VERSION "HNPBNNNYNNNNNNNNNNNNNNNNNNNNNNNNYNYYYYYYYY>4>%%%/4>'%**4YYY///"

NS_ :

BS_:

BU_: TPM TCM SCCM RF_HUB PTS ORC IC HaLF ETM ESM ESC EPS ECM Diagnost DTCM DASM CBC AFLS ADCM

BO_ 820 CBC_PT1: 8 CBC
 SG_ OR_SW_PSD : 0|2@1+ (1,0) [0|0] ""  ECM
 SG_ FT_FOG_RQ : 2|1@1+ (1,0) [0|0] ""  HaLF,AFLS,IC
 SG_ R_FOG_RQ : 3|1@1+ (1,0) [0|0] ""  IC
 SG_ REV_GEAR : 4|1@1+ (1,0) [0|0] ""  EPS,ORC,DTCM,ESC,TPM,PTS,IC,RF_HUB
 SG_ DR_LK_STAT : 5|2@1+ (1,0) [0|0] ""  RF_HUB
 SG_ IHC_ACT : 7|1@1+ (1,0) [0|0] ""  IC
 SG_ FOB_SrchRq : 8|2@1+ (1,0) [0|0] ""  RF_HUB
 SG_ HbrntnAct : 10|1@1+ (1,0) [0|0] ""  IC,RF_HUB
 SG_ ElecDrLkFT_LT : 11|1@1+ (1,0) [0|0] ""  ETM,RF_HUB
 SG_ ElecDrLkFT_RT : 12|1@1+ (1,0) [0|0] ""  ETM,RF_HUB
 SG_ AHB_SAE_Md : 13|1@1+ (1,0) [0|0] ""  IC
 SG_ AHB_ACT : 14|1@1+ (1,0) [0|0] ""  IC
 SG_ WSH_OUT_FLT : 15|1@1+ (1,0) [0|0] "" Vector__XXX
 SG_ PARK_LMP_ON : 16|1@1+ (1,0) [0|0] ""  IC
 SG_ DRV_AJAR : 17|1@1+ (1,0) [0|0] ""  TCM,ECM,DASM,ESC,IC,RF_HUB
 SG_ PSG_AJAR : 18|1@1+ (1,0) [0|0] ""  ORC,ECM,DASM,ESC,IC,RF_HUB
 SG_ L_R_AJAR : 19|1@1+ (1,0) [0|0] ""  ECM,ESC,IC,RF_HUB
 SG_ R_R_AJAR : 20|1@1+ (1,0) [0|0] ""  ECM,ESC,IC,RF_HUB
 SG_ FG_AJAR : 21|1@1+ (1,0) [0|0] ""  ECM,ESC,IC,RF_HUB
 SG_ TLG_AJAR : 22|1@1+ (1,0) [0|0] ""  ECM,ESC,IC,RF_HUB
 SG_ PARK_BRK_EGD : 23|1@1+ (1,0) [0|0] ""  ECM,DASM,ESC,PTS,IC
 SG_ IGN_OFF_TIME_LNG : 27|12@0+ (1,0) [0|4080] "min"  DTCM,TCM,ECM,DASM,ESC,IC,RF_HUB
 SG_ SHIP_STAT : 28|2@1+ (1,0) [0|0] ""  ORC,TPM,PTS,IC,RF_HUB
 SG_ TurnInd_LT_ON : 30|1@1+ (1,0) [0|0] ""  HaLF,DASM,PTS,IC
 SG_ TurnInd_RT_ON : 31|1@1+ (1,0) [0|0] ""  HaLF,DASM,PTS,IC
 SG_ DAY_LGT_MD : 40|1@1+ (1,0) [0|0] ""  ESM,SCCM,AFLS,PTS,IC,RF_HUB
 SG_ DISP_SYNC : 41|1@1+ (1,0) [0|0] ""  PTS
 SG_ PTC_REL1_STAT : 42|2@1+ (1,0) [0|0] ""  ECM
 SG_ PTC_REL2_STAT : 44|2@1+ (1,0) [0|0] ""  ECM
 SG_ PTC_REL3_STAT : 46|2@1+ (1,0) [0|0] ""  ECM
 SG_ PANEL_INTS : 48|8@1+ (0.5,0) [0|100] "%"  ESM,SCCM,PTS,IC,RF_HUB
 SG_ FT_WPR_NOT_PRK : 56|1@1+ (1,0) [0|0] ""  DTCM,ECM,AFLS
 SG_ LOBEAM_ON : 57|1@1+ (1,0) [0|0] ""  HaLF,ECM,AFLS,TPM,IC
 SG_ HIBEAM_ON : 58|1@1+ (1,0) [0|0] ""  HaLF,ECM,AFLS,IC
 SG_ PoliceStlthMdAct : 59|1@1+ (1,0) [0|0] ""  IC,RF_HUB
 SG_ TPM_SW_Psd : 60|1@1+ (1,0) [0|0] ""  TPM,RF_HUB
 SG_ ThatchamCBC : 61|1@1+ (1,0) [0|0] ""  RF_HUB
 SG_ BRK_FLUID_LO : 62|1@1+ (1,0) [0|0] ""  ETM,ESC,IC
 SG_ WASH_FLUID_LO : 63|1@1+ (1,0) [0|0] ""  ETM,IC

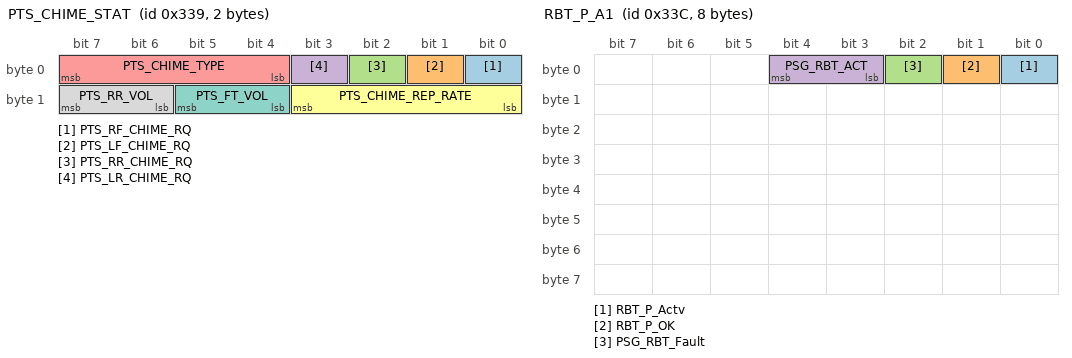
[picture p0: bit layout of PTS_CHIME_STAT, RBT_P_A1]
BO_ 825 PTS_CHIME_STAT: 2 PTS
 SG_ PTS_RF_CHIME_RQ : 0|1@1+ (1,0) [0|0] ""  CBC
 SG_ PTS_LF_CHIME_RQ : 1|1@1+ (1,0) [0|0] ""  CBC
 SG_ PTS_RR_CHIME_RQ : 2|1@1+ (1,0) [0|0] ""  CBC
 SG_ PTS_LR_CHIME_RQ : 3|1@1+ (1,0) [0|0] ""  CBC
 SG_ PTS_CHIME_TYPE : 4|4@1+ (1,0) [0|0] ""  CBC
 SG_ PTS_CHIME_REP_RATE : 8|4@1+ (1,0) [0|15] "Hz"  CBC
 SG_ PTS_FT_VOL : 12|2@1+ (1,0) [0|0] ""  CBC
 SG_ PTS_RR_VOL : 14|2@1+ (1,0) [0|0] ""  CBC

BO_ 826 PTS_1: 8 PTS
 SG_ PTS_DispRq : 0|1@1+ (1,0) [0|0] ""  IC
 SG_ PTS_CFG_STAT : 1|2@1+ (1,0) [0|0] ""  IC,CBC
 SG_ PTS_FT_NA : 3|1@1+ (1,0) [0|0] ""  IC
 SG_ PTS_RR_NA : 4|1@1+ (1,0) [0|0] ""  IC
 SG_ PTS_SRV_RQ : 5|1@1+ (1,0) [0|0] ""  IC
 SG_ PTS_MUTE_RQ : 6|1@1+ (1,0) [0|0] ""  CBC
 SG_ PTS_WARN : 7|1@1+ (1,0) [0|0] ""  IC,CBC
 SG_ PTS_AlrFL : 8|4@1+ (1,0) [0|0] ""  IC
 SG_ PTS_SoundFL : 12|2@1+ (1,0) [0|0] "" Vector__XXX
 SG_ PTS_GraphicFL : 14|2@1+ (1,0) [0|0] ""  IC
 SG_ PTS_AlrFR : 16|4@1+ (1,0) [0|0] ""  IC
 SG_ PTS_SoundFR : 20|2@1+ (1,0) [0|0] "" Vector__XXX
 SG_ PTS_GraphicFR : 22|2@1+ (1,0) [0|0] ""  IC
 SG_ PTS_AlrRL : 24|4@1+ (1,0) [0|0] ""  IC,CBC
 SG_ PTS_SoundRL : 28|2@1+ (1,0) [0|0] "" Vector__XXX
 SG_ PTS_GraphicRL : 30|2@1+ (1,0) [0|0] ""  IC
 SG_ PTS_AlrRR : 32|4@1+ (1,0) [0|0] ""  IC,CBC
 SG_ PTS_SoundRR : 36|2@1+ (1,0) [0|0] "" Vector__XXX
 SG_ PTS_GraphicRR : 38|2@1+ (1,0) [0|0] ""  IC
 SG_ PTS_AlrFC : 40|4@1+ (1,0) [0|0] ""  IC
 SG_ PTS_SoundFC : 44|2@1+ (1,0) [0|0] "" Vector__XXX
 SG_ PTS_GraphicFC : 46|2@1+ (1,0) [0|0] ""  IC
 SG_ PTS_AlrRC : 48|4@1+ (1,0) [0|0] ""  IC,CBC
 SG_ PTS_SoundRC : 52|2@1+ (1,0) [0|0] "" Vector__XXX
 SG_ PTS_GraphicRC : 54|2@1+ (1,0) [0|0] ""  IC
 SG_ PTS_FT_RDY : 56|1@1+ (1,0) [0|0] ""  IC
 SG_ PTS_RR_RDY : 57|1@1+ (1,0) [0|0] ""  IC
 SG_ PTS_FT_SRV : 58|1@1+ (1,0) [0|0] ""  IC
 SG_ PTS_RR_SRV : 59|1@1+ (1,0) [0|0] ""  IC
 SG_ PTS_STAT : 60|2@1+ (1,0) [0|0] ""  CBC
 SG_ PTS_FT_Enbl : 62|1@1+ (1,0) [0|0] ""  IC,CBC
 SG_ PTS_RR_Enbl : 63|1@1+ (1,0) [0|0] ""  IC,CBC

BO_ 828 RBT_P_A1: 8 Vector__XXX
 SG_ RBT_P_Actv : 0|1@1+ (1,0) [0|0] ""  ESC
 SG_ RBT_P_OK : 1|1@1+ (1,0) [0|0] ""  DASM,ESC
 SG_ PSG_RBT_Fault : 2|1@1+ (1,0) [0|0] ""  IC
 SG_ PSG_RBT_ACT : 3|2@1+ (1,0) [0|0] ""  DASM,ESC

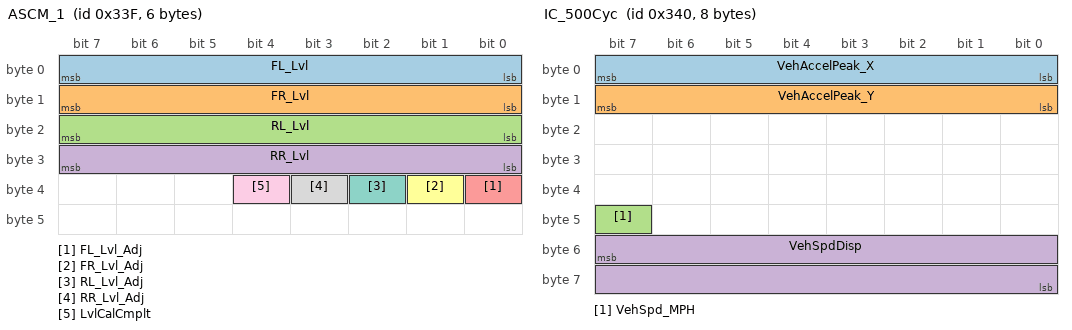
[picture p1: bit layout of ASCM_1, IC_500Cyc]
BO_ 831 ASCM_1: 6 Vector__XXX
 SG_ FL_Lvl : 0|8@1+ (1,-100) [-100|153] "mm"  ETM,HaLF,DASM,AFLS,IC,CBC
 SG_ FR_Lvl : 8|8@1+ (1,-100) [-100|153] "mm"  ETM,HaLF,DASM,AFLS,IC,CBC
 SG_ RL_Lvl : 16|8@1+ (1,-100) [-100|153] "mm"  ETM,HaLF,DASM,AFLS,IC,CBC
 SG_ RR_Lvl : 24|8@1+ (1,-100) [-100|153] "mm"  ETM,HaLF,DASM,AFLS,IC,CBC
 SG_ FL_Lvl_Adj : 32|1@1+ (1,0) [0|0] ""  HaLF,DASM,AFLS
 SG_ FR_Lvl_Adj : 33|1@1+ (1,0) [0|0] ""  HaLF,DASM,AFLS
 SG_ RL_Lvl_Adj : 34|1@1+ (1,0) [0|0] ""  HaLF,DASM,AFLS
 SG_ RR_Lvl_Adj : 35|1@1+ (1,0) [0|0] ""  HaLF,DASM,AFLS
 SG_ LvlCalCmplt : 36|1@1+ (1,0) [0|0] ""  HaLF,DASM,AFLS

BO_ 832 IC_500Cyc: 8 IC
 SG_ VehAccelPeak_X : 0|8@1+ (0.08,-10.24) [-10.24|10.08] "m/s²"  CBC
 SG_ VehAccelPeak_Y : 8|8@1+ (0.08,-10.24) [-10.24|10.08] "m/s²"  CBC
 SG_ VehSpd_MPH : 47|1@1+ (1,0) [0|0] ""  DASM,CBC
 SG_ VehSpdDisp : 55|16@0+ (1,0) [0|65534] ""  CBC

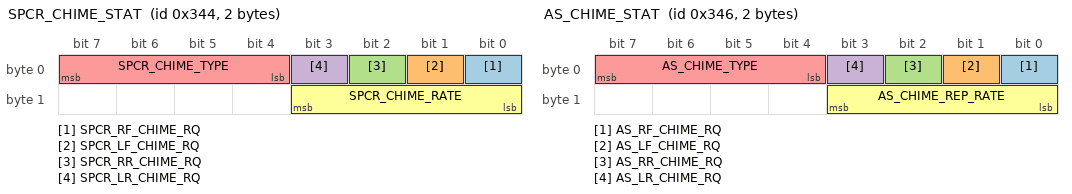
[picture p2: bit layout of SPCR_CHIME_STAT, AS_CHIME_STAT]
BO_ 836 SPCR_CHIME_STAT: 2 ESC
 SG_ SPCR_RF_CHIME_RQ : 0|1@1+ (1,0) [0|0] ""  CBC
 SG_ SPCR_LF_CHIME_RQ : 1|1@1+ (1,0) [0|0] ""  CBC
 SG_ SPCR_RR_CHIME_RQ : 2|1@1+ (1,0) [0|0] ""  CBC
 SG_ SPCR_LR_CHIME_RQ : 3|1@1+ (1,0) [0|0] ""  CBC
 SG_ SPCR_CHIME_TYPE : 4|4@1+ (1,0) [0|0] ""  CBC
 SG_ SPCR_CHIME_RATE : 8|4@1+ (1,0) [0|15] "Hz"  CBC

BO_ 838 AS_CHIME_STAT: 2 DASM
 SG_ AS_RF_CHIME_RQ : 0|1@1+ (1,0) [0|0] ""  CBC
 SG_ AS_LF_CHIME_RQ : 1|1@1+ (1,0) [0|0] ""  CBC
 SG_ AS_RR_CHIME_RQ : 2|1@1+ (1,0) [0|0] ""  CBC
 SG_ AS_LR_CHIME_RQ : 3|1@1+ (1,0) [0|0] ""  CBC
 SG_ AS_CHIME_TYPE : 4|4@1+ (1,0) [0|0] ""  ORC,IC,CBC
 SG_ AS_CHIME_REP_RATE : 8|4@1+ (1,0) [0|15] "Hz"  CBC

BO_ 840 ESP_C1: 8 ESC
 SG_ FailSafeError : 7|16@0+ (1,0) [0|65534] ""  DASM

BO_ 844 ASCM_2: 5 Vector__XXX
 SG_ ASCM_Stat : 0|4@1+ (1,0) [0|0] ""  ETM,HaLF,ESC,IC,CBC
 SG_ ASCM_StatDisp : 4|4@1+ (1,0) [0|0] ""  IC,CBC
 SG_ ASCM_HMI_Stat : 8|4@1+ (1,0) [0|0] ""  IC,CBC
 SG_ ASCM_Srv : 12|1@1+ (1,0) [0|0] ""  ESC,IC,CBC
 SG_ ASCM_SysFail : 13|1@1+ (1,0) [0|0] ""  IC,CBC
 SG_ ASCM_TJM : 14|1@1+ (1,0) [0|0] ""  IC,CBC
 SG_ ASCM_AeroDsbl : 15|1@1+ (1,0) [0|0] ""  IC,CBC
 SG_ Tgt_Level : 16|3@1+ (1,0) [0|0] ""  IC,CBC
 SG_ Loading_Lv : 19|3@1+ (1,0) [0|0] ""  ESC,IC,CBC
 SG_ ASCM_RemStat : 22|2@1+ (1,0) [0|0] ""  IC,CBC,RF_HUB
 SG_ ASCM_OR2_Rq : 24|2@1+ (1,0) [0|0] ""  IC,CBC
 SG_ ASCM_OR1_Rq : 26|2@1+ (1,0) [0|0] ""  IC,CBC
 SG_ ASCM_Norm_Rq : 28|2@1+ (1,0) [0|0] ""  IC,CBC
 SG_ ASCM_Exit_Rq : 30|2@1+ (1,0) [0|0] ""  IC,CBC
 SG_ ALM_Enbl : 32|1@1+ (1,0) [0|0] ""  IC,CBC
 SG_ WAL_Enbl : 33|1@1+ (1,0) [0|0] ""  IC,CBC
 SG_ ASCM_WarnOnly : 34|1@1+ (1,0) [0|0] ""  IC,CBC
 SG_ LvlAdjStat : 35|2@1+ (1,0) [0|0] ""  IC,CBC
 SG_ TM_Enbl : 37|1@1+ (1,0) [0|0] ""  IC,CBC
 SG_ LowShftToPark : 38|1@1+ (1,0) [0|0] ""  IC,CBC

BO_ 847 RFHUB_A4: 1 RF_HUB
 SG_ RFMemRq : 0|1@1+ (1,0) [0|0] ""  CBC
 SG_ RF_FobNum : 1|4@1+ (1,0) [0|0] ""  CBC

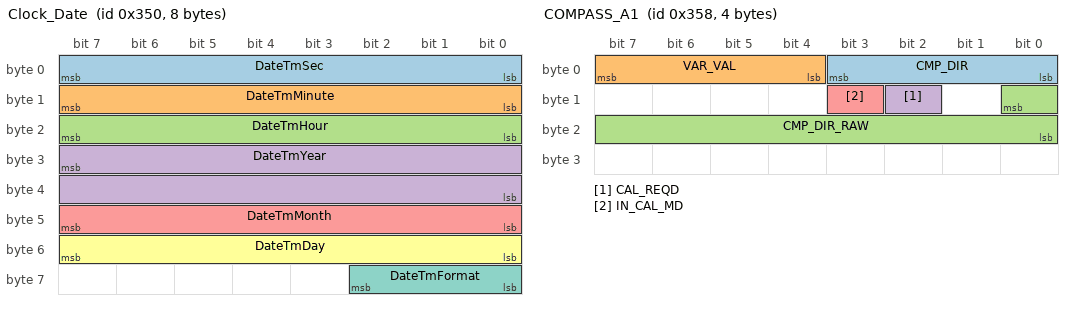
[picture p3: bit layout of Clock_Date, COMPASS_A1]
BO_ 848 Clock_Date: 8 CBC
 SG_ DateTmSec : 0|8@1+ (1,0) [0|59] "sec"  PTS,IC,RF_HUB
 SG_ DateTmMinute : 8|8@1+ (1,0) [0|59] "min"  PTS,IC,RF_HUB
 SG_ DateTmHour : 16|8@1+ (1,0) [0|23] "Hours"  PTS,IC,RF_HUB
 SG_ DateTmYear : 31|16@0+ (1,0) [0|65534] "Years"  TPM,PTS,IC,RF_HUB
 SG_ DateTmMonth : 40|8@1+ (1,0) [1|12] "Months"  TPM,PTS,IC,RF_HUB
 SG_ DateTmDay : 48|8@1+ (1,0) [1|31] "Days"  TPM,PTS,IC,RF_HUB
 SG_ DateTmFormat : 56|3@1+ (1,0) [0|0] ""  PTS,IC

BO_ 850 ECM_APPL2: 8 Diagnost
 SG_ ECM_APPL2 : 7|64@0+ (1,0) [0|0] ""  ECM

BO_ 853 GW_LIN_I_C1: 8 CBC
 SG_ TERRAIN_RQ : 0|2@1+ (1,0) [0|0] "" Vector__XXX
 SG_ TCASE_RQ : 2|2@1+ (1,0) [0|0] "" Vector__XXX
 SG_ TCASE_NEUT_RQ : 4|2@1+ (1,0) [0|0] ""  DTCM
 SG_ Tcase2WD_Rq : 6|2@1+ (1,0) [0|0] ""  DTCM
 SG_ TcaseAWD_Rq : 8|2@1+ (1,0) [0|0] ""  DTCM
 SG_ Tcase4Lock_Rq : 10|2@1+ (1,0) [0|0] ""  DTCM
 SG_ Tcase4Low_Rq : 12|2@1+ (1,0) [0|0] ""  DTCM
 SG_ TcaseSwTyp : 14|2@1+ (1,0) [0|0] ""  DTCM
 SG_ ASBM_AUX5_On : 18|1@1+ (1,0) [0|0] ""  ECM
 SG_ SuspSwPsd : 19|2@1+ (1,0) [0|0] "" Vector__XXX
 SG_ PARK_ASST_RQ : 21|2@1+ (1,0) [0|0] ""  PTS
 SG_ Ntrl_LED_Fail : 23|1@1+ (1,0) [0|0] ""  DTCM
 SG_ UGDO_CHNL : 24|3@1+ (1,0) [0|0] ""  IC
 SG_ UGDO_STAT : 27|4@1+ (1,0) [0|0] ""  IC
 SG_ Ch1_Stuck : 31|1@1+ (1,0) [0|0] ""  IC
 SG_ Ch2_Stuck : 32|1@1+ (1,0) [0|0] ""  IC
 SG_ Ch3_Stuck : 33|1@1+ (1,0) [0|0] ""  IC
 SG_ HL_Failure : 34|1@1+ (1,0) [0|0] ""  IC
 SG_ CLS_UnlkSw_Psd_D : 40|1@1+ (1,0) [0|0] "" Vector__XXX
 SG_ CLS_LkSw_Psd_D : 41|1@1+ (1,0) [0|0] "" Vector__XXX
 SG_ Converter_2_Mode : 42|2@1+ (1,0) [0|0] ""  ECM
 SG_ Converter_2_State : 44|2@1+ (1,0) [0|0] ""  ECM
 SG_ CLS_UnlkSw_Psd_P : 46|1@1+ (1,0) [0|0] "" Vector__XXX
 SG_ CLS_LkSw_Psd_P : 47|1@1+ (1,0) [0|0] "" Vector__XXX
 SG_ FT_PARK_ASST_RQ : 48|2@1+ (1,0) [0|0] ""  PTS
 SG_ SpSt_Pad1 : 50|3@1+ (1,0) [0|0] ""  ECM
 SG_ SpSt_Pad2 : 53|3@1+ (1,0) [0|0] ""  ECM
 SG_ IBS_IBATT_QUIESCENT : 56|8@1+ (0.00390625,0) [0|0.984375] "Amp" Vector__XXX

BO_ 856 COMPASS_A1: 4 CBC
 SG_ CMP_DIR : 0|4@1+ (1,0) [0|0] ""  IC
 SG_ VAR_VAL : 4|4@1+ (1,1) [1|15] ""  IC
 SG_ CMP_DIR_RAW : 8|9@0+ (1,0) [0|359] "Degrees"  IC
 SG_ CAL_REQD : 10|1@1+ (1,0) [0|0] ""  IC
 SG_ IN_CAL_MD : 11|1@1+ (1,0) [0|0] ""  IC

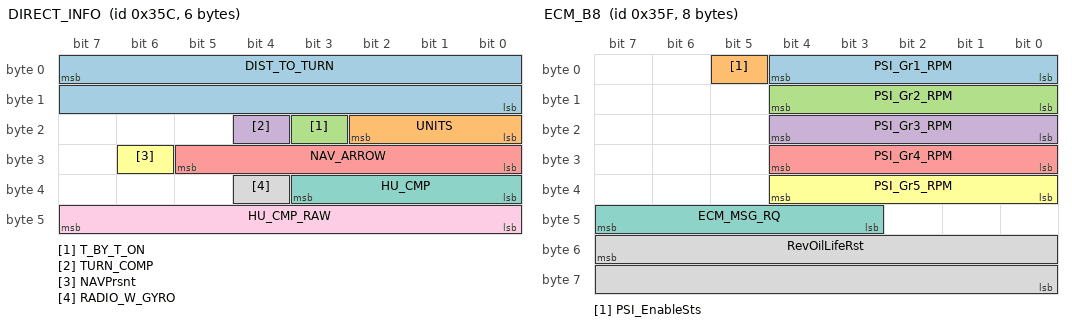
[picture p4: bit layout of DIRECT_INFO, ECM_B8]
BO_ 860 DIRECT_INFO: 6 CBC
 SG_ DIST_TO_TURN : 7|16@0+ (1,0) [0|65534] ""  IC
 SG_ UNITS : 16|3@1+ (1,0) [0|0] ""  IC
 SG_ T_BY_T_ON : 19|1@1+ (1,0) [0|0] ""  IC
 SG_ TURN_COMP : 20|1@1+ (1,0) [0|0] ""  IC
 SG_ NAV_ARROW : 24|6@1+ (1,0) [1|63] "Arrow"  IC
 SG_ NAVPrsnt : 30|1@1+ (1,0) [0|0] "" Vector__XXX
 SG_ HU_CMP : 32|4@1+ (1,0) [0|0] ""  IC
 SG_ RADIO_W_GYRO : 36|1@1+ (1,0) [0|0] ""  IC
 SG_ HU_CMP_RAW : 40|8@1+ (2,0) [0|360] "Degrees"  IC

BO_ 863 ECM_B8: 8 ECM
 SG_ PSI_Gr1_RPM : 0|5@1+ (250,500) [500|7500] "rpm"  ETM
 SG_ PSI_EnableSts : 5|1@1+ (1,0) [0|0] ""  CBC
 SG_ PSI_Gr2_RPM : 8|5@1+ (250,500) [500|7500] "rpm"  ETM
 SG_ PSI_Gr3_RPM : 16|5@1+ (250,500) [500|7500] "rpm"  ETM
 SG_ PSI_Gr4_RPM : 24|5@1+ (250,500) [500|7500] "rpm"  ETM
 SG_ PSI_Gr5_RPM : 32|5@1+ (250,500) [500|7500] "rpm"  ETM
 SG_ ECM_MSG_RQ : 43|5@1+ (1,0) [0|0] ""  CBC
 SG_ RevOilLifeRst : 55|16@0+ (1000,0) [0|65534000] "Rev's"  CBC

BO_ 864 ECM_APPL1: 8 ECM
 SG_ ECM_APPL1 : 7|64@0+ (1,0) [0|0] ""  Diagnost

BO_ 865 TCM_HS1: 8 Diagnost
 SG_ TCM_HS1 : 7|64@0+ (1,0) [0|0] ""  ECM

BO_ 866 TCM_HS2: 8 Diagnost
 SG_ TCM_HS2 : 7|64@0+ (1,0) [0|0] ""  ECM

BO_ 867 TCM_HS3: 8 Diagnost
 SG_ TCM_HS3 : 7|64@0+ (1,0) [0|0] ""  ECM

BO_ 868 MESS_TPM1: 8 TPM
 SG_ MESS_TPM1 : 7|64@0+ (1,0) [0|0] ""  Diagnost

BO_ 872 TCM_HSA: 8 ECM
 SG_ TCM_HSA : 7|64@0+ (1,0) [0|0] ""  Diagnost

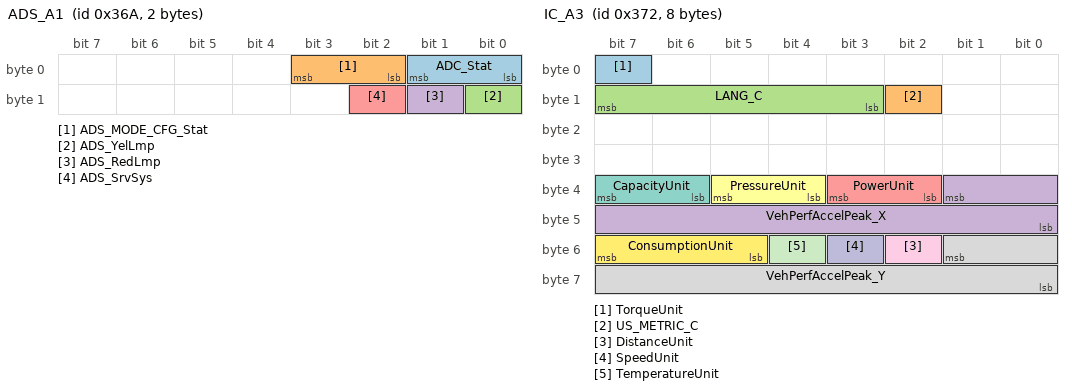
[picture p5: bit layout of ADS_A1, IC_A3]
BO_ 874 ADS_A1: 2 ADCM
 SG_ ADC_Stat : 0|2@1+ (1,0) [0|0] ""  DASM,ESC,IC,CBC
 SG_ ADS_MODE_CFG_Stat : 2|2@1+ (1,0) [0|0] ""  IC,CBC
 SG_ ADS_YelLmp : 8|1@1+ (1,0) [0|0] ""  IC,CBC
 SG_ ADS_RedLmp : 9|1@1+ (1,0) [0|0] ""  IC,CBC
 SG_ ADS_SrvSys : 10|1@1+ (1,0) [0|0] ""  IC,CBC

BO_ 880 ECM_APPL3: 8 ECM
 SG_ ECM_APPL3 : 7|64@0+ (1,0) [0|0] ""  Diagnost

BO_ 882 IC_A3: 8 IC
 SG_ TorqueUnit : 7|1@1+ (1,0) [0|0] ""  ECM,CBC
 SG_ US_METRIC_C : 10|1@1+ (1,0) [0|0] ""  ECM,DASM,CBC
 SG_ LANG_C : 11|5@1+ (1,0) [0|0] ""  CBC
 SG_ VehPerfAccelPeak_X : 33|10@0+ (0.08,-40.88) [-40.88|40.88] "m/s²"  ETM
 SG_ PowerUnit : 34|2@1+ (1,0) [0|0] ""  ECM,CBC
 SG_ PressureUnit : 36|2@1+ (1,0) [0|0] ""  ECM,CBC
 SG_ CapacityUnit : 38|2@1+ (1,0) [0|0] ""  ECM,CBC
 SG_ VehPerfAccelPeak_Y : 49|10@0+ (0.08,-40.88) [-40.88|40.88] "m/s²"  ETM
 SG_ DistanceUnit : 50|1@1+ (1,0) [0|0] ""  ECM,CBC
 SG_ SpeedUnit : 51|1@1+ (1,0) [0|0] ""  ECM,DASM,CBC
 SG_ TemperatureUnit : 52|1@1+ (1,0) [0|0] ""  ECM,CBC
 SG_ ConsumptionUnit : 53|3@1+ (1,0) [0|0] ""  ECM,CBC

BO_ 888 TCM_HSB: 8 ECM
 SG_ TCM_HSB : 7|64@0+ (1,0) [0|0] ""  Diagnost

BO_ 896 ECM_APPL4: 8 ECM
 SG_ ECM_APPL4 : 7|64@0+ (1,0) [0|0] ""  Diagnost

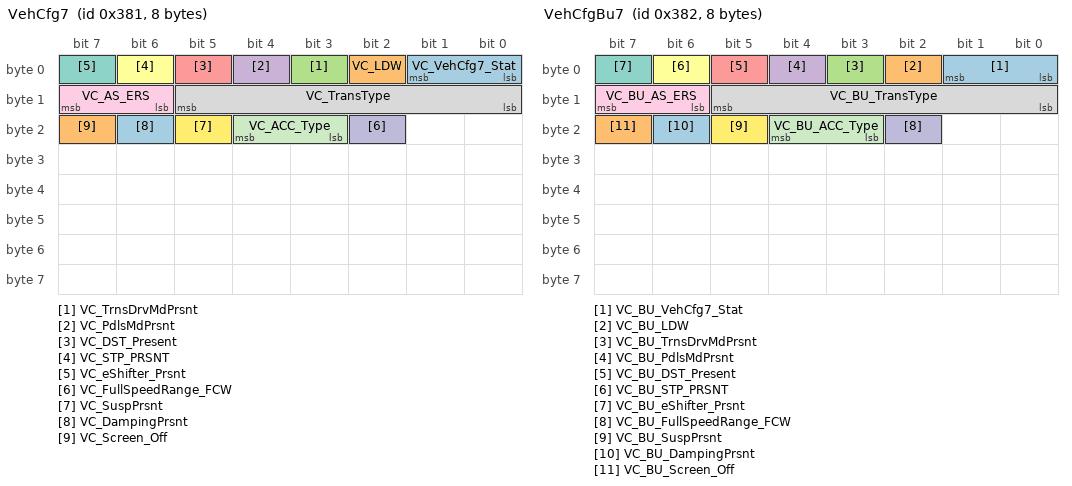
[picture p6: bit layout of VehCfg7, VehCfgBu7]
BO_ 897 VehCfg7: 8 CBC
 SG_ VC_VehCfg7_Stat : 0|2@1+ (1,0) [0|0] ""  HaLF,DTCM,TCM,ECM,DASM,ESC,IC,RF_HUB
 SG_ VC_LDW : 2|1@1+ (1,0) [0|0] ""  EPS,HaLF,RF_HUB
 SG_ VC_TrnsDrvMdPrsnt : 3|1@1+ (1,0) [0|0] ""  TCM,IC,RF_HUB
 SG_ VC_PdlsMdPrsnt : 4|1@1+ (1,0) [0|0] ""  TCM,IC,RF_HUB
 SG_ VC_DST_Present : 5|1@1+ (1,0) [0|0] ""  EPS,RF_HUB
 SG_ VC_STP_PRSNT : 6|1@1+ (1,0) [0|0] ""  IC,RF_HUB
 SG_ VC_eShifter_Prsnt : 7|1@1+ (1,0) [0|0] ""  RF_HUB
 SG_ VC_TransType : 8|6@1+ (1,0) [0|0] ""  DTCM,ESC,IC,RF_HUB
 SG_ VC_AS_ERS : 14|2@1+ (1,0) [0|0] ""  TCM,ECM,IC,RF_HUB
 SG_ VC_FullSpeedRange_FCW : 18|1@1+ (1,0) [0|0] ""  DASM,RF_HUB
 SG_ VC_ACC_Type : 19|2@1+ (1,0) [0|0] ""  DASM,RF_HUB
 SG_ VC_SuspPrsnt : 21|1@1+ (1,0) [0|0] ""  DASM,ESC,IC,RF_HUB
 SG_ VC_DampingPrsnt : 22|1@1+ (1,0) [0|0] ""  DASM,ESC,IC,RF_HUB
 SG_ VC_Screen_Off : 23|1@1+ (1,0) [0|0] ""  RF_HUB

BO_ 898 VehCfgBu7: 8 RF_HUB
 SG_ VC_BU_VehCfg7_Stat : 0|2@1+ (1,0) [0|0] ""  CBC
 SG_ VC_BU_LDW : 2|1@1+ (1,0) [0|0] ""  CBC
 SG_ VC_BU_TrnsDrvMdPrsnt : 3|1@1+ (1,0) [0|0] ""  CBC
 SG_ VC_BU_PdlsMdPrsnt : 4|1@1+ (1,0) [0|0] ""  CBC
 SG_ VC_BU_DST_Present : 5|1@1+ (1,0) [0|0] ""  CBC
 SG_ VC_BU_STP_PRSNT : 6|1@1+ (1,0) [0|0] ""  CBC
 SG_ VC_BU_eShifter_Prsnt : 7|1@1+ (1,0) [0|0] ""  CBC
 SG_ VC_BU_TransType : 8|6@1+ (1,0) [0|0] ""  CBC
 SG_ VC_BU_AS_ERS : 14|2@1+ (1,0) [0|0] ""  CBC
 SG_ VC_BU_FullSpeedRange_FCW : 18|1@1+ (1,0) [0|0] ""  CBC
 SG_ VC_BU_ACC_Type : 19|2@1+ (1,0) [0|0] ""  CBC
 SG_ VC_BU_SuspPrsnt : 21|1@1+ (1,0) [0|0] ""  CBC
 SG_ VC_BU_DampingPrsnt : 22|1@1+ (1,0) [0|0] ""  CBC
 SG_ VC_BU_Screen_Off : 23|1@1+ (1,0) [0|0] ""  CBC

CM_ SG_ 820 OR_SW_PSD "Off Road switch pressed";
CM_ SG_ 820 FT_FOG_RQ "Front fog request; off=[0], on=[1]";
CM_ SG_ 820 R_FOG_RQ "Rear fog request; [0] = off, [1] = on";
CM_ SG_ 820 REV_GEAR "Reverse Gear (manual trans)";
CM_ SG_ 820 DR_LK_STAT "Door lock status";
CM_ SG_ 820 IHC_ACT "Intelligent headlight control active";
CM_ SG_ 820 FOB_SrchRq "FOB search request";
CM_ SG_ 820 HbrntnAct "Hibernation active (1=hibernation)";
CM_ SG_ 820 ElecDrLkFT_LT "Door lock status, Front Left (1=locked)";
CM_ SG_ 820 ElecDrLkFT_RT "Door lock status, Front right (1=locked)";
CM_ SG_ 820 AHB_SAE_Md "Automatic high beam is in regulatory SAE mode";
CM_ SG_ 820 AHB_ACT "Automatic high beam active";
CM_ SG_ 820 WSH_OUT_FLT "Washer Output Fault (1=faulted)";
CM_ SG_ 820 PARK_LMP_ON "Parklamps are on; off=[0], on=[1]";
CM_ SG_ 820 DRV_AJAR "Driver door ajar";
CM_ SG_ 820 PSG_AJAR "Passenger door ajar";
CM_ SG_ 820 L_R_AJAR "Left rear door ajar";
CM_ SG_ 820 R_R_AJAR "Right rear door ajar";
CM_ SG_ 820 FG_AJAR "Flipper glass ajar";
CM_ SG_ 820 TLG_AJAR "Trunk/Liftgate ajar";
CM_ SG_ 820 PARK_BRK_EGD "Park brake switch engaged";
CM_ SG_ 820 IGN_OFF_TIME_LNG "Time since last ignition on (long)";
CM_ SG_ 820 SHIP_STAT "Shipping status";
CM_ SG_ 820 TurnInd_LT_ON "Turn indication left is on";
CM_ SG_ 820 TurnInd_RT_ON "Turn indication right is on";
CM_ SG_ 820 DAY_LGT_MD "Day light brightness mode; Night=[0], Day=[1]";
CM_ SG_ 820 DISP_SYNC "Turn on displays";
CM_ SG_ 820 PTC_REL1_STAT "PTC Relay # 1 Status (diesel only)";
CM_ SG_ 820 PTC_REL2_STAT "PTC Relay # 2 Status (diesel only)";
CM_ SG_ 820 PTC_REL3_STAT "PTC Relay # 3 Status (diesel only)";
CM_ SG_ 820 PANEL_INTS "Panel-/display intensity";
CM_ SG_ 820 FT_WPR_NOT_PRK "Front wiper outside park position";
CM_ SG_ 820 LOBEAM_ON "Low beam is on; off=[0], on=[1]";
CM_ SG_ 820 HIBEAM_ON "High beam is on; off=[0], on=[1]";
CM_ SG_ 820 PoliceStlthMdAct "Police stealth mode active; true = [1]";
CM_ SG_ 820 TPM_SW_Psd "Tire Pressure Monitor Switch Status, Pressed = [1]";
CM_ SG_ 820 ThatchamCBC "CBC has learned the presence of Thatcham; true = [1]";
CM_ SG_ 820 BRK_FLUID_LO "Low brake fluid warning; low = [1]";
CM_ SG_ 820 WASH_FLUID_LO "Low washer fluid warning (1=Fluid is low)";
CM_ SG_ 825 PTS_RF_CHIME_RQ "PTS right front chime on request; True = [1]";
CM_ SG_ 825 PTS_LF_CHIME_RQ "PTS left front chime on request; True = [1]";
CM_ SG_ 825 PTS_RR_CHIME_RQ "PTS right rear chime on request; True = [1]";
CM_ SG_ 825 PTS_LR_CHIME_RQ "PTS left rear chime on request; True = [1]";
CM_ SG_ 825 PTS_CHIME_TYPE "PTS chime type";
CM_ SG_ 825 PTS_CHIME_REP_RATE "PTS chime repetition rate";
CM_ SG_ 825 PTS_FT_VOL "PTS Front Volume Setting";
CM_ SG_ 825 PTS_RR_VOL "PTS Rear Volume Setting";
CM_ SG_ 826 PTS_DispRq "PTS display is on = [1], off = [0]";
CM_ SG_ 826 PTS_CFG_STAT "Park assist configuration status";
CM_ SG_ 826 PTS_FT_NA "Front park assist not available - blinded sensor; True = [1]";
CM_ SG_ 826 PTS_RR_NA "Rear park assist not available - blinded sensor; True = [1]";
CM_ SG_ 826 PTS_SRV_RQ "PTS service warning request; True = [1]";
CM_ SG_ 826 PTS_MUTE_RQ "Audio system mute request from PTS; True = [1]";
CM_ SG_ 826 PTS_WARN "PTS warning is on = [0], off = [1]";
CM_ SG_ 826 PTS_AlrFL "PTS alert front left";
CM_ SG_ 826 PTS_SoundFL "PTS sound alert front left";
CM_ SG_ 826 PTS_GraphicFL "PTS graphic flash rate front left";
CM_ SG_ 826 PTS_AlrFR "PTS alert front right";
CM_ SG_ 826 PTS_SoundFR "PTS sound alert front right";
CM_ SG_ 826 PTS_GraphicFR "PTS graphic flash rate front right";
CM_ SG_ 826 PTS_AlrRL "PTS alert rear left";
CM_ SG_ 826 PTS_SoundRL "PTS sound alert rear left";
CM_ SG_ 826 PTS_GraphicRL "PTS graphic flash rate rear left";
CM_ SG_ 826 PTS_AlrRR "PTS alert rear right";
CM_ SG_ 826 PTS_SoundRR "PTS sound alert rear right";
CM_ SG_ 826 PTS_GraphicRR "PTS graphic flash rate rear right";
CM_ SG_ 826 PTS_AlrFC "PTS alert front center";
CM_ SG_ 826 PTS_SoundFC "PTS sound alert front center";
CM_ SG_ 826 PTS_GraphicFC "PTS graphic flash rate front center";
CM_ SG_ 826 PTS_AlrRC "PTS alert rear center";
CM_ SG_ 826 PTS_SoundRC "PTS sound alert rear center";
CM_ SG_ 826 PTS_GraphicRC "PTS graphic flash rate rear center";
CM_ SG_ 826 PTS_FT_RDY "Front PTS sensor ready request; True = [1]";
CM_ SG_ 826 PTS_RR_RDY "Rear PTS sensor ready request; True = [1]";
CM_ SG_ 826 PTS_FT_SRV "Front PTS sensor service request; True = [1]";
CM_ SG_ 826 PTS_RR_SRV "Rear PTS sensor service request; True = [1]";
CM_ SG_ 826 PTS_STAT "Park Assist System - LED control status";
CM_ SG_ 826 PTS_FT_Enbl "Front PTS system enabled/disabled status; enable = [1]";
CM_ SG_ 826 PTS_RR_Enbl "Rear PTS system enabled/disabled status; enable = [1]";
CM_ SG_ 828 RBT_P_Actv "Reversible belt tensioner passenger active; True = [1]";
CM_ SG_ 828 RBT_P_OK "Reversible belt tensioner passenger is OK; True = [1]";
CM_ SG_ 828 PSG_RBT_Fault "Passenger's RBT has a fault or failure; True = [1]";
CM_ SG_ 828 PSG_RBT_ACT "Indicates the pre-pretensioner is activated either by the DASM or ESC";
CM_ SG_ 831 FL_Lvl "Front left level";
CM_ SG_ 831 FR_Lvl "Front right level";
CM_ SG_ 831 RL_Lvl "Rear left level";
CM_ SG_ 831 RR_Lvl "Rear right level";
CM_ SG_ 831 FL_Lvl_Adj "Front left level adjust (1=adjusting)";
CM_ SG_ 831 FR_Lvl_Adj "Front right level adjust (1=adjusting)";
CM_ SG_ 831 RL_Lvl_Adj "Rear left level adjust (1=adjusting)";
CM_ SG_ 831 RR_Lvl_Adj "Rear right level adjust (1=adjusting)";
CM_ SG_ 831 LvlCalCmplt "Level calibration complete";
CM_ SG_ 832 VehAccelPeak_X "Vehicle longitudinal acceleration peak (+ means forward)";
CM_ SG_ 832 VehAccelPeak_Y "Vehicle lateral acceleration peak (+ means left)";
CM_ SG_ 832 VehSpd_MPH "Vehicle speed signal is in miles per hour format";
CM_ SG_ 832 VehSpdDisp "Vehicle speed - displayed";
CM_ SG_ 836 SPCR_RF_CHIME_RQ "SPCR right front chime on request";
CM_ SG_ 836 SPCR_LF_CHIME_RQ "SPCR left front chime on request";
CM_ SG_ 836 SPCR_RR_CHIME_RQ "SPCR right rear chime on request";
CM_ SG_ 836 SPCR_LR_CHIME_RQ "SPCR left rear chime on request";
CM_ SG_ 836 SPCR_CHIME_TYPE "SPCR chime type";
CM_ SG_ 836 SPCR_CHIME_RATE "SPCR chime repetition rate";
CM_ SG_ 838 AS_RF_CHIME_RQ "AS right front chime on request; True = [1]";
CM_ SG_ 838 AS_LF_CHIME_RQ "AS left front chime on request; True = [1]";
CM_ SG_ 838 AS_RR_CHIME_RQ "AS right rear chime on request; True = [1]";
CM_ SG_ 838 AS_LR_CHIME_RQ "AS left rear chime on request; True = [1]";
CM_ SG_ 838 AS_CHIME_TYPE "AS chime type";
CM_ SG_ 838 AS_CHIME_REP_RATE "AS chime repetition rate";
CM_ SG_ 840 FailSafeError "Fail safe error";
CM_ SG_ 844 ASCM_Stat "Air suspension status";
CM_ SG_ 844 ASCM_StatDisp "Air suspension status for display";
CM_ SG_ 844 ASCM_HMI_Stat "ASCM HMI status";
CM_ SG_ 844 ASCM_Srv "Service air suspension; 1 = True";
CM_ SG_ 844 ASCM_SysFail "Loss of function - system fault; 1 = True";
CM_ SG_ 844 ASCM_TJM "Tire jack mode; 1 = True";
CM_ SG_ 844 ASCM_AeroDsbl "Aero mode disabled; Enable aero mode = [1]";
CM_ SG_ 844 Tgt_Level "Target Level";
CM_ SG_ 844 Loading_Lv "Loading level";
CM_ SG_ 844 ASCM_RemStat "ASCM remote lowering status";
CM_ SG_ 844 ASCM_OR2_Rq "Request for off road 2 indicator  (M161 use this for Aero LED)";
CM_ SG_ 844 ASCM_OR1_Rq "Request for off road 1 indicator";
CM_ SG_ 844 ASCM_Norm_Rq "Request for normal indicator";
CM_ SG_ 844 ASCM_Exit_Rq "Request for exit (Trailer_ HD) indicator";
CM_ SG_ 844 ALM_Enbl "Auto load measurement enabled; 1 = True";
CM_ SG_ 844 WAL_Enbl "Wheel alignment level enabled; 1 = True";
CM_ SG_ 844 ASCM_WarnOnly "ASCM warning messages only; 1 = True";
CM_ SG_ 844 LvlAdjStat "Level adjustment status";
CM_ SG_ 844 TM_Enbl "Transport mode enabled; 1 = True";
CM_ SG_ 844 LowShftToPark "Entry/exit auto lower by shift to park; true = [1]";
CM_ SG_ 847 RFMemRq "RF memory request; [1] = True";
CM_ SG_ 847 RF_FobNum "FOB number making the request";
CM_ SG_ 848 DateTmSec "Time of day: SECONDS";
CM_ SG_ 848 DateTmMinute "Time of day: MINUTES";
CM_ SG_ 848 DateTmHour "Time of day: HOURS";
CM_ SG_ 848 DateTmYear "Date year";
CM_ SG_ 848 DateTmMonth "Month";
CM_ SG_ 848 DateTmDay "Day";
CM_ SG_ 848 DateTmFormat "Date and Time Format";
CM_ SG_ 850 ECM_APPL2 "Application";
CM_ SG_ 853 TERRAIN_RQ "Terrain setting request";
CM_ SG_ 853 TCASE_RQ "Transfer case request";
CM_ SG_ 853 TCASE_NEUT_RQ "Transfer case neutral request";
CM_ SG_ 853 Tcase2WD_Rq "Transfer case 2 wheel drive request";
CM_ SG_ 853 TcaseAWD_Rq "Transfer case all wheel drive request";
CM_ SG_ 853 Tcase4Lock_Rq "Transfer case 4 wheel lock request";
CM_ SG_ 853 Tcase4Low_Rq "Transfer case 4 wheel low request";
CM_ SG_ 853 TcaseSwTyp "Transfer case LIN switch type";
CM_ SG_ 853 ASBM_AUX5_On "Aux Switch 5 Status ON";
CM_ SG_ 853 SuspSwPsd "Suspension switch pressed";
CM_ SG_ 853 PARK_ASST_RQ "Park Assist Request";
CM_ SG_ 853 Ntrl_LED_Fail "Neutral LED failure";
CM_ SG_ 853 UGDO_CHNL "UGDO channel";
CM_ SG_ 853 UGDO_STAT "UGDO status";
CM_ SG_ 853 Ch1_Stuck "Channel 1 is stuck";
CM_ SG_ 853 Ch2_Stuck "Channel 2 is stuck";
CM_ SG_ 853 Ch3_Stuck "Channel 3 is stuck";
CM_ SG_ 853 HL_Failure "HomeLink Failure";
CM_ SG_ 853 CLS_UnlkSw_Psd_D "Central locking system unlock switch pressed - driver side";
CM_ SG_ 853 CLS_LkSw_Psd_D "Central locking system lock switch pressed - driver side";
CM_ SG_ 853 Converter_2_Mode "DC-DC converter_2 mode";
CM_ SG_ 853 Converter_2_State "DC-DC converter_2  state";
CM_ SG_ 853 CLS_UnlkSw_Psd_P "Central locking system unlock switch pressed - passenger side";
CM_ SG_ 853 CLS_LkSw_Psd_P "Central locking system lock switch pressed - passenger side";
CM_ SG_ 853 FT_PARK_ASST_RQ "Front park assist request";
CM_ SG_ 853 SpSt_Pad1 "Stop / start switch - pad 1";
CM_ SG_ 853 SpSt_Pad2 "Stop / start switch - pad 2";
CM_ SG_ 853 IBS_IBATT_QUIESCENT "Battery quiescent current";
CM_ SG_ 856 CMP_DIR "Compass direction (WK/LX)";
CM_ SG_ 856 VAR_VAL "RCM Variance Value";
CM_ SG_ 856 CMP_DIR_RAW "Compass direction raw";
CM_ SG_ 856 CAL_REQD "Calibration needed";
CM_ SG_ 856 IN_CAL_MD "In Calibration Mode";
CM_ SG_ 860 DIST_TO_TURN "Numeric distance to next turn";
CM_ SG_ 860 UNITS "Unit of measure";
CM_ SG_ 860 T_BY_T_ON "Turn by turn on";
CM_ SG_ 860 TURN_COMP "Turn complete";
CM_ SG_ 860 NAV_ARROW "Navigation arrow type";
CM_ SG_ 860 NAVPrsnt "A navigation system module is present";
CM_ SG_ 860 HU_CMP "Radio compass direction";
CM_ SG_ 860 RADIO_W_GYRO "Radio with gyro (1=present)";
CM_ SG_ 860 HU_CMP_RAW "Compass direction raw";
CM_ SG_ 863 PSI_Gr1_RPM "Actual rpm set point for performance shift indication; 500 indicates not set";
CM_ SG_ 863 PSI_EnableSts "Performance shift indication enabled status; enabled = [1]";
CM_ SG_ 863 PSI_Gr2_RPM "Actual rpm set point for performance shift indication; 500 indicates not set";
CM_ SG_ 863 PSI_Gr3_RPM "Actual rpm set point for performance shift indication; 500 indicates not set";
CM_ SG_ 863 PSI_Gr4_RPM "Actual rpm set point for performance shift indication; 500 indicates not set";
CM_ SG_ 863 PSI_Gr5_RPM "Actual rpm set point for performance shift indication; 500 indicates not set";
CM_ SG_ 863 ECM_MSG_RQ "ECM Driver Instruction Messages";
CM_ SG_ 863 RevOilLifeRst "Engine revolutions since last oil life reset";
CM_ SG_ 864 ECM_APPL1 "Application";
CM_ SG_ 865 TCM_HS1 "Manual control at test bench";
CM_ SG_ 866 TCM_HS2 "Manual control at test bench";
CM_ SG_ 867 TCM_HS3 "Manual control at test bench";
CM_ SG_ 868 MESS_TPM1 "Measurement data";
CM_ SG_ 872 TCM_HSA "Manual control at test bench";
CM_ SG_ 874 ADC_Stat "Active damping control status";
CM_ SG_ 874 ADS_MODE_CFG_Stat "Default setting - ADS Mode";
CM_ SG_ 874 ADS_YelLmp "ADS yellow lamp on request; on=[1]";
CM_ SG_ 874 ADS_RedLmp "ADS red lamp on request; on=[1]";
CM_ SG_ 874 ADS_SrvSys "ADS service system; True = [1]";
CM_ SG_ 880 ECM_APPL3 "CCP synchronous - TDC event DAQ";
CM_ SG_ 882 TorqueUnit "Torque units; Foot Pounds (ft-lb) = [1]";
CM_ SG_ 882 US_METRIC_C "US = [0], metric = [1]";
CM_ SG_ 882 LANG_C "Language preference (5 bit)";
CM_ SG_ 882 VehPerfAccelPeak_X "Vehicle longitudinal acceleration peak (+ means forward)";
CM_ SG_ 882 PowerUnit "Power units";
CM_ SG_ 882 PressureUnit "Pressure units";
CM_ SG_ 882 CapacityUnit "Fuel capacity units";
CM_ SG_ 882 VehPerfAccelPeak_Y "Vehicle lateral acceleration peak (+ means left)";
CM_ SG_ 882 DistanceUnit "Distance (odometer) units; Miles = [1]";
CM_ SG_ 882 SpeedUnit "Speed (speedometer) units; Miles = [1]";
CM_ SG_ 882 TemperatureUnit "Temperature units; Farenheit = [1]";
CM_ SG_ 882 ConsumptionUnit "Fuel consumption units";
CM_ SG_ 888 TCM_HSB "Manual control at test bench";
CM_ SG_ 896 ECM_APPL4 "CCP 5ms DAQ  (from ENGINE to external tool)";
CM_ SG_ 897 VC_VehCfg7_Stat "Configuration messages status 7";
CM_ SG_ 897 VC_LDW "Lane Departure Warning present; present = [1]";
CM_ SG_ 897 VC_TrnsDrvMdPrsnt "Transmission drive mode feature; present = [1]";
CM_ SG_ 897 VC_PdlsMdPrsnt "Paddles lock-out feature; present = [1]";
CM_ SG_ 897 VC_DST_Present "Dynamic steering torque present; True = [1]";
CM_ SG_ 897 VC_STP_PRSNT "Super trac pack present; True = [1]";
CM_ SG_ 897 VC_eShifter_Prsnt "e-shifter present; present = [1]";
CM_ SG_ 897 VC_TransType "Automatic transmission type";
CM_ SG_ 897 VC_AS_ERS "Shift feature autostick / electronic range select status";
CM_ SG_ 897 VC_FullSpeedRange_FCW "Full speed range forward collision warning plus system present; Present = 1";
CM_ SG_ 897 VC_ACC_Type "Type of adaptive cruise control (ACC) system present";
CM_ SG_ 897 VC_SuspPrsnt "NetCfg_ASCM contains suspension; present = [1]";
CM_ SG_ 897 VC_DampingPrsnt "NetCfg_ASCM contains active damping; present = [1]";
CM_ SG_ 897 VC_Screen_Off "Vehicle is equipped with a screen off soft button; present = [1]";
CM_ SG_ 898 VC_BU_VehCfg7_Stat "Backup for Configuration messages status 7";
CM_ SG_ 898 VC_BU_LDW "Lane departure warning present; present = [1]";
CM_ SG_ 898 VC_BU_TrnsDrvMdPrsnt "Backup for transmission drive mode feature; present = [1]";
CM_ SG_ 898 VC_BU_PdlsMdPrsnt "Backup for paddles lock-out feature; present = [1]";
CM_ SG_ 898 VC_BU_DST_Present "Backup for dynamic steering torque present; True = [1]";
CM_ SG_ 898 VC_BU_STP_PRSNT "Backup for super trac pack present; True = [1]";
CM_ SG_ 898 VC_BU_eShifter_Prsnt "Backup for e-shifter present; present = [1]";
CM_ SG_ 898 VC_BU_TransType "Backup for automatic transmission type";
CM_ SG_ 898 VC_BU_AS_ERS "Backup for shift feature autostick / electronic range select status";
CM_ SG_ 898 VC_BU_FullSpeedRange_FCW "Backup for full speed range forward collision warning plus system present; Present = 1";
CM_ SG_ 898 VC_BU_ACC_Type "Backup for type of adaptive cruise control (ACC) system present";
CM_ SG_ 898 VC_BU_SuspPrsnt "backup for ASCM contains suspension; present = [1]";
CM_ SG_ 898 VC_BU_DampingPrsnt "Backup for ASCM contains active damping; present = [1]";
CM_ SG_ 898 VC_BU_Screen_Off "Backup for equipped with a screen off soft button; present = [1]";
BA_DEF_ SG_  "GenSigTimeout_ADCM" INT 0 65535;
BA_DEF_ SG_  "GenSigTimeout_AFLS" INT 0 65535;
BA_DEF_ SG_  "GenSigTimeout_CBC" INT 0 65535;
BA_DEF_ SG_  "GenSigTimeout_DTCM" INT 0 65535;
BA_DEF_ SG_  "GenSigTimeout_ECM" INT 0 65535;
BA_DEF_ SG_  "GenSigTimeout_EPS" INT 0 65535;
BA_DEF_ SG_  "GenSigTimeout_ESC" INT 0 65535;
BA_DEF_ SG_  "GenSigTimeout_ESM" INT 0 65535;
BA_DEF_ SG_  "GenSigTimeout_ETM" INT 0 65535;
BA_DEF_ SG_  "GenSigTimeout_HaLF" INT 0 65535;
BA_DEF_ SG_  "GenSigTimeout_IC" INT 0 65535;
BA_DEF_ SG_  "GenSigTimeout_ORC" INT 0 65535;
BA_DEF_ SG_  "GenSigTimeout_PTS" INT 0 65535;
BA_DEF_ SG_  "GenSigTimeout_RF_HUB" INT 0 65535;
BA_DEF_ SG_  "GenSigTimeout_SCCM" INT 0 65535;
BA_DEF_ SG_  "GenSigTimeout_TPM" INT 0 65535;
BA_DEF_ BO_  "GenMsgStartValue" STRING ;
BA_DEF_ SG_  "GenSigSNA" STRING ;
BA_DEF_ SG_  "FlexKomIsMotorola" ENUM  "nein","ja";
BA_DEF_ SG_  "FlexKomSigLaenge" INT 0 64;
BA_DEF_ SG_  "FlexKomSigStartPos" INT 0 63;
BA_DEF_ SG_  "FlexKomComment" STRING ;
BA_DEF_ SG_  "FlexKomSigName" STRING ;
BA_DEF_ SG_  "FlexKomSID" INT 0 2147483647;
BA_DEF_ SG_  "GenSigStartValue" HEX 0 4294967295;
BA_DEF_ SG_  "FlexKomSigStartValue" STRING ;
BA_DEF_ SG_  "GenSigCycleTimeActive" INT 0 65535;
BA_DEF_ SG_  "GenSigCycleTime" INT 0 65535;
BA_DEF_ SG_  "GenSigSendType" ENUM  "cyclicX","spontanX","cyclicIfActiveX","spontanWithDelay","cyclicAndSpontanX","cyclicAndSpontanWithDelay","spontanWithRepitition","cyclicIfActiveAndSpontanWD","cyclicIfActiveFast","cyclicWithRepeatOnDemand","none";
BA_DEF_ BO_  "GenMsgNrOfRepetitions" INT 0 65535;
BA_DEF_ BO_  "GenMsgDelayTime" INT 0 65535;
BA_DEF_ BO_  "GenMsgStartDelayTime" INT 0 65535;
BA_DEF_ BO_  "GenMsgCycleTimeActive" INT 0 65535;
BA_DEF_ BO_  "GenMsgCycleTime" INT 0 65535;
BA_DEF_ BO_  "GenMsgSendType" ENUM  "cyclicX","spontanX","cyclicIfActiveX","spontanWithDelay","cyclicAndSpontanX","cyclicAndSpontanWithDelay","spontanWithRepitition","cyclicIfActiveAndSpontanWD","cyclicIfActiveFast","cyclicWithRepeatOnDemand","none";
BA_DEF_ BO_  "DiagResponse" ENUM  "nein","ja";
BA_DEF_ BO_  "DiagRequest" ENUM  "nein","ja";
BA_DEF_ BO_  "DiagState" ENUM  "nein","ja";
BA_DEF_ BO_  "App-Botschaft" ENUM  "nein","ja";
BA_DEF_ BO_  "NWM-Botschaft" ENUM  "nein","ja";
BA_DEF_DEF_  "GenSigTimeout_ADCM" 0;
BA_DEF_DEF_  "GenSigTimeout_AFLS" 0;
BA_DEF_DEF_  "GenSigTimeout_CBC" 0;
BA_DEF_DEF_  "GenSigTimeout_DTCM" 0;
BA_DEF_DEF_  "GenSigTimeout_ECM" 0;
BA_DEF_DEF_  "GenSigTimeout_EPS" 0;
BA_DEF_DEF_  "GenSigTimeout_ESC" 0;
BA_DEF_DEF_  "GenSigTimeout_ESM" 0;
BA_DEF_DEF_  "GenSigTimeout_ETM" 0;
BA_DEF_DEF_  "GenSigTimeout_HaLF" 0;
BA_DEF_DEF_  "GenSigTimeout_IC" 0;
BA_DEF_DEF_  "GenSigTimeout_ORC" 0;
BA_DEF_DEF_  "GenSigTimeout_PTS" 0;
BA_DEF_DEF_  "GenSigTimeout_RF_HUB" 0;
BA_DEF_DEF_  "GenSigTimeout_SCCM" 0;
BA_DEF_DEF_  "GenSigTimeout_TPM" 0;
BA_DEF_DEF_  "GenMsgStartValue" "";
BA_DEF_DEF_  "GenSigSNA" "";
BA_DEF_DEF_  "FlexKomIsMotorola" "nein";
BA_DEF_DEF_  "FlexKomSigLaenge" 0;
BA_DEF_DEF_  "FlexKomSigStartPos" 0;
BA_DEF_DEF_  "FlexKomComment" "";
BA_DEF_DEF_  "FlexKomSigName" "";
BA_DEF_DEF_  "FlexKomSID" 0;
BA_DEF_DEF_  "GenSigStartValue" 0;
BA_DEF_DEF_  "FlexKomSigStartValue" "";
BA_DEF_DEF_  "GenSigCycleTimeActive" 0;
BA_DEF_DEF_  "GenSigCycleTime" 0;
BA_DEF_DEF_  "GenSigSendType" "cyclicX";
BA_DEF_DEF_  "GenMsgNrOfRepetitions" 0;
BA_DEF_DEF_  "GenMsgDelayTime" 0;
BA_DEF_DEF_  "GenMsgStartDelayTime" 0;
BA_DEF_DEF_  "GenMsgCycleTimeActive" 0;
BA_DEF_DEF_  "GenMsgCycleTime" 0;
BA_DEF_DEF_  "GenMsgSendType" "cyclicX";
BA_DEF_DEF_  "DiagResponse" "nein";
BA_DEF_DEF_  "DiagRequest" "nein";
BA_DEF_DEF_  "DiagState" "nein";
BA_DEF_DEF_  "App-Botschaft" "nein";
BA_DEF_DEF_  "NWM-Botschaft" "nein";
BA_ "GenMsgSendType" BO_ 820 5;
BA_ "GenMsgCycleTime" BO_ 820 1000;
BA_ "GenMsgDelayTime" BO_ 820 20;
BA_ "GenMsgNrOfRepetitions" BO_ 820 2;
BA_ "GenMsgStartValue" BO_ 820 "6000003FFFFC0000h";
BA_ "GenMsgStartDelayTime" BO_ 820 20;
BA_ "GenMsgSendType" BO_ 825 5;
BA_ "GenMsgCycleTime" BO_ 825 500;
BA_ "GenMsgDelayTime" BO_ 825 20;
BA_ "GenMsgNrOfRepetitions" BO_ 825 2;
BA_ "GenMsgStartValue" BO_ 825 "0050h";
BA_ "GenMsgSendType" BO_ 826 5;
BA_ "GenMsgCycleTime" BO_ 826 500;
BA_ "GenMsgDelayTime" BO_ 826 20;
BA_ "GenMsgNrOfRepetitions" BO_ 826 2;
BA_ "GenMsgStartValue" BO_ 826 "00F0F0F0F0F0F000h";
BA_ "GenMsgSendType" BO_ 828 5;
BA_ "GenMsgCycleTime" BO_ 828 1000;
BA_ "GenMsgDelayTime" BO_ 828 20;
BA_ "GenMsgNrOfRepetitions" BO_ 828 2;
BA_ "GenMsgStartValue" BO_ 828 "0000000000000000h";
BA_ "GenMsgCycleTime" BO_ 831 200;
BA_ "GenMsgDelayTime" BO_ 831 20;
BA_ "GenMsgNrOfRepetitions" BO_ 831 2;
BA_ "GenMsgStartValue" BO_ 831 "FEFEFEFE0000h";
BA_ "GenMsgCycleTime" BO_ 832 500;
BA_ "GenMsgDelayTime" BO_ 832 20;
BA_ "GenMsgNrOfRepetitions" BO_ 832 2;
BA_ "GenMsgStartValue" BO_ 832 "FFFF00000000FFFFh";
BA_ "GenMsgSendType" BO_ 836 5;
BA_ "GenMsgCycleTime" BO_ 836 1000;
BA_ "GenMsgDelayTime" BO_ 836 20;
BA_ "GenMsgNrOfRepetitions" BO_ 836 2;
BA_ "GenMsgStartValue" BO_ 836 "0000h";
BA_ "GenMsgSendType" BO_ 838 5;
BA_ "GenMsgCycleTime" BO_ 838 1000;
BA_ "GenMsgDelayTime" BO_ 838 20;
BA_ "GenMsgNrOfRepetitions" BO_ 838 2;
BA_ "GenMsgStartValue" BO_ 838 "0000h";
BA_ "GenMsgSendType" BO_ 840 1;
BA_ "GenMsgDelayTime" BO_ 840 20;
BA_ "GenMsgNrOfRepetitions" BO_ 840 2;
BA_ "GenMsgStartValue" BO_ 840 "0000000000000000h";
BA_ "GenMsgSendType" BO_ 844 5;
BA_ "GenMsgCycleTime" BO_ 844 1000;
BA_ "GenMsgDelayTime" BO_ 844 20;
BA_ "GenMsgNrOfRepetitions" BO_ 844 2;
BA_ "GenMsgStartValue" BO_ 844 "008F3F0000h";
BA_ "GenMsgSendType" BO_ 847 1;
BA_ "GenMsgDelayTime" BO_ 847 20;
BA_ "GenMsgNrOfRepetitions" BO_ 847 2;
BA_ "GenMsgStartValue" BO_ 847 "00h";
BA_ "GenMsgCycleTime" BO_ 848 1000;
BA_ "GenMsgDelayTime" BO_ 848 20;
BA_ "GenMsgNrOfRepetitions" BO_ 848 2;
BA_ "GenMsgStartValue" BO_ 848 "FFFFFFFFFFFFFF07h";
BA_ "GenMsgSendType" BO_ 850 1;
BA_ "GenMsgDelayTime" BO_ 850 20;
BA_ "GenMsgNrOfRepetitions" BO_ 850 2;
BA_ "GenMsgStartValue" BO_ 850 "0000000000000000h";
BA_ "GenMsgSendType" BO_ 853 5;
BA_ "GenMsgCycleTime" BO_ 853 1000;
BA_ "GenMsgDelayTime" BO_ 853 20;
BA_ "GenMsgNrOfRepetitions" BO_ 853 2;
BA_ "GenMsgStartValue" BO_ 853 "F0FF0000000000FFh";
BA_ "GenMsgStartDelayTime" BO_ 853 100;
BA_ "GenMsgCycleTime" BO_ 856 1000;
BA_ "GenMsgDelayTime" BO_ 856 20;
BA_ "GenMsgNrOfRepetitions" BO_ 856 2;
BA_ "GenMsgStartValue" BO_ 856 "FF000000h";
BA_ "GenMsgStartDelayTime" BO_ 856 50;
BA_ "GenMsgSendType" BO_ 860 5;
BA_ "GenMsgCycleTime" BO_ 860 1000;
BA_ "GenMsgDelayTime" BO_ 860 20;
BA_ "GenMsgNrOfRepetitions" BO_ 860 2;
BA_ "GenMsgStartValue" BO_ 860 "000000000FFFh";
BA_ "GenMsgCycleTime" BO_ 863 100;
BA_ "GenMsgDelayTime" BO_ 863 20;
BA_ "GenMsgNrOfRepetitions" BO_ 863 2;
BA_ "GenMsgStartValue" BO_ 863 "000000000000FFFFh";
BA_ "GenMsgSendType" BO_ 864 1;
BA_ "GenMsgDelayTime" BO_ 864 20;
BA_ "GenMsgNrOfRepetitions" BO_ 864 2;
BA_ "GenMsgStartValue" BO_ 864 "0000000000000000h";
BA_ "GenMsgSendType" BO_ 865 1;
BA_ "GenMsgDelayTime" BO_ 865 20;
BA_ "GenMsgNrOfRepetitions" BO_ 865 2;
BA_ "GenMsgStartValue" BO_ 865 "0000000000000000h";
BA_ "GenMsgSendType" BO_ 866 1;
BA_ "GenMsgDelayTime" BO_ 866 20;
BA_ "GenMsgNrOfRepetitions" BO_ 866 2;
BA_ "GenMsgStartValue" BO_ 866 "0000000000000000h";
BA_ "GenMsgSendType" BO_ 867 1;
BA_ "GenMsgDelayTime" BO_ 867 20;
BA_ "GenMsgNrOfRepetitions" BO_ 867 2;
BA_ "GenMsgStartValue" BO_ 867 "0000000000000000h";
BA_ "GenMsgSendType" BO_ 868 1;
BA_ "GenMsgDelayTime" BO_ 868 20;
BA_ "GenMsgNrOfRepetitions" BO_ 868 2;
BA_ "GenMsgStartValue" BO_ 868 "0000000000000000h";
BA_ "GenMsgSendType" BO_ 872 1;
BA_ "GenMsgDelayTime" BO_ 872 20;
BA_ "GenMsgNrOfRepetitions" BO_ 872 2;
BA_ "GenMsgStartValue" BO_ 872 "0000000000000000h";
BA_ "GenMsgSendType" BO_ 874 5;
BA_ "GenMsgCycleTime" BO_ 874 1000;
BA_ "GenMsgDelayTime" BO_ 874 20;
BA_ "GenMsgNrOfRepetitions" BO_ 874 2;
BA_ "GenMsgStartValue" BO_ 874 "0000h";
BA_ "GenMsgSendType" BO_ 880 1;
BA_ "GenMsgDelayTime" BO_ 880 20;
BA_ "GenMsgNrOfRepetitions" BO_ 880 2;
BA_ "GenMsgStartValue" BO_ 880 "0000000000000000h";
BA_ "GenMsgSendType" BO_ 882 5;
BA_ "GenMsgCycleTime" BO_ 882 1000;
BA_ "GenMsgDelayTime" BO_ 882 20;
BA_ "GenMsgNrOfRepetitions" BO_ 882 2;
BA_ "GenMsgStartValue" BO_ 882 "00F8000001FE01FEh";
BA_ "GenMsgSendType" BO_ 888 1;
BA_ "GenMsgDelayTime" BO_ 888 20;
BA_ "GenMsgNrOfRepetitions" BO_ 888 2;
BA_ "GenMsgStartValue" BO_ 888 "0000000000000000h";
BA_ "GenMsgSendType" BO_ 896 1;
BA_ "GenMsgDelayTime" BO_ 896 20;
BA_ "GenMsgNrOfRepetitions" BO_ 896 2;
BA_ "GenMsgStartValue" BO_ 896 "0000000000000000h";
BA_ "GenMsgSendType" BO_ 897 5;
BA_ "GenMsgCycleTime" BO_ 897 2000;
BA_ "GenMsgDelayTime" BO_ 897 20;
BA_ "GenMsgNrOfRepetitions" BO_ 897 2;
BA_ "GenMsgStartValue" BO_ 897 "033F000000000000h";
BA_ "GenMsgSendType" BO_ 898 1;
BA_ "GenMsgDelayTime" BO_ 898 20;
BA_ "GenMsgNrOfRepetitions" BO_ 898 2;
BA_ "GenMsgStartValue" BO_ 898 "033F000000000000h";
BA_ "GenSigSendType" SG_ 820 OR_SW_PSD 5;
BA_ "GenSigCycleTime" SG_ 820 OR_SW_PSD 1000;
BA_ "FlexKomSigStartValue" SG_ 820 OR_SW_PSD "00h";
BA_ "FlexKomSID" SG_ 820 OR_SW_PSD 757;
BA_ "FlexKomSigStartPos" SG_ 820 OR_SW_PSD 1;
BA_ "FlexKomSigLaenge" SG_ 820 OR_SW_PSD 2;
BA_ "FlexKomSigName" SG_ 820 OR_SW_PSD "OR_SW_PSD";
BA_ "FlexKomComment" SG_ 820 OR_SW_PSD "Off Road switch pressed";
BA_ "FlexKomIsMotorola" SG_ 820 OR_SW_PSD 1;
BA_ "GenSigSNA" SG_ 820 OR_SW_PSD "3h";
BA_ "GenSigSendType" SG_ 820 FT_FOG_RQ 5;
BA_ "GenSigCycleTime" SG_ 820 FT_FOG_RQ 1000;
BA_ "FlexKomSigStartValue" SG_ 820 FT_FOG_RQ "00h";
BA_ "GenSigTimeout_IC" SG_ 820 FT_FOG_RQ 10500;
BA_ "FlexKomSID" SG_ 820 FT_FOG_RQ 758;
BA_ "FlexKomSigStartPos" SG_ 820 FT_FOG_RQ 2;
BA_ "FlexKomSigLaenge" SG_ 820 FT_FOG_RQ 1;
BA_ "FlexKomSigName" SG_ 820 FT_FOG_RQ "FT_FOG_RQ";
BA_ "FlexKomComment" SG_ 820 FT_FOG_RQ "Front fog request; off=[0], on=[1]";
BA_ "FlexKomIsMotorola" SG_ 820 FT_FOG_RQ 1;
BA_ "GenSigSNA" SG_ 820 FT_FOG_RQ "0h";
BA_ "GenSigSendType" SG_ 820 R_FOG_RQ 5;
BA_ "GenSigCycleTime" SG_ 820 R_FOG_RQ 1000;
BA_ "FlexKomSigStartValue" SG_ 820 R_FOG_RQ "00h";
BA_ "GenSigTimeout_IC" SG_ 820 R_FOG_RQ 10500;
BA_ "FlexKomSID" SG_ 820 R_FOG_RQ 427;
BA_ "FlexKomSigStartPos" SG_ 820 R_FOG_RQ 3;
BA_ "FlexKomSigLaenge" SG_ 820 R_FOG_RQ 1;
BA_ "FlexKomSigName" SG_ 820 R_FOG_RQ "R_FOG_RQ";
BA_ "FlexKomComment" SG_ 820 R_FOG_RQ "Rear fog request; [0] = off, [1] = on";
BA_ "FlexKomIsMotorola" SG_ 820 R_FOG_RQ 1;
BA_ "GenSigSNA" SG_ 820 R_FOG_RQ "0h";
BA_ "GenSigSendType" SG_ 820 REV_GEAR 5;
BA_ "GenSigCycleTime" SG_ 820 REV_GEAR 1000;
BA_ "FlexKomSigStartValue" SG_ 820 REV_GEAR "00h";
BA_ "GenSigTimeout_RF_HUB" SG_ 820 REV_GEAR 10500;
BA_ "GenSigTimeout_IC" SG_ 820 REV_GEAR 10500;
BA_ "GenSigTimeout_PTS" SG_ 820 REV_GEAR 3500;
BA_ "GenSigTimeout_TPM" SG_ 820 REV_GEAR 10500;
BA_ "GenSigTimeout_ORC" SG_ 820 REV_GEAR 3500;
BA_ "FlexKomSID" SG_ 820 REV_GEAR 685;
BA_ "FlexKomSigStartPos" SG_ 820 REV_GEAR 4;
BA_ "FlexKomSigLaenge" SG_ 820 REV_GEAR 1;
BA_ "FlexKomSigName" SG_ 820 REV_GEAR "REV_GEAR";
BA_ "FlexKomComment" SG_ 820 REV_GEAR "Reverse Gear (manual trans)";
BA_ "FlexKomIsMotorola" SG_ 820 REV_GEAR 1;
BA_ "GenSigSNA" SG_ 820 REV_GEAR "0h";
BA_ "GenSigSendType" SG_ 820 DR_LK_STAT 5;
BA_ "GenSigCycleTime" SG_ 820 DR_LK_STAT 1000;
BA_ "FlexKomSigStartValue" SG_ 820 DR_LK_STAT "03h";
BA_ "GenSigStartValue" SG_ 820 DR_LK_STAT 3;
BA_ "GenSigTimeout_RF_HUB" SG_ 820 DR_LK_STAT 10500;
BA_ "FlexKomSID" SG_ 820 DR_LK_STAT 861;
BA_ "FlexKomSigStartPos" SG_ 820 DR_LK_STAT 6;
BA_ "FlexKomSigLaenge" SG_ 820 DR_LK_STAT 2;
BA_ "FlexKomSigName" SG_ 820 DR_LK_STAT "DR_LK_STAT";
BA_ "FlexKomComment" SG_ 820 DR_LK_STAT "Door lock status";
BA_ "FlexKomIsMotorola" SG_ 820 DR_LK_STAT 1;
BA_ "GenSigSNA" SG_ 820 DR_LK_STAT "3h";
BA_ "GenSigSendType" SG_ 820 IHC_ACT 5;
BA_ "GenSigCycleTime" SG_ 820 IHC_ACT 1000;
BA_ "FlexKomSigStartValue" SG_ 820 IHC_ACT "00h";
BA_ "GenSigTimeout_IC" SG_ 820 IHC_ACT 10500;
BA_ "FlexKomSID" SG_ 820 IHC_ACT 760;
BA_ "FlexKomSigStartPos" SG_ 820 IHC_ACT 7;
BA_ "FlexKomSigLaenge" SG_ 820 IHC_ACT 1;
BA_ "FlexKomSigName" SG_ 820 IHC_ACT "IHC_ACT";
BA_ "FlexKomComment" SG_ 820 IHC_ACT "Intelligent headlight control active";
BA_ "FlexKomIsMotorola" SG_ 820 IHC_ACT 1;
BA_ "GenSigSNA" SG_ 820 IHC_ACT "0h";
BA_ "GenSigSendType" SG_ 820 FOB_SrchRq 5;
BA_ "GenSigCycleTime" SG_ 820 FOB_SrchRq 1000;
BA_ "FlexKomSigStartValue" SG_ 820 FOB_SrchRq "00h";
BA_ "GenSigTimeout_RF_HUB" SG_ 820 FOB_SrchRq 5500;
BA_ "FlexKomSID" SG_ 820 FOB_SrchRq 1392;
BA_ "FlexKomSigStartPos" SG_ 820 FOB_SrchRq 9;
BA_ "FlexKomSigLaenge" SG_ 820 FOB_SrchRq 2;
BA_ "FlexKomSigName" SG_ 820 FOB_SrchRq "FOB_SrchRq";
BA_ "FlexKomComment" SG_ 820 FOB_SrchRq "FOB search request";
BA_ "FlexKomIsMotorola" SG_ 820 FOB_SrchRq 1;
BA_ "GenSigSNA" SG_ 820 FOB_SrchRq "0h";
BA_ "GenSigSendType" SG_ 820 HbrntnAct 5;
BA_ "GenSigCycleTime" SG_ 820 HbrntnAct 1000;
BA_ "FlexKomSigStartValue" SG_ 820 HbrntnAct "00h";
BA_ "GenSigTimeout_IC" SG_ 820 HbrntnAct 10500;
BA_ "FlexKomSID" SG_ 820 HbrntnAct 1805;
BA_ "FlexKomSigStartPos" SG_ 820 HbrntnAct 10;
BA_ "FlexKomSigLaenge" SG_ 820 HbrntnAct 1;
BA_ "FlexKomSigName" SG_ 820 HbrntnAct "HbrntnAct";
BA_ "FlexKomComment" SG_ 820 HbrntnAct "Hibernation active (1=hibernation)";
BA_ "FlexKomIsMotorola" SG_ 820 HbrntnAct 1;
BA_ "GenSigSNA" SG_ 820 HbrntnAct "0h";
BA_ "GenSigSendType" SG_ 820 ElecDrLkFT_LT 5;
BA_ "GenSigCycleTime" SG_ 820 ElecDrLkFT_LT 1000;
BA_ "FlexKomSigStartValue" SG_ 820 ElecDrLkFT_LT "00h";
BA_ "GenSigTimeout_RF_HUB" SG_ 820 ElecDrLkFT_LT 10500;
BA_ "GenSigTimeout_ETM" SG_ 820 ElecDrLkFT_LT 10500;
BA_ "FlexKomSID" SG_ 820 ElecDrLkFT_LT 1808;
BA_ "FlexKomSigStartPos" SG_ 820 ElecDrLkFT_LT 12;
BA_ "FlexKomSigLaenge" SG_ 820 ElecDrLkFT_LT 2;
BA_ "FlexKomSigName" SG_ 820 ElecDrLkFT_LT "ElecDrLkPkt";
BA_ "FlexKomComment" SG_ 820 ElecDrLkFT_LT "Electronically controlled door lock packet";
BA_ "FlexKomIsMotorola" SG_ 820 ElecDrLkFT_LT 1;
BA_ "GenSigSNA" SG_ 820 ElecDrLkFT_LT "0h";
BA_ "GenSigSendType" SG_ 820 ElecDrLkFT_RT 5;
BA_ "GenSigCycleTime" SG_ 820 ElecDrLkFT_RT 1000;
BA_ "FlexKomSigStartValue" SG_ 820 ElecDrLkFT_RT "00h";
BA_ "GenSigTimeout_RF_HUB" SG_ 820 ElecDrLkFT_RT 10500;
BA_ "GenSigTimeout_ETM" SG_ 820 ElecDrLkFT_RT 10500;
BA_ "FlexKomSID" SG_ 820 ElecDrLkFT_RT 1808;
BA_ "FlexKomSigStartPos" SG_ 820 ElecDrLkFT_RT 12;
BA_ "FlexKomSigLaenge" SG_ 820 ElecDrLkFT_RT 2;
BA_ "FlexKomSigName" SG_ 820 ElecDrLkFT_RT "ElecDrLkPkt";
BA_ "FlexKomComment" SG_ 820 ElecDrLkFT_RT "Electronically controlled door lock packet";
BA_ "FlexKomIsMotorola" SG_ 820 ElecDrLkFT_RT 1;
BA_ "GenSigSNA" SG_ 820 ElecDrLkFT_RT "0h";
BA_ "GenSigSendType" SG_ 820 AHB_SAE_Md 5;
BA_ "GenSigCycleTime" SG_ 820 AHB_SAE_Md 1000;
BA_ "FlexKomSigStartValue" SG_ 820 AHB_SAE_Md "00h";
BA_ "GenSigTimeout_IC" SG_ 820 AHB_SAE_Md 10500;
BA_ "FlexKomSID" SG_ 820 AHB_SAE_Md 1423;
BA_ "FlexKomSigStartPos" SG_ 820 AHB_SAE_Md 13;
BA_ "FlexKomSigLaenge" SG_ 820 AHB_SAE_Md 1;
BA_ "FlexKomSigName" SG_ 820 AHB_SAE_Md "AHB_SAE_Md";
BA_ "FlexKomComment" SG_ 820 AHB_SAE_Md "Automatic high beam is in regulatory SAE mode";
BA_ "FlexKomIsMotorola" SG_ 820 AHB_SAE_Md 1;
BA_ "GenSigSNA" SG_ 820 AHB_SAE_Md "0h";
BA_ "GenSigSendType" SG_ 820 AHB_ACT 5;
BA_ "GenSigCycleTime" SG_ 820 AHB_ACT 1000;
BA_ "FlexKomSigStartValue" SG_ 820 AHB_ACT "00h";
BA_ "GenSigTimeout_IC" SG_ 820 AHB_ACT 10500;
BA_ "FlexKomSID" SG_ 820 AHB_ACT 732;
BA_ "FlexKomSigStartPos" SG_ 820 AHB_ACT 14;
BA_ "FlexKomSigLaenge" SG_ 820 AHB_ACT 1;
BA_ "FlexKomSigName" SG_ 820 AHB_ACT "AHB_ACT";
BA_ "FlexKomComment" SG_ 820 AHB_ACT "Automatic high beam active";
BA_ "FlexKomIsMotorola" SG_ 820 AHB_ACT 1;
BA_ "GenSigSNA" SG_ 820 AHB_ACT "0h";
BA_ "GenSigSendType" SG_ 820 WSH_OUT_FLT 5;
BA_ "GenSigCycleTime" SG_ 820 WSH_OUT_FLT 1000;
BA_ "FlexKomSigStartValue" SG_ 820 WSH_OUT_FLT "00h";
BA_ "FlexKomSID" SG_ 820 WSH_OUT_FLT 1295;
BA_ "FlexKomSigStartPos" SG_ 820 WSH_OUT_FLT 15;
BA_ "FlexKomSigLaenge" SG_ 820 WSH_OUT_FLT 1;
BA_ "FlexKomSigName" SG_ 820 WSH_OUT_FLT "WSH_OUT_FLT";
BA_ "FlexKomComment" SG_ 820 WSH_OUT_FLT "Washer Output Fault (1=faulted)";
BA_ "FlexKomIsMotorola" SG_ 820 WSH_OUT_FLT 1;
BA_ "GenSigSNA" SG_ 820 WSH_OUT_FLT "1h";
BA_ "GenSigSendType" SG_ 820 PARK_LMP_ON 5;
BA_ "GenSigCycleTime" SG_ 820 PARK_LMP_ON 1000;
BA_ "FlexKomSigStartValue" SG_ 820 PARK_LMP_ON "00h";
BA_ "GenSigTimeout_IC" SG_ 820 PARK_LMP_ON 10500;
BA_ "FlexKomSID" SG_ 820 PARK_LMP_ON 767;
BA_ "FlexKomSigStartPos" SG_ 820 PARK_LMP_ON 16;
BA_ "FlexKomSigLaenge" SG_ 820 PARK_LMP_ON 1;
BA_ "FlexKomSigName" SG_ 820 PARK_LMP_ON "PARK_LMP_ON";
BA_ "FlexKomComment" SG_ 820 PARK_LMP_ON "Parklamps are on; off=[0], on=[1]";
BA_ "FlexKomIsMotorola" SG_ 820 PARK_LMP_ON 1;
BA_ "GenSigSNA" SG_ 820 PARK_LMP_ON "0h";
BA_ "GenSigSendType" SG_ 820 DRV_AJAR 5;
BA_ "GenSigCycleTime" SG_ 820 DRV_AJAR 1000;
BA_ "FlexKomSigStartValue" SG_ 820 DRV_AJAR "00h";
BA_ "GenSigTimeout_RF_HUB" SG_ 820 DRV_AJAR 10500;
BA_ "GenSigTimeout_IC" SG_ 820 DRV_AJAR 10500;
BA_ "FlexKomSID" SG_ 820 DRV_AJAR 797;
BA_ "FlexKomSigStartPos" SG_ 820 DRV_AJAR 22;
BA_ "FlexKomSigLaenge" SG_ 820 DRV_AJAR 6;
BA_ "FlexKomSigName" SG_ 820 DRV_AJAR "DR_AJAR";
BA_ "FlexKomComment" SG_ 820 DRV_AJAR "Door ajar";
BA_ "FlexKomIsMotorola" SG_ 820 DRV_AJAR 1;
BA_ "GenSigSNA" SG_ 820 DRV_AJAR "0h";
BA_ "GenSigSendType" SG_ 820 PSG_AJAR 5;
BA_ "GenSigCycleTime" SG_ 820 PSG_AJAR 1000;
BA_ "FlexKomSigStartValue" SG_ 820 PSG_AJAR "00h";
BA_ "GenSigTimeout_RF_HUB" SG_ 820 PSG_AJAR 10500;
BA_ "GenSigTimeout_IC" SG_ 820 PSG_AJAR 10500;
BA_ "GenSigTimeout_ORC" SG_ 820 PSG_AJAR 3500;
BA_ "FlexKomSID" SG_ 820 PSG_AJAR 797;
BA_ "FlexKomSigStartPos" SG_ 820 PSG_AJAR 22;
BA_ "FlexKomSigLaenge" SG_ 820 PSG_AJAR 6;
BA_ "FlexKomSigName" SG_ 820 PSG_AJAR "DR_AJAR";
BA_ "FlexKomComment" SG_ 820 PSG_AJAR "Door ajar";
BA_ "FlexKomIsMotorola" SG_ 820 PSG_AJAR 1;
BA_ "GenSigSNA" SG_ 820 PSG_AJAR "0h";
BA_ "GenSigSendType" SG_ 820 L_R_AJAR 5;
BA_ "GenSigCycleTime" SG_ 820 L_R_AJAR 1000;
BA_ "FlexKomSigStartValue" SG_ 820 L_R_AJAR "00h";
BA_ "GenSigTimeout_RF_HUB" SG_ 820 L_R_AJAR 10500;
BA_ "GenSigTimeout_IC" SG_ 820 L_R_AJAR 10500;
BA_ "FlexKomSID" SG_ 820 L_R_AJAR 797;
BA_ "FlexKomSigStartPos" SG_ 820 L_R_AJAR 22;
BA_ "FlexKomSigLaenge" SG_ 820 L_R_AJAR 6;
BA_ "FlexKomSigName" SG_ 820 L_R_AJAR "DR_AJAR";
BA_ "FlexKomComment" SG_ 820 L_R_AJAR "Door ajar";
BA_ "FlexKomIsMotorola" SG_ 820 L_R_AJAR 1;
BA_ "GenSigSNA" SG_ 820 L_R_AJAR "0h";
BA_ "GenSigSendType" SG_ 820 R_R_AJAR 5;
BA_ "GenSigCycleTime" SG_ 820 R_R_AJAR 1000;
BA_ "FlexKomSigStartValue" SG_ 820 R_R_AJAR "00h";
BA_ "GenSigTimeout_RF_HUB" SG_ 820 R_R_AJAR 10500;
BA_ "GenSigTimeout_IC" SG_ 820 R_R_AJAR 10500;
BA_ "FlexKomSID" SG_ 820 R_R_AJAR 797;
BA_ "FlexKomSigStartPos" SG_ 820 R_R_AJAR 22;
BA_ "FlexKomSigLaenge" SG_ 820 R_R_AJAR 6;
BA_ "FlexKomSigName" SG_ 820 R_R_AJAR "DR_AJAR";
BA_ "FlexKomComment" SG_ 820 R_R_AJAR "Door ajar";
BA_ "FlexKomIsMotorola" SG_ 820 R_R_AJAR 1;
BA_ "GenSigSNA" SG_ 820 R_R_AJAR "0h";
BA_ "GenSigSendType" SG_ 820 FG_AJAR 5;
BA_ "GenSigCycleTime" SG_ 820 FG_AJAR 1000;
BA_ "FlexKomSigStartValue" SG_ 820 FG_AJAR "00h";
BA_ "GenSigTimeout_RF_HUB" SG_ 820 FG_AJAR 10500;
BA_ "GenSigTimeout_IC" SG_ 820 FG_AJAR 10500;
BA_ "FlexKomSID" SG_ 820 FG_AJAR 797;
BA_ "FlexKomSigStartPos" SG_ 820 FG_AJAR 22;
BA_ "FlexKomSigLaenge" SG_ 820 FG_AJAR 6;
BA_ "FlexKomSigName" SG_ 820 FG_AJAR "DR_AJAR";
BA_ "FlexKomComment" SG_ 820 FG_AJAR "Door ajar";
BA_ "FlexKomIsMotorola" SG_ 820 FG_AJAR 1;
BA_ "GenSigSNA" SG_ 820 FG_AJAR "0h";
BA_ "GenSigSendType" SG_ 820 TLG_AJAR 5;
BA_ "GenSigCycleTime" SG_ 820 TLG_AJAR 1000;
BA_ "FlexKomSigStartValue" SG_ 820 TLG_AJAR "00h";
BA_ "GenSigTimeout_RF_HUB" SG_ 820 TLG_AJAR 10500;
BA_ "GenSigTimeout_IC" SG_ 820 TLG_AJAR 10500;
BA_ "FlexKomSID" SG_ 820 TLG_AJAR 797;
BA_ "FlexKomSigStartPos" SG_ 820 TLG_AJAR 22;
BA_ "FlexKomSigLaenge" SG_ 820 TLG_AJAR 6;
BA_ "FlexKomSigName" SG_ 820 TLG_AJAR "DR_AJAR";
BA_ "FlexKomComment" SG_ 820 TLG_AJAR "Door ajar";
BA_ "FlexKomIsMotorola" SG_ 820 TLG_AJAR 1;
BA_ "GenSigSNA" SG_ 820 TLG_AJAR "0h";
BA_ "GenSigSendType" SG_ 820 PARK_BRK_EGD 5;
BA_ "GenSigCycleTime" SG_ 820 PARK_BRK_EGD 1000;
BA_ "FlexKomSigStartValue" SG_ 820 PARK_BRK_EGD "00h";
BA_ "GenSigTimeout_IC" SG_ 820 PARK_BRK_EGD 10500;
BA_ "FlexKomSID" SG_ 820 PARK_BRK_EGD 805;
BA_ "FlexKomSigStartPos" SG_ 820 PARK_BRK_EGD 23;
BA_ "FlexKomSigLaenge" SG_ 820 PARK_BRK_EGD 1;
BA_ "FlexKomSigName" SG_ 820 PARK_BRK_EGD "PARK_BRK_EGD";
BA_ "FlexKomComment" SG_ 820 PARK_BRK_EGD "Park brake switch engaged";
BA_ "FlexKomIsMotorola" SG_ 820 PARK_BRK_EGD 1;
BA_ "GenSigSNA" SG_ 820 PARK_BRK_EGD "0h";
BA_ "GenSigSendType" SG_ 820 IGN_OFF_TIME_LNG 5;
BA_ "GenSigCycleTime" SG_ 820 IGN_OFF_TIME_LNG 1000;
BA_ "FlexKomSigStartValue" SG_ 820 IGN_OFF_TIME_LNG "0FFFh";
BA_ "GenSigStartValue" SG_ 820 IGN_OFF_TIME_LNG 4095;
BA_ "GenSigTimeout_RF_HUB" SG_ 820 IGN_OFF_TIME_LNG 10500;
BA_ "GenSigTimeout_IC" SG_ 820 IGN_OFF_TIME_LNG 10500;
BA_ "FlexKomSID" SG_ 820 IGN_OFF_TIME_LNG 998;
BA_ "FlexKomSigStartPos" SG_ 820 IGN_OFF_TIME_LNG 31;
BA_ "FlexKomSigLaenge" SG_ 820 IGN_OFF_TIME_LNG 16;
BA_ "FlexKomSigName" SG_ 820 IGN_OFF_TIME_LNG "IGN_OFF_TIME_LNG";
BA_ "FlexKomComment" SG_ 820 IGN_OFF_TIME_LNG "Time since last ignition on (long)";
BA_ "FlexKomIsMotorola" SG_ 820 IGN_OFF_TIME_LNG 1;
BA_ "GenSigSNA" SG_ 820 IGN_OFF_TIME_LNG "FFFh";
BA_ "GenSigSendType" SG_ 820 SHIP_STAT 5;
BA_ "GenSigCycleTime" SG_ 820 SHIP_STAT 1000;
BA_ "FlexKomSigStartValue" SG_ 820 SHIP_STAT "03h";
BA_ "GenSigStartValue" SG_ 820 SHIP_STAT 3;
BA_ "GenSigTimeout_RF_HUB" SG_ 820 SHIP_STAT 10500;
BA_ "GenSigTimeout_IC" SG_ 820 SHIP_STAT 10500;
BA_ "GenSigTimeout_TPM" SG_ 820 SHIP_STAT 10500;
BA_ "GenSigTimeout_ORC" SG_ 820 SHIP_STAT 3500;
BA_ "FlexKomSID" SG_ 820 SHIP_STAT 869;
BA_ "FlexKomSigStartPos" SG_ 820 SHIP_STAT 29;
BA_ "FlexKomSigLaenge" SG_ 820 SHIP_STAT 2;
BA_ "FlexKomSigName" SG_ 820 SHIP_STAT "SHIP_STAT";
BA_ "FlexKomComment" SG_ 820 SHIP_STAT "Shipping status";
BA_ "FlexKomIsMotorola" SG_ 820 SHIP_STAT 1;
BA_ "GenSigSNA" SG_ 820 SHIP_STAT "3h";
BA_ "GenSigSendType" SG_ 820 TurnInd_LT_ON 5;
BA_ "GenSigCycleTime" SG_ 820 TurnInd_LT_ON 1000;
BA_ "FlexKomSigStartValue" SG_ 820 TurnInd_LT_ON "00h";
BA_ "GenSigTimeout_IC" SG_ 820 TurnInd_LT_ON 10500;
BA_ "GenSigTimeout_PTS" SG_ 820 TurnInd_LT_ON 10500;
BA_ "FlexKomSID" SG_ 820 TurnInd_LT_ON 759;
BA_ "FlexKomSigStartPos" SG_ 820 TurnInd_LT_ON 31;
BA_ "FlexKomSigLaenge" SG_ 820 TurnInd_LT_ON 2;
BA_ "FlexKomSigName" SG_ 820 TurnInd_LT_ON "TurnInd_STAT";
BA_ "FlexKomComment" SG_ 820 TurnInd_LT_ON "Turn indication status";
BA_ "FlexKomIsMotorola" SG_ 820 TurnInd_LT_ON 1;
BA_ "GenSigSNA" SG_ 820 TurnInd_LT_ON "0h";
BA_ "GenSigSendType" SG_ 820 TurnInd_RT_ON 5;
BA_ "GenSigCycleTime" SG_ 820 TurnInd_RT_ON 1000;
BA_ "FlexKomSigStartValue" SG_ 820 TurnInd_RT_ON "00h";
BA_ "GenSigTimeout_IC" SG_ 820 TurnInd_RT_ON 10500;
BA_ "GenSigTimeout_PTS" SG_ 820 TurnInd_RT_ON 10500;
BA_ "FlexKomSID" SG_ 820 TurnInd_RT_ON 759;
BA_ "FlexKomSigStartPos" SG_ 820 TurnInd_RT_ON 31;
BA_ "FlexKomSigLaenge" SG_ 820 TurnInd_RT_ON 2;
BA_ "FlexKomSigName" SG_ 820 TurnInd_RT_ON "TurnInd_STAT";
BA_ "FlexKomComment" SG_ 820 TurnInd_RT_ON "Turn indication status";
BA_ "FlexKomIsMotorola" SG_ 820 TurnInd_RT_ON 1;
BA_ "GenSigSNA" SG_ 820 TurnInd_RT_ON "0h";
BA_ "GenSigSendType" SG_ 820 DAY_LGT_MD 5;
BA_ "GenSigCycleTime" SG_ 820 DAY_LGT_MD 1000;
BA_ "FlexKomSigStartValue" SG_ 820 DAY_LGT_MD "000000h";
BA_ "GenSigTimeout_RF_HUB" SG_ 820 DAY_LGT_MD 10500;
BA_ "GenSigTimeout_IC" SG_ 820 DAY_LGT_MD 10500;
BA_ "GenSigTimeout_SCCM" SG_ 820 DAY_LGT_MD 10500;
BA_ "GenSigTimeout_ESM" SG_ 820 DAY_LGT_MD 10500;
BA_ "FlexKomSID" SG_ 820 DAY_LGT_MD 1417;
BA_ "FlexKomSigStartPos" SG_ 820 DAY_LGT_MD 47;
BA_ "FlexKomSigLaenge" SG_ 820 DAY_LGT_MD 24;
BA_ "FlexKomSigName" SG_ 820 DAY_LGT_MD "IntLtSt_PT";
BA_ "FlexKomComment" SG_ 820 DAY_LGT_MD "Interior lighting status powertrain";
BA_ "FlexKomIsMotorola" SG_ 820 DAY_LGT_MD 1;
BA_ "GenSigSNA" SG_ 820 DAY_LGT_MD "0h";
BA_ "GenSigSendType" SG_ 820 DISP_SYNC 5;
BA_ "GenSigCycleTime" SG_ 820 DISP_SYNC 1000;
BA_ "FlexKomSigStartValue" SG_ 820 DISP_SYNC "000000h";
BA_ "FlexKomSID" SG_ 820 DISP_SYNC 1417;
BA_ "FlexKomSigStartPos" SG_ 820 DISP_SYNC 47;
BA_ "FlexKomSigLaenge" SG_ 820 DISP_SYNC 24;
BA_ "FlexKomSigName" SG_ 820 DISP_SYNC "IntLtSt_PT";
BA_ "FlexKomComment" SG_ 820 DISP_SYNC "Interior lighting status powertrain";
BA_ "FlexKomIsMotorola" SG_ 820 DISP_SYNC 1;
BA_ "GenSigSNA" SG_ 820 DISP_SYNC "0h";
BA_ "GenSigSendType" SG_ 820 PTC_REL1_STAT 5;
BA_ "GenSigCycleTime" SG_ 820 PTC_REL1_STAT 1000;
BA_ "FlexKomSigStartValue" SG_ 820 PTC_REL1_STAT "3Fh";
BA_ "GenSigStartValue" SG_ 820 PTC_REL1_STAT 3;
BA_ "FlexKomSID" SG_ 820 PTC_REL1_STAT 859;
BA_ "FlexKomSigStartPos" SG_ 820 PTC_REL1_STAT 47;
BA_ "FlexKomSigLaenge" SG_ 820 PTC_REL1_STAT 6;
BA_ "FlexKomSigName" SG_ 820 PTC_REL1_STAT "PTC_REL_STAT";
BA_ "FlexKomComment" SG_ 820 PTC_REL1_STAT "PTC relays status";
BA_ "FlexKomIsMotorola" SG_ 820 PTC_REL1_STAT 1;
BA_ "GenSigSNA" SG_ 820 PTC_REL1_STAT "3h";
BA_ "GenSigSendType" SG_ 820 PTC_REL2_STAT 5;
BA_ "GenSigCycleTime" SG_ 820 PTC_REL2_STAT 1000;
BA_ "FlexKomSigStartValue" SG_ 820 PTC_REL2_STAT "3Fh";
BA_ "GenSigStartValue" SG_ 820 PTC_REL2_STAT 3;
BA_ "FlexKomSID" SG_ 820 PTC_REL2_STAT 859;
BA_ "FlexKomSigStartPos" SG_ 820 PTC_REL2_STAT 47;
BA_ "FlexKomSigLaenge" SG_ 820 PTC_REL2_STAT 6;
BA_ "FlexKomSigName" SG_ 820 PTC_REL2_STAT "PTC_REL_STAT";
BA_ "FlexKomComment" SG_ 820 PTC_REL2_STAT "PTC relays status";
BA_ "FlexKomIsMotorola" SG_ 820 PTC_REL2_STAT 1;
BA_ "GenSigSNA" SG_ 820 PTC_REL2_STAT "3h";
BA_ "GenSigSendType" SG_ 820 PTC_REL3_STAT 5;
BA_ "GenSigCycleTime" SG_ 820 PTC_REL3_STAT 1000;
BA_ "FlexKomSigStartValue" SG_ 820 PTC_REL3_STAT "3Fh";
BA_ "GenSigStartValue" SG_ 820 PTC_REL3_STAT 3;
BA_ "FlexKomSID" SG_ 820 PTC_REL3_STAT 859;
BA_ "FlexKomSigStartPos" SG_ 820 PTC_REL3_STAT 47;
BA_ "FlexKomSigLaenge" SG_ 820 PTC_REL3_STAT 6;
BA_ "FlexKomSigName" SG_ 820 PTC_REL3_STAT "PTC_REL_STAT";
BA_ "FlexKomComment" SG_ 820 PTC_REL3_STAT "PTC relays status";
BA_ "FlexKomIsMotorola" SG_ 820 PTC_REL3_STAT 1;
BA_ "GenSigSNA" SG_ 820 PTC_REL3_STAT "3h";
BA_ "GenSigSendType" SG_ 820 PANEL_INTS 5;
BA_ "GenSigCycleTime" SG_ 820 PANEL_INTS 1000;
BA_ "FlexKomSigStartValue" SG_ 820 PANEL_INTS "000000h";
BA_ "GenSigTimeout_RF_HUB" SG_ 820 PANEL_INTS 10500;
BA_ "GenSigTimeout_IC" SG_ 820 PANEL_INTS 10500;
BA_ "GenSigTimeout_SCCM" SG_ 820 PANEL_INTS 10500;
BA_ "GenSigTimeout_ESM" SG_ 820 PANEL_INTS 10500;
BA_ "FlexKomSID" SG_ 820 PANEL_INTS 1417;
BA_ "FlexKomSigStartPos" SG_ 820 PANEL_INTS 47;
BA_ "FlexKomSigLaenge" SG_ 820 PANEL_INTS 24;
BA_ "FlexKomSigName" SG_ 820 PANEL_INTS "IntLtSt_PT";
BA_ "FlexKomComment" SG_ 820 PANEL_INTS "Interior lighting status powertrain";
BA_ "FlexKomIsMotorola" SG_ 820 PANEL_INTS 1;
BA_ "GenSigSNA" SG_ 820 PANEL_INTS "FFh";
BA_ "GenSigSendType" SG_ 820 FT_WPR_NOT_PRK 5;
BA_ "GenSigCycleTime" SG_ 820 FT_WPR_NOT_PRK 1000;
BA_ "FlexKomSigStartValue" SG_ 820 FT_WPR_NOT_PRK "00h";
BA_ "FlexKomSID" SG_ 820 FT_WPR_NOT_PRK 1046;
BA_ "FlexKomSigStartPos" SG_ 820 FT_WPR_NOT_PRK 56;
BA_ "FlexKomSigLaenge" SG_ 820 FT_WPR_NOT_PRK 1;
BA_ "FlexKomSigName" SG_ 820 FT_WPR_NOT_PRK "FT_WPR_NOT_PRK";
BA_ "FlexKomComment" SG_ 820 FT_WPR_NOT_PRK "Front wiper outside park position";
BA_ "FlexKomIsMotorola" SG_ 820 FT_WPR_NOT_PRK 1;
BA_ "GenSigSNA" SG_ 820 FT_WPR_NOT_PRK "0h";
BA_ "GenSigSendType" SG_ 820 LOBEAM_ON 5;
BA_ "GenSigCycleTime" SG_ 820 LOBEAM_ON 1000;
BA_ "FlexKomSigStartValue" SG_ 820 LOBEAM_ON "00h";
BA_ "GenSigTimeout_IC" SG_ 820 LOBEAM_ON 10500;
BA_ "GenSigTimeout_TPM" SG_ 820 LOBEAM_ON 10500;
BA_ "FlexKomSID" SG_ 820 LOBEAM_ON 883;
BA_ "FlexKomSigStartPos" SG_ 820 LOBEAM_ON 57;
BA_ "FlexKomSigLaenge" SG_ 820 LOBEAM_ON 1;
BA_ "FlexKomSigName" SG_ 820 LOBEAM_ON "LOBEAM_ON";
BA_ "FlexKomComment" SG_ 820 LOBEAM_ON "Low beam is on; off=[0], on=[1]";
BA_ "FlexKomIsMotorola" SG_ 820 LOBEAM_ON 1;
BA_ "GenSigSNA" SG_ 820 LOBEAM_ON "0h";
BA_ "GenSigSendType" SG_ 820 HIBEAM_ON 5;
BA_ "GenSigCycleTime" SG_ 820 HIBEAM_ON 1000;
BA_ "FlexKomSigStartValue" SG_ 820 HIBEAM_ON "00h";
BA_ "GenSigTimeout_IC" SG_ 820 HIBEAM_ON 10500;
BA_ "FlexKomSID" SG_ 820 HIBEAM_ON 884;
BA_ "FlexKomSigStartPos" SG_ 820 HIBEAM_ON 58;
BA_ "FlexKomSigLaenge" SG_ 820 HIBEAM_ON 1;
BA_ "FlexKomSigName" SG_ 820 HIBEAM_ON "HIBEAM_ON";
BA_ "FlexKomComment" SG_ 820 HIBEAM_ON "High beam is on; off=[0], on=[1]";
BA_ "FlexKomIsMotorola" SG_ 820 HIBEAM_ON 1;
BA_ "GenSigSNA" SG_ 820 HIBEAM_ON "0h";
BA_ "GenSigSendType" SG_ 820 PoliceStlthMdAct 5;
BA_ "GenSigCycleTime" SG_ 820 PoliceStlthMdAct 1000;
BA_ "FlexKomSigStartValue" SG_ 820 PoliceStlthMdAct "000000h";
BA_ "GenSigTimeout_RF_HUB" SG_ 820 PoliceStlthMdAct 10500;
BA_ "GenSigTimeout_IC" SG_ 820 PoliceStlthMdAct 10500;
BA_ "FlexKomSID" SG_ 820 PoliceStlthMdAct 1417;
BA_ "FlexKomSigStartPos" SG_ 820 PoliceStlthMdAct 47;
BA_ "FlexKomSigLaenge" SG_ 820 PoliceStlthMdAct 24;
BA_ "FlexKomSigName" SG_ 820 PoliceStlthMdAct "IntLtSt_PT";
BA_ "FlexKomComment" SG_ 820 PoliceStlthMdAct "Interior lighting status powertrain";
BA_ "FlexKomIsMotorola" SG_ 820 PoliceStlthMdAct 1;
BA_ "GenSigSNA" SG_ 820 PoliceStlthMdAct "0h";
BA_ "GenSigSendType" SG_ 820 TPM_SW_Psd 5;
BA_ "GenSigCycleTime" SG_ 820 TPM_SW_Psd 1000;
BA_ "FlexKomSigStartValue" SG_ 820 TPM_SW_Psd "00h";
BA_ "GenSigTimeout_RF_HUB" SG_ 820 TPM_SW_Psd 10500;
BA_ "GenSigTimeout_TPM" SG_ 820 TPM_SW_Psd 10500;
BA_ "FlexKomSID" SG_ 820 TPM_SW_Psd 1073;
BA_ "FlexKomSigStartPos" SG_ 820 TPM_SW_Psd 60;
BA_ "FlexKomSigLaenge" SG_ 820 TPM_SW_Psd 1;
BA_ "FlexKomSigName" SG_ 820 TPM_SW_Psd "TPM_SW_Psd";
BA_ "FlexKomComment" SG_ 820 TPM_SW_Psd "Tire Pressure Monitor Switch Status, Pressed = [1]";
BA_ "FlexKomIsMotorola" SG_ 820 TPM_SW_Psd 1;
BA_ "GenSigSNA" SG_ 820 TPM_SW_Psd "0h";
BA_ "GenSigSendType" SG_ 820 ThatchamCBC 5;
BA_ "GenSigCycleTime" SG_ 820 ThatchamCBC 1000;
BA_ "FlexKomSigStartValue" SG_ 820 ThatchamCBC "00h";
BA_ "FlexKomSID" SG_ 820 ThatchamCBC 1571;
BA_ "FlexKomSigStartPos" SG_ 820 ThatchamCBC 61;
BA_ "FlexKomSigLaenge" SG_ 820 ThatchamCBC 1;
BA_ "FlexKomSigName" SG_ 820 ThatchamCBC "ThatchamCBC";
BA_ "FlexKomComment" SG_ 820 ThatchamCBC "CBC has learned the presence of Thatcham; true = [";
BA_ "FlexKomIsMotorola" SG_ 820 ThatchamCBC 1;
BA_ "GenSigSNA" SG_ 820 ThatchamCBC "0h";
BA_ "GenSigSendType" SG_ 820 BRK_FLUID_LO 5;
BA_ "GenSigCycleTime" SG_ 820 BRK_FLUID_LO 1000;
BA_ "FlexKomSigStartValue" SG_ 820 BRK_FLUID_LO "00h";
BA_ "GenSigTimeout_IC" SG_ 820 BRK_FLUID_LO 10500;
BA_ "GenSigTimeout_ETM" SG_ 820 BRK_FLUID_LO 10500;
BA_ "FlexKomSID" SG_ 820 BRK_FLUID_LO 885;
BA_ "FlexKomSigStartPos" SG_ 820 BRK_FLUID_LO 62;
BA_ "FlexKomSigLaenge" SG_ 820 BRK_FLUID_LO 1;
BA_ "FlexKomSigName" SG_ 820 BRK_FLUID_LO "BRK_FLUID_LO";
BA_ "FlexKomComment" SG_ 820 BRK_FLUID_LO "Low brake fluid warning; low = [1]";
BA_ "FlexKomIsMotorola" SG_ 820 BRK_FLUID_LO 1;
BA_ "GenSigSNA" SG_ 820 BRK_FLUID_LO "0h";
BA_ "GenSigSendType" SG_ 820 WASH_FLUID_LO 5;
BA_ "GenSigCycleTime" SG_ 820 WASH_FLUID_LO 1000;
BA_ "FlexKomSigStartValue" SG_ 820 WASH_FLUID_LO "00h";
BA_ "GenSigTimeout_IC" SG_ 820 WASH_FLUID_LO 10500;
BA_ "GenSigTimeout_ETM" SG_ 820 WASH_FLUID_LO 10500;
BA_ "FlexKomSID" SG_ 820 WASH_FLUID_LO 965;
BA_ "FlexKomSigStartPos" SG_ 820 WASH_FLUID_LO 63;
BA_ "FlexKomSigLaenge" SG_ 820 WASH_FLUID_LO 1;
BA_ "FlexKomSigName" SG_ 820 WASH_FLUID_LO "WASH_FLUID_LO";
BA_ "FlexKomComment" SG_ 820 WASH_FLUID_LO "Low washer fluid warning (1=Fluid is low)";
BA_ "FlexKomIsMotorola" SG_ 820 WASH_FLUID_LO 1;
BA_ "GenSigSNA" SG_ 820 WASH_FLUID_LO "0h";
BA_ "GenSigSendType" SG_ 825 PTS_RF_CHIME_RQ 5;
BA_ "GenSigCycleTime" SG_ 825 PTS_RF_CHIME_RQ 500;
BA_ "FlexKomSigStartValue" SG_ 825 PTS_RF_CHIME_RQ "0050h";
BA_ "FlexKomSID" SG_ 825 PTS_RF_CHIME_RQ 1350;
BA_ "FlexKomSigStartPos" SG_ 825 PTS_RF_CHIME_RQ 7;
BA_ "FlexKomSigLaenge" SG_ 825 PTS_RF_CHIME_RQ 16;
BA_ "FlexKomSigName" SG_ 825 PTS_RF_CHIME_RQ "PTS_CHIME_STAT";
BA_ "FlexKomComment" SG_ 825 PTS_RF_CHIME_RQ "PTS chime status";
BA_ "FlexKomIsMotorola" SG_ 825 PTS_RF_CHIME_RQ 1;
BA_ "GenSigSNA" SG_ 825 PTS_RF_CHIME_RQ "0h";
BA_ "GenSigSendType" SG_ 825 PTS_LF_CHIME_RQ 5;
BA_ "GenSigCycleTime" SG_ 825 PTS_LF_CHIME_RQ 500;
BA_ "FlexKomSigStartValue" SG_ 825 PTS_LF_CHIME_RQ "0050h";
BA_ "FlexKomSID" SG_ 825 PTS_LF_CHIME_RQ 1350;
BA_ "FlexKomSigStartPos" SG_ 825 PTS_LF_CHIME_RQ 7;
BA_ "FlexKomSigLaenge" SG_ 825 PTS_LF_CHIME_RQ 16;
BA_ "FlexKomSigName" SG_ 825 PTS_LF_CHIME_RQ "PTS_CHIME_STAT";
BA_ "FlexKomComment" SG_ 825 PTS_LF_CHIME_RQ "PTS chime status";
BA_ "FlexKomIsMotorola" SG_ 825 PTS_LF_CHIME_RQ 1;
BA_ "GenSigSNA" SG_ 825 PTS_LF_CHIME_RQ "0h";
BA_ "GenSigSendType" SG_ 825 PTS_RR_CHIME_RQ 5;
BA_ "GenSigCycleTime" SG_ 825 PTS_RR_CHIME_RQ 500;
BA_ "FlexKomSigStartValue" SG_ 825 PTS_RR_CHIME_RQ "0050h";
BA_ "FlexKomSID" SG_ 825 PTS_RR_CHIME_RQ 1350;
BA_ "FlexKomSigStartPos" SG_ 825 PTS_RR_CHIME_RQ 7;
BA_ "FlexKomSigLaenge" SG_ 825 PTS_RR_CHIME_RQ 16;
BA_ "FlexKomSigName" SG_ 825 PTS_RR_CHIME_RQ "PTS_CHIME_STAT";
BA_ "FlexKomComment" SG_ 825 PTS_RR_CHIME_RQ "PTS chime status";
BA_ "FlexKomIsMotorola" SG_ 825 PTS_RR_CHIME_RQ 1;
BA_ "GenSigSNA" SG_ 825 PTS_RR_CHIME_RQ "0h";
BA_ "GenSigSendType" SG_ 825 PTS_LR_CHIME_RQ 5;
BA_ "GenSigCycleTime" SG_ 825 PTS_LR_CHIME_RQ 500;
BA_ "FlexKomSigStartValue" SG_ 825 PTS_LR_CHIME_RQ "0050h";
BA_ "FlexKomSID" SG_ 825 PTS_LR_CHIME_RQ 1350;
BA_ "FlexKomSigStartPos" SG_ 825 PTS_LR_CHIME_RQ 7;
BA_ "FlexKomSigLaenge" SG_ 825 PTS_LR_CHIME_RQ 16;
BA_ "FlexKomSigName" SG_ 825 PTS_LR_CHIME_RQ "PTS_CHIME_STAT";
BA_ "FlexKomComment" SG_ 825 PTS_LR_CHIME_RQ "PTS chime status";
BA_ "FlexKomIsMotorola" SG_ 825 PTS_LR_CHIME_RQ 1;
BA_ "GenSigSNA" SG_ 825 PTS_LR_CHIME_RQ "0h";
BA_ "GenSigSendType" SG_ 825 PTS_CHIME_TYPE 5;
BA_ "GenSigCycleTime" SG_ 825 PTS_CHIME_TYPE 500;
BA_ "FlexKomSigStartValue" SG_ 825 PTS_CHIME_TYPE "0050h";
BA_ "GenSigTimeout_CBC" SG_ 825 PTS_CHIME_TYPE 5250;
BA_ "FlexKomSID" SG_ 825 PTS_CHIME_TYPE 1350;
BA_ "FlexKomSigStartPos" SG_ 825 PTS_CHIME_TYPE 7;
BA_ "FlexKomSigLaenge" SG_ 825 PTS_CHIME_TYPE 16;
BA_ "FlexKomSigName" SG_ 825 PTS_CHIME_TYPE "PTS_CHIME_STAT";
BA_ "FlexKomComment" SG_ 825 PTS_CHIME_TYPE "PTS chime status";
BA_ "FlexKomIsMotorola" SG_ 825 PTS_CHIME_TYPE 1;
BA_ "GenSigSNA" SG_ 825 PTS_CHIME_TYPE "Fh";
BA_ "GenSigSendType" SG_ 825 PTS_CHIME_REP_RATE 5;
BA_ "GenSigCycleTime" SG_ 825 PTS_CHIME_REP_RATE 500;
BA_ "FlexKomSigStartValue" SG_ 825 PTS_CHIME_REP_RATE "0050h";
BA_ "FlexKomSID" SG_ 825 PTS_CHIME_REP_RATE 1350;
BA_ "FlexKomSigStartPos" SG_ 825 PTS_CHIME_REP_RATE 7;
BA_ "FlexKomSigLaenge" SG_ 825 PTS_CHIME_REP_RATE 16;
BA_ "FlexKomSigName" SG_ 825 PTS_CHIME_REP_RATE "PTS_CHIME_STAT";
BA_ "FlexKomComment" SG_ 825 PTS_CHIME_REP_RATE "PTS chime status";
BA_ "FlexKomIsMotorola" SG_ 825 PTS_CHIME_REP_RATE 1;
BA_ "GenSigSNA" SG_ 825 PTS_CHIME_REP_RATE "0h";
BA_ "GenSigSendType" SG_ 825 PTS_FT_VOL 5;
BA_ "GenSigCycleTime" SG_ 825 PTS_FT_VOL 500;
BA_ "FlexKomSigStartValue" SG_ 825 PTS_FT_VOL "0050h";
BA_ "GenSigStartValue" SG_ 825 PTS_FT_VOL 1;
BA_ "GenSigTimeout_CBC" SG_ 825 PTS_FT_VOL 5250;
BA_ "FlexKomSID" SG_ 825 PTS_FT_VOL 1350;
BA_ "FlexKomSigStartPos" SG_ 825 PTS_FT_VOL 7;
BA_ "FlexKomSigLaenge" SG_ 825 PTS_FT_VOL 16;
BA_ "FlexKomSigName" SG_ 825 PTS_FT_VOL "PTS_CHIME_STAT";
BA_ "FlexKomComment" SG_ 825 PTS_FT_VOL "PTS chime status";
BA_ "FlexKomIsMotorola" SG_ 825 PTS_FT_VOL 1;
BA_ "GenSigSNA" SG_ 825 PTS_FT_VOL "3h";
BA_ "GenSigSendType" SG_ 825 PTS_RR_VOL 5;
BA_ "GenSigCycleTime" SG_ 825 PTS_RR_VOL 500;
BA_ "FlexKomSigStartValue" SG_ 825 PTS_RR_VOL "0050h";
BA_ "GenSigStartValue" SG_ 825 PTS_RR_VOL 1;
BA_ "GenSigTimeout_CBC" SG_ 825 PTS_RR_VOL 5250;
BA_ "FlexKomSID" SG_ 825 PTS_RR_VOL 1350;
BA_ "FlexKomSigStartPos" SG_ 825 PTS_RR_VOL 7;
BA_ "FlexKomSigLaenge" SG_ 825 PTS_RR_VOL 16;
BA_ "FlexKomSigName" SG_ 825 PTS_RR_VOL "PTS_CHIME_STAT";
BA_ "FlexKomComment" SG_ 825 PTS_RR_VOL "PTS chime status";
BA_ "FlexKomIsMotorola" SG_ 825 PTS_RR_VOL 1;
BA_ "GenSigSNA" SG_ 825 PTS_RR_VOL "3h";
BA_ "GenSigSendType" SG_ 826 PTS_DispRq 5;
BA_ "GenSigCycleTime" SG_ 826 PTS_DispRq 500;
BA_ "FlexKomSigStartValue" SG_ 826 PTS_DispRq "00h";
BA_ "GenSigTimeout_IC" SG_ 826 PTS_DispRq 5250;
BA_ "FlexKomSID" SG_ 826 PTS_DispRq 1113;
BA_ "FlexKomSigLaenge" SG_ 826 PTS_DispRq 1;
BA_ "FlexKomSigName" SG_ 826 PTS_DispRq "PTS_DispRq";
BA_ "FlexKomComment" SG_ 826 PTS_DispRq "PTS display is on = [1], off = [0]";
BA_ "FlexKomIsMotorola" SG_ 826 PTS_DispRq 1;
BA_ "GenSigSNA" SG_ 826 PTS_DispRq "0h";
BA_ "GenSigSendType" SG_ 826 PTS_CFG_STAT 5;
BA_ "GenSigCycleTime" SG_ 826 PTS_CFG_STAT 500;
BA_ "FlexKomSigStartValue" SG_ 826 PTS_CFG_STAT "00h";
BA_ "GenSigTimeout_CBC" SG_ 826 PTS_CFG_STAT 5250;
BA_ "GenSigTimeout_IC" SG_ 826 PTS_CFG_STAT 5250;
BA_ "FlexKomSID" SG_ 826 PTS_CFG_STAT 1114;
BA_ "FlexKomSigStartPos" SG_ 826 PTS_CFG_STAT 2;
BA_ "FlexKomSigLaenge" SG_ 826 PTS_CFG_STAT 2;
BA_ "FlexKomSigName" SG_ 826 PTS_CFG_STAT "PTS_CFG_STAT";
BA_ "FlexKomComment" SG_ 826 PTS_CFG_STAT "Park assist configuration status";
BA_ "FlexKomIsMotorola" SG_ 826 PTS_CFG_STAT 1;
BA_ "GenSigSNA" SG_ 826 PTS_CFG_STAT "3h";
BA_ "GenSigSendType" SG_ 826 PTS_FT_NA 5;
BA_ "GenSigCycleTime" SG_ 826 PTS_FT_NA 500;
BA_ "FlexKomSigStartValue" SG_ 826 PTS_FT_NA "00h";
BA_ "GenSigTimeout_IC" SG_ 826 PTS_FT_NA 5250;
BA_ "FlexKomSID" SG_ 826 PTS_FT_NA 1314;
BA_ "FlexKomSigStartPos" SG_ 826 PTS_FT_NA 3;
BA_ "FlexKomSigLaenge" SG_ 826 PTS_FT_NA 1;
BA_ "FlexKomSigName" SG_ 826 PTS_FT_NA "PTS_FT_NA";
BA_ "FlexKomComment" SG_ 826 PTS_FT_NA "Front park assist not available - blinded sensor; ";
BA_ "FlexKomIsMotorola" SG_ 826 PTS_FT_NA 1;
BA_ "GenSigSNA" SG_ 826 PTS_FT_NA "0h";
BA_ "GenSigSendType" SG_ 826 PTS_RR_NA 5;
BA_ "GenSigCycleTime" SG_ 826 PTS_RR_NA 500;
BA_ "FlexKomSigStartValue" SG_ 826 PTS_RR_NA "00h";
BA_ "GenSigTimeout_IC" SG_ 826 PTS_RR_NA 5250;
BA_ "FlexKomSID" SG_ 826 PTS_RR_NA 1315;
BA_ "FlexKomSigStartPos" SG_ 826 PTS_RR_NA 4;
BA_ "FlexKomSigLaenge" SG_ 826 PTS_RR_NA 1;
BA_ "FlexKomSigName" SG_ 826 PTS_RR_NA "PTS_RR_NA";
BA_ "FlexKomComment" SG_ 826 PTS_RR_NA "Rear park assist not available - blinded sensor; T";
BA_ "FlexKomIsMotorola" SG_ 826 PTS_RR_NA 1;
BA_ "GenSigSNA" SG_ 826 PTS_RR_NA "0h";
BA_ "GenSigSendType" SG_ 826 PTS_SRV_RQ 5;
BA_ "GenSigCycleTime" SG_ 826 PTS_SRV_RQ 500;
BA_ "FlexKomSigStartValue" SG_ 826 PTS_SRV_RQ "00h";
BA_ "GenSigTimeout_IC" SG_ 826 PTS_SRV_RQ 5250;
BA_ "FlexKomSID" SG_ 826 PTS_SRV_RQ 54;
BA_ "FlexKomSigStartPos" SG_ 826 PTS_SRV_RQ 5;
BA_ "FlexKomSigLaenge" SG_ 826 PTS_SRV_RQ 1;
BA_ "FlexKomSigName" SG_ 826 PTS_SRV_RQ "PTS_SRV_RQ";
BA_ "FlexKomComment" SG_ 826 PTS_SRV_RQ "PTS service warning request; True = [1]";
BA_ "FlexKomIsMotorola" SG_ 826 PTS_SRV_RQ 1;
BA_ "GenSigSNA" SG_ 826 PTS_SRV_RQ "0h";
BA_ "GenSigSendType" SG_ 826 PTS_MUTE_RQ 5;
BA_ "GenSigCycleTime" SG_ 826 PTS_MUTE_RQ 500;
BA_ "FlexKomSigStartValue" SG_ 826 PTS_MUTE_RQ "00h";
BA_ "FlexKomSID" SG_ 826 PTS_MUTE_RQ 53;
BA_ "FlexKomSigStartPos" SG_ 826 PTS_MUTE_RQ 6;
BA_ "FlexKomSigLaenge" SG_ 826 PTS_MUTE_RQ 1;
BA_ "FlexKomSigName" SG_ 826 PTS_MUTE_RQ "PTS_MUTE_RQ";
BA_ "FlexKomComment" SG_ 826 PTS_MUTE_RQ "Audio system mute request from PTS; True = [1]";
BA_ "FlexKomIsMotorola" SG_ 826 PTS_MUTE_RQ 1;
BA_ "GenSigSNA" SG_ 826 PTS_MUTE_RQ "0h";
BA_ "GenSigSendType" SG_ 826 PTS_WARN 5;
BA_ "GenSigCycleTime" SG_ 826 PTS_WARN 500;
BA_ "FlexKomSigStartValue" SG_ 826 PTS_WARN "00h";
BA_ "GenSigTimeout_IC" SG_ 826 PTS_WARN 5250;
BA_ "FlexKomSID" SG_ 826 PTS_WARN 55;
BA_ "FlexKomSigStartPos" SG_ 826 PTS_WARN 7;
BA_ "FlexKomSigLaenge" SG_ 826 PTS_WARN 1;
BA_ "FlexKomSigName" SG_ 826 PTS_WARN "PTS_WARN";
BA_ "FlexKomComment" SG_ 826 PTS_WARN "PTS warning is on = [0], off = [1]";
BA_ "FlexKomIsMotorola" SG_ 826 PTS_WARN 1;
BA_ "GenSigSNA" SG_ 826 PTS_WARN "0h";
BA_ "GenSigSendType" SG_ 826 PTS_AlrFL 5;
BA_ "GenSigCycleTime" SG_ 826 PTS_AlrFL 500;
BA_ "FlexKomSigStartValue" SG_ 826 PTS_AlrFL "F0h";
BA_ "GenSigTimeout_IC" SG_ 826 PTS_AlrFL 5250;
BA_ "FlexKomSID" SG_ 826 PTS_AlrFL 1117;
BA_ "FlexKomSigStartPos" SG_ 826 PTS_AlrFL 15;
BA_ "FlexKomSigLaenge" SG_ 826 PTS_AlrFL 8;
BA_ "FlexKomSigName" SG_ 826 PTS_AlrFL "PTS_FL";
BA_ "FlexKomComment" SG_ 826 PTS_AlrFL "Park assist front left warnings";
BA_ "FlexKomIsMotorola" SG_ 826 PTS_AlrFL 1;
BA_ "GenSigSNA" SG_ 826 PTS_AlrFL "Fh";
BA_ "GenSigSendType" SG_ 826 PTS_SoundFL 5;
BA_ "GenSigCycleTime" SG_ 826 PTS_SoundFL 500;
BA_ "FlexKomSigStartValue" SG_ 826 PTS_SoundFL "F0h";
BA_ "GenSigStartValue" SG_ 826 PTS_SoundFL 3;
BA_ "FlexKomSID" SG_ 826 PTS_SoundFL 1117;
BA_ "FlexKomSigStartPos" SG_ 826 PTS_SoundFL 15;
BA_ "FlexKomSigLaenge" SG_ 826 PTS_SoundFL 8;
BA_ "FlexKomSigName" SG_ 826 PTS_SoundFL "PTS_FL";
BA_ "FlexKomComment" SG_ 826 PTS_SoundFL "Park assist front left warnings";
BA_ "FlexKomIsMotorola" SG_ 826 PTS_SoundFL 1;
BA_ "GenSigSNA" SG_ 826 PTS_SoundFL "3h";
BA_ "GenSigSendType" SG_ 826 PTS_GraphicFL 5;
BA_ "GenSigCycleTime" SG_ 826 PTS_GraphicFL 500;
BA_ "FlexKomSigStartValue" SG_ 826 PTS_GraphicFL "F0h";
BA_ "GenSigStartValue" SG_ 826 PTS_GraphicFL 3;
BA_ "GenSigTimeout_IC" SG_ 826 PTS_GraphicFL 5250;
BA_ "FlexKomSID" SG_ 826 PTS_GraphicFL 1117;
BA_ "FlexKomSigStartPos" SG_ 826 PTS_GraphicFL 15;
BA_ "FlexKomSigLaenge" SG_ 826 PTS_GraphicFL 8;
BA_ "FlexKomSigName" SG_ 826 PTS_GraphicFL "PTS_FL";
BA_ "FlexKomComment" SG_ 826 PTS_GraphicFL "Park assist front left warnings";
BA_ "FlexKomIsMotorola" SG_ 826 PTS_GraphicFL 1;
BA_ "GenSigSNA" SG_ 826 PTS_GraphicFL "3h";
BA_ "GenSigSendType" SG_ 826 PTS_AlrFR 5;
BA_ "GenSigCycleTime" SG_ 826 PTS_AlrFR 500;
BA_ "FlexKomSigStartValue" SG_ 826 PTS_AlrFR "F0h";
BA_ "GenSigTimeout_IC" SG_ 826 PTS_AlrFR 5250;
BA_ "FlexKomSID" SG_ 826 PTS_AlrFR 1118;
BA_ "FlexKomSigStartPos" SG_ 826 PTS_AlrFR 23;
BA_ "FlexKomSigLaenge" SG_ 826 PTS_AlrFR 8;
BA_ "FlexKomSigName" SG_ 826 PTS_AlrFR "PTS_FR";
BA_ "FlexKomComment" SG_ 826 PTS_AlrFR "Park assist front right warnings";
BA_ "FlexKomIsMotorola" SG_ 826 PTS_AlrFR 1;
BA_ "GenSigSNA" SG_ 826 PTS_AlrFR "Fh";
BA_ "GenSigSendType" SG_ 826 PTS_SoundFR 5;
BA_ "GenSigCycleTime" SG_ 826 PTS_SoundFR 500;
BA_ "FlexKomSigStartValue" SG_ 826 PTS_SoundFR "F0h";
BA_ "GenSigStartValue" SG_ 826 PTS_SoundFR 3;
BA_ "FlexKomSID" SG_ 826 PTS_SoundFR 1118;
BA_ "FlexKomSigStartPos" SG_ 826 PTS_SoundFR 23;
BA_ "FlexKomSigLaenge" SG_ 826 PTS_SoundFR 8;
BA_ "FlexKomSigName" SG_ 826 PTS_SoundFR "PTS_FR";
BA_ "FlexKomComment" SG_ 826 PTS_SoundFR "Park assist front right warnings";
BA_ "FlexKomIsMotorola" SG_ 826 PTS_SoundFR 1;
BA_ "GenSigSNA" SG_ 826 PTS_SoundFR "3h";
BA_ "GenSigSendType" SG_ 826 PTS_GraphicFR 5;
BA_ "GenSigCycleTime" SG_ 826 PTS_GraphicFR 500;
BA_ "FlexKomSigStartValue" SG_ 826 PTS_GraphicFR "F0h";
BA_ "GenSigStartValue" SG_ 826 PTS_GraphicFR 3;
BA_ "GenSigTimeout_IC" SG_ 826 PTS_GraphicFR 5250;
BA_ "FlexKomSID" SG_ 826 PTS_GraphicFR 1118;
BA_ "FlexKomSigStartPos" SG_ 826 PTS_GraphicFR 23;
BA_ "FlexKomSigLaenge" SG_ 826 PTS_GraphicFR 8;
BA_ "FlexKomSigName" SG_ 826 PTS_GraphicFR "PTS_FR";
BA_ "FlexKomComment" SG_ 826 PTS_GraphicFR "Park assist front right warnings";
BA_ "FlexKomIsMotorola" SG_ 826 PTS_GraphicFR 1;
BA_ "GenSigSNA" SG_ 826 PTS_GraphicFR "3h";
BA_ "GenSigSendType" SG_ 826 PTS_AlrRL 5;
BA_ "GenSigCycleTime" SG_ 826 PTS_AlrRL 500;
BA_ "FlexKomSigStartValue" SG_ 826 PTS_AlrRL "F0h";
BA_ "GenSigTimeout_CBC" SG_ 826 PTS_AlrRL 5250;
BA_ "GenSigTimeout_IC" SG_ 826 PTS_AlrRL 5250;
BA_ "FlexKomSID" SG_ 826 PTS_AlrRL 1119;
BA_ "FlexKomSigStartPos" SG_ 826 PTS_AlrRL 31;
BA_ "FlexKomSigLaenge" SG_ 826 PTS_AlrRL 8;
BA_ "FlexKomSigName" SG_ 826 PTS_AlrRL "PTS_RL";
BA_ "FlexKomComment" SG_ 826 PTS_AlrRL "Park assist rear left warnings";
BA_ "FlexKomIsMotorola" SG_ 826 PTS_AlrRL 1;
BA_ "GenSigSNA" SG_ 826 PTS_AlrRL "Fh";
BA_ "GenSigSendType" SG_ 826 PTS_SoundRL 5;
BA_ "GenSigCycleTime" SG_ 826 PTS_SoundRL 500;
BA_ "FlexKomSigStartValue" SG_ 826 PTS_SoundRL "F0h";
BA_ "GenSigStartValue" SG_ 826 PTS_SoundRL 3;
BA_ "FlexKomSID" SG_ 826 PTS_SoundRL 1119;
BA_ "FlexKomSigStartPos" SG_ 826 PTS_SoundRL 31;
BA_ "FlexKomSigLaenge" SG_ 826 PTS_SoundRL 8;
BA_ "FlexKomSigName" SG_ 826 PTS_SoundRL "PTS_RL";
BA_ "FlexKomComment" SG_ 826 PTS_SoundRL "Park assist rear left warnings";
BA_ "FlexKomIsMotorola" SG_ 826 PTS_SoundRL 1;
BA_ "GenSigSNA" SG_ 826 PTS_SoundRL "3h";
BA_ "GenSigSendType" SG_ 826 PTS_GraphicRL 5;
BA_ "GenSigCycleTime" SG_ 826 PTS_GraphicRL 500;
BA_ "FlexKomSigStartValue" SG_ 826 PTS_GraphicRL "F0h";
BA_ "GenSigStartValue" SG_ 826 PTS_GraphicRL 3;
BA_ "GenSigTimeout_IC" SG_ 826 PTS_GraphicRL 5250;
BA_ "FlexKomSID" SG_ 826 PTS_GraphicRL 1119;
BA_ "FlexKomSigStartPos" SG_ 826 PTS_GraphicRL 31;
BA_ "FlexKomSigLaenge" SG_ 826 PTS_GraphicRL 8;
BA_ "FlexKomSigName" SG_ 826 PTS_GraphicRL "PTS_RL";
BA_ "FlexKomComment" SG_ 826 PTS_GraphicRL "Park assist rear left warnings";
BA_ "FlexKomIsMotorola" SG_ 826 PTS_GraphicRL 1;
BA_ "GenSigSNA" SG_ 826 PTS_GraphicRL "3h";
BA_ "GenSigSendType" SG_ 826 PTS_AlrRR 5;
BA_ "GenSigCycleTime" SG_ 826 PTS_AlrRR 500;
BA_ "FlexKomSigStartValue" SG_ 826 PTS_AlrRR "F0h";
BA_ "GenSigTimeout_CBC" SG_ 826 PTS_AlrRR 5250;
BA_ "GenSigTimeout_IC" SG_ 826 PTS_AlrRR 5250;
BA_ "FlexKomSID" SG_ 826 PTS_AlrRR 1120;
BA_ "FlexKomSigStartPos" SG_ 826 PTS_AlrRR 39;
BA_ "FlexKomSigLaenge" SG_ 826 PTS_AlrRR 8;
BA_ "FlexKomSigName" SG_ 826 PTS_AlrRR "PTS_RR";
BA_ "FlexKomComment" SG_ 826 PTS_AlrRR "Park assist rear right warnings";
BA_ "FlexKomIsMotorola" SG_ 826 PTS_AlrRR 1;
BA_ "GenSigSNA" SG_ 826 PTS_AlrRR "Fh";
BA_ "GenSigSendType" SG_ 826 PTS_SoundRR 5;
BA_ "GenSigCycleTime" SG_ 826 PTS_SoundRR 500;
BA_ "FlexKomSigStartValue" SG_ 826 PTS_SoundRR "F0h";
BA_ "GenSigStartValue" SG_ 826 PTS_SoundRR 3;
BA_ "FlexKomSID" SG_ 826 PTS_SoundRR 1120;
BA_ "FlexKomSigStartPos" SG_ 826 PTS_SoundRR 39;
BA_ "FlexKomSigLaenge" SG_ 826 PTS_SoundRR 8;
BA_ "FlexKomSigName" SG_ 826 PTS_SoundRR "PTS_RR";
BA_ "FlexKomComment" SG_ 826 PTS_SoundRR "Park assist rear right warnings";
BA_ "FlexKomIsMotorola" SG_ 826 PTS_SoundRR 1;
BA_ "GenSigSNA" SG_ 826 PTS_SoundRR "3h";
BA_ "GenSigSendType" SG_ 826 PTS_GraphicRR 5;
BA_ "GenSigCycleTime" SG_ 826 PTS_GraphicRR 500;
BA_ "FlexKomSigStartValue" SG_ 826 PTS_GraphicRR "F0h";
BA_ "GenSigStartValue" SG_ 826 PTS_GraphicRR 3;
BA_ "GenSigTimeout_IC" SG_ 826 PTS_GraphicRR 5250;
BA_ "FlexKomSID" SG_ 826 PTS_GraphicRR 1120;
BA_ "FlexKomSigStartPos" SG_ 826 PTS_GraphicRR 39;
BA_ "FlexKomSigLaenge" SG_ 826 PTS_GraphicRR 8;
BA_ "FlexKomSigName" SG_ 826 PTS_GraphicRR "PTS_RR";
BA_ "FlexKomComment" SG_ 826 PTS_GraphicRR "Park assist rear right warnings";
BA_ "FlexKomIsMotorola" SG_ 826 PTS_GraphicRR 1;
BA_ "GenSigSNA" SG_ 826 PTS_GraphicRR "3h";
BA_ "GenSigSendType" SG_ 826 PTS_AlrFC 5;
BA_ "GenSigCycleTime" SG_ 826 PTS_AlrFC 500;
BA_ "FlexKomSigStartValue" SG_ 826 PTS_AlrFC "F0h";
BA_ "GenSigTimeout_IC" SG_ 826 PTS_AlrFC 5250;
BA_ "FlexKomSID" SG_ 826 PTS_AlrFC 1121;
BA_ "FlexKomSigStartPos" SG_ 826 PTS_AlrFC 47;
BA_ "FlexKomSigLaenge" SG_ 826 PTS_AlrFC 8;
BA_ "FlexKomSigName" SG_ 826 PTS_AlrFC "PTS_FC";
BA_ "FlexKomComment" SG_ 826 PTS_AlrFC "Park assist front center warnings";
BA_ "FlexKomIsMotorola" SG_ 826 PTS_AlrFC 1;
BA_ "GenSigSNA" SG_ 826 PTS_AlrFC "Fh";
BA_ "GenSigSendType" SG_ 826 PTS_SoundFC 5;
BA_ "GenSigCycleTime" SG_ 826 PTS_SoundFC 500;
BA_ "FlexKomSigStartValue" SG_ 826 PTS_SoundFC "F0h";
BA_ "GenSigStartValue" SG_ 826 PTS_SoundFC 3;
BA_ "FlexKomSID" SG_ 826 PTS_SoundFC 1121;
BA_ "FlexKomSigStartPos" SG_ 826 PTS_SoundFC 47;
BA_ "FlexKomSigLaenge" SG_ 826 PTS_SoundFC 8;
BA_ "FlexKomSigName" SG_ 826 PTS_SoundFC "PTS_FC";
BA_ "FlexKomComment" SG_ 826 PTS_SoundFC "Park assist front center warnings";
BA_ "FlexKomIsMotorola" SG_ 826 PTS_SoundFC 1;
BA_ "GenSigSNA" SG_ 826 PTS_SoundFC "3h";
BA_ "GenSigSendType" SG_ 826 PTS_GraphicFC 5;
BA_ "GenSigCycleTime" SG_ 826 PTS_GraphicFC 500;
BA_ "FlexKomSigStartValue" SG_ 826 PTS_GraphicFC "F0h";
BA_ "GenSigStartValue" SG_ 826 PTS_GraphicFC 3;
BA_ "GenSigTimeout_IC" SG_ 826 PTS_GraphicFC 5250;
BA_ "FlexKomSID" SG_ 826 PTS_GraphicFC 1121;
BA_ "FlexKomSigStartPos" SG_ 826 PTS_GraphicFC 47;
BA_ "FlexKomSigLaenge" SG_ 826 PTS_GraphicFC 8;
BA_ "FlexKomSigName" SG_ 826 PTS_GraphicFC "PTS_FC";
BA_ "FlexKomComment" SG_ 826 PTS_GraphicFC "Park assist front center warnings";
BA_ "FlexKomIsMotorola" SG_ 826 PTS_GraphicFC 1;
BA_ "GenSigSNA" SG_ 826 PTS_GraphicFC "3h";
BA_ "GenSigSendType" SG_ 826 PTS_AlrRC 5;
BA_ "GenSigCycleTime" SG_ 826 PTS_AlrRC 500;
BA_ "FlexKomSigStartValue" SG_ 826 PTS_AlrRC "F0h";
BA_ "GenSigTimeout_CBC" SG_ 826 PTS_AlrRC 5250;
BA_ "GenSigTimeout_IC" SG_ 826 PTS_AlrRC 5250;
BA_ "FlexKomSID" SG_ 826 PTS_AlrRC 1123;
BA_ "FlexKomSigStartPos" SG_ 826 PTS_AlrRC 55;
BA_ "FlexKomSigLaenge" SG_ 826 PTS_AlrRC 8;
BA_ "FlexKomSigName" SG_ 826 PTS_AlrRC "PTS_RC";
BA_ "FlexKomComment" SG_ 826 PTS_AlrRC "Park assist rear center warnings";
BA_ "FlexKomIsMotorola" SG_ 826 PTS_AlrRC 1;
BA_ "GenSigSNA" SG_ 826 PTS_AlrRC "Fh";
BA_ "GenSigSendType" SG_ 826 PTS_SoundRC 5;
BA_ "GenSigCycleTime" SG_ 826 PTS_SoundRC 500;
BA_ "FlexKomSigStartValue" SG_ 826 PTS_SoundRC "F0h";
BA_ "GenSigStartValue" SG_ 826 PTS_SoundRC 3;
BA_ "FlexKomSID" SG_ 826 PTS_SoundRC 1123;
BA_ "FlexKomSigStartPos" SG_ 826 PTS_SoundRC 55;
BA_ "FlexKomSigLaenge" SG_ 826 PTS_SoundRC 8;
BA_ "FlexKomSigName" SG_ 826 PTS_SoundRC "PTS_RC";
BA_ "FlexKomComment" SG_ 826 PTS_SoundRC "Park assist rear center warnings";
BA_ "FlexKomIsMotorola" SG_ 826 PTS_SoundRC 1;
BA_ "GenSigSNA" SG_ 826 PTS_SoundRC "3h";
BA_ "GenSigSendType" SG_ 826 PTS_GraphicRC 5;
BA_ "GenSigCycleTime" SG_ 826 PTS_GraphicRC 500;
BA_ "FlexKomSigStartValue" SG_ 826 PTS_GraphicRC "F0h";
BA_ "GenSigStartValue" SG_ 826 PTS_GraphicRC 3;
BA_ "GenSigTimeout_IC" SG_ 826 PTS_GraphicRC 5250;
BA_ "FlexKomSID" SG_ 826 PTS_GraphicRC 1123;
BA_ "FlexKomSigStartPos" SG_ 826 PTS_GraphicRC 55;
BA_ "FlexKomSigLaenge" SG_ 826 PTS_GraphicRC 8;
BA_ "FlexKomSigName" SG_ 826 PTS_GraphicRC "PTS_RC";
BA_ "FlexKomComment" SG_ 826 PTS_GraphicRC "Park assist rear center warnings";
BA_ "FlexKomIsMotorola" SG_ 826 PTS_GraphicRC 1;
BA_ "GenSigSNA" SG_ 826 PTS_GraphicRC "3h";
BA_ "GenSigSendType" SG_ 826 PTS_FT_RDY 5;
BA_ "GenSigCycleTime" SG_ 826 PTS_FT_RDY 500;
BA_ "FlexKomSigStartValue" SG_ 826 PTS_FT_RDY "00h";
BA_ "GenSigTimeout_IC" SG_ 826 PTS_FT_RDY 5250;
BA_ "FlexKomSID" SG_ 826 PTS_FT_RDY 1356;
BA_ "FlexKomSigStartPos" SG_ 826 PTS_FT_RDY 56;
BA_ "FlexKomSigLaenge" SG_ 826 PTS_FT_RDY 1;
BA_ "FlexKomSigName" SG_ 826 PTS_FT_RDY "PTS_FT_RDY";
BA_ "FlexKomComment" SG_ 826 PTS_FT_RDY "Front PTS sensor ready request; True = [1]";
BA_ "FlexKomIsMotorola" SG_ 826 PTS_FT_RDY 1;
BA_ "GenSigSNA" SG_ 826 PTS_FT_RDY "0h";
BA_ "GenSigSendType" SG_ 826 PTS_RR_RDY 5;
BA_ "GenSigCycleTime" SG_ 826 PTS_RR_RDY 500;
BA_ "FlexKomSigStartValue" SG_ 826 PTS_RR_RDY "00h";
BA_ "GenSigTimeout_IC" SG_ 826 PTS_RR_RDY 5250;
BA_ "FlexKomSID" SG_ 826 PTS_RR_RDY 1355;
BA_ "FlexKomSigStartPos" SG_ 826 PTS_RR_RDY 57;
BA_ "FlexKomSigLaenge" SG_ 826 PTS_RR_RDY 1;
BA_ "FlexKomSigName" SG_ 826 PTS_RR_RDY "PTS_RR_RDY";
BA_ "FlexKomComment" SG_ 826 PTS_RR_RDY "Rear PTS sensor ready request; True = [1]";
BA_ "FlexKomIsMotorola" SG_ 826 PTS_RR_RDY 1;
BA_ "GenSigSNA" SG_ 826 PTS_RR_RDY "0h";
BA_ "GenSigSendType" SG_ 826 PTS_FT_SRV 5;
BA_ "GenSigCycleTime" SG_ 826 PTS_FT_SRV 500;
BA_ "FlexKomSigStartValue" SG_ 826 PTS_FT_SRV "00h";
BA_ "GenSigTimeout_IC" SG_ 826 PTS_FT_SRV 5250;
BA_ "FlexKomSID" SG_ 826 PTS_FT_SRV 1354;
BA_ "FlexKomSigStartPos" SG_ 826 PTS_FT_SRV 58;
BA_ "FlexKomSigLaenge" SG_ 826 PTS_FT_SRV 1;
BA_ "FlexKomSigName" SG_ 826 PTS_FT_SRV "PTS_FT_SRV";
BA_ "FlexKomComment" SG_ 826 PTS_FT_SRV "Front PTS sensor service request; True = [1]";
BA_ "FlexKomIsMotorola" SG_ 826 PTS_FT_SRV 1;
BA_ "GenSigSNA" SG_ 826 PTS_FT_SRV "0h";
BA_ "GenSigSendType" SG_ 826 PTS_RR_SRV 5;
BA_ "GenSigCycleTime" SG_ 826 PTS_RR_SRV 500;
BA_ "FlexKomSigStartValue" SG_ 826 PTS_RR_SRV "00h";
BA_ "GenSigTimeout_IC" SG_ 826 PTS_RR_SRV 5250;
BA_ "FlexKomSID" SG_ 826 PTS_RR_SRV 1353;
BA_ "FlexKomSigStartPos" SG_ 826 PTS_RR_SRV 59;
BA_ "FlexKomSigLaenge" SG_ 826 PTS_RR_SRV 1;
BA_ "FlexKomSigName" SG_ 826 PTS_RR_SRV "PTS_RR_SRV";
BA_ "FlexKomComment" SG_ 826 PTS_RR_SRV "Rear PTS sensor service request; True = [1]";
BA_ "FlexKomIsMotorola" SG_ 826 PTS_RR_SRV 1;
BA_ "GenSigSNA" SG_ 826 PTS_RR_SRV "0h";
BA_ "GenSigSendType" SG_ 826 PTS_STAT 5;
BA_ "GenSigCycleTime" SG_ 826 PTS_STAT 500;
BA_ "FlexKomSigStartValue" SG_ 826 PTS_STAT "00h";
BA_ "GenSigTimeout_CBC" SG_ 826 PTS_STAT 5250;
BA_ "FlexKomSID" SG_ 826 PTS_STAT 1862;
BA_ "FlexKomSigStartPos" SG_ 826 PTS_STAT 61;
BA_ "FlexKomSigLaenge" SG_ 826 PTS_STAT 2;
BA_ "FlexKomSigName" SG_ 826 PTS_STAT "PTS_STAT";
BA_ "FlexKomComment" SG_ 826 PTS_STAT "Park Assist System - LED control status";
BA_ "FlexKomIsMotorola" SG_ 826 PTS_STAT 1;
BA_ "GenSigSNA" SG_ 826 PTS_STAT "3h";
BA_ "GenSigSendType" SG_ 826 PTS_FT_Enbl 5;
BA_ "GenSigCycleTime" SG_ 826 PTS_FT_Enbl 500;
BA_ "FlexKomSigStartValue" SG_ 826 PTS_FT_Enbl "00h";
BA_ "GenSigTimeout_IC" SG_ 826 PTS_FT_Enbl 5250;
BA_ "FlexKomSID" SG_ 826 PTS_FT_Enbl 1880;
BA_ "FlexKomSigStartPos" SG_ 826 PTS_FT_Enbl 63;
BA_ "FlexKomSigLaenge" SG_ 826 PTS_FT_Enbl 2;
BA_ "FlexKomSigName" SG_ 826 PTS_FT_Enbl "PTS_EnblSts";
BA_ "FlexKomComment" SG_ 826 PTS_FT_Enbl "PTS system front & rear enabled/disabled status";
BA_ "FlexKomIsMotorola" SG_ 826 PTS_FT_Enbl 1;
BA_ "GenSigSNA" SG_ 826 PTS_FT_Enbl "0h";
BA_ "GenSigSendType" SG_ 826 PTS_RR_Enbl 5;
BA_ "GenSigCycleTime" SG_ 826 PTS_RR_Enbl 500;
BA_ "FlexKomSigStartValue" SG_ 826 PTS_RR_Enbl "00h";
BA_ "GenSigTimeout_IC" SG_ 826 PTS_RR_Enbl 5250;
BA_ "FlexKomSID" SG_ 826 PTS_RR_Enbl 1880;
BA_ "FlexKomSigStartPos" SG_ 826 PTS_RR_Enbl 63;
BA_ "FlexKomSigLaenge" SG_ 826 PTS_RR_Enbl 2;
BA_ "FlexKomSigName" SG_ 826 PTS_RR_Enbl "PTS_EnblSts";
BA_ "FlexKomComment" SG_ 826 PTS_RR_Enbl "PTS system front & rear enabled/disabled status";
BA_ "FlexKomIsMotorola" SG_ 826 PTS_RR_Enbl 1;
BA_ "GenSigSNA" SG_ 826 PTS_RR_Enbl "0h";
BA_ "GenSigSendType" SG_ 828 RBT_P_Actv 5;
BA_ "GenSigCycleTime" SG_ 828 RBT_P_Actv 1000;
BA_ "FlexKomSigStartValue" SG_ 828 RBT_P_Actv "0000000000000000h";
BA_ "FlexKomSID" SG_ 828 RBT_P_Actv 844;
BA_ "FlexKomSigStartPos" SG_ 828 RBT_P_Actv 7;
BA_ "FlexKomSigLaenge" SG_ 828 RBT_P_Actv 64;
BA_ "FlexKomSigName" SG_ 828 RBT_P_Actv "RBT_P_PKT";
BA_ "FlexKomComment" SG_ 828 RBT_P_Actv "RBT_P_PKT";
BA_ "FlexKomIsMotorola" SG_ 828 RBT_P_Actv 1;
BA_ "GenSigSNA" SG_ 828 RBT_P_Actv "0h";
BA_ "GenSigSendType" SG_ 828 RBT_P_OK 5;
BA_ "GenSigCycleTime" SG_ 828 RBT_P_OK 1000;
BA_ "FlexKomSigStartValue" SG_ 828 RBT_P_OK "0000000000000000h";
BA_ "FlexKomSID" SG_ 828 RBT_P_OK 844;
BA_ "FlexKomSigStartPos" SG_ 828 RBT_P_OK 7;
BA_ "FlexKomSigLaenge" SG_ 828 RBT_P_OK 64;
BA_ "FlexKomSigName" SG_ 828 RBT_P_OK "RBT_P_PKT";
BA_ "FlexKomComment" SG_ 828 RBT_P_OK "RBT_P_PKT";
BA_ "FlexKomIsMotorola" SG_ 828 RBT_P_OK 1;
BA_ "GenSigSNA" SG_ 828 RBT_P_OK "0h";
BA_ "GenSigSendType" SG_ 828 PSG_RBT_Fault 5;
BA_ "GenSigCycleTime" SG_ 828 PSG_RBT_Fault 1000;
BA_ "FlexKomSigStartValue" SG_ 828 PSG_RBT_Fault "0000000000000000h";
BA_ "GenSigTimeout_IC" SG_ 828 PSG_RBT_Fault 10500;
BA_ "FlexKomSID" SG_ 828 PSG_RBT_Fault 844;
BA_ "FlexKomSigStartPos" SG_ 828 PSG_RBT_Fault 7;
BA_ "FlexKomSigLaenge" SG_ 828 PSG_RBT_Fault 64;
BA_ "FlexKomSigName" SG_ 828 PSG_RBT_Fault "RBT_P_PKT";
BA_ "FlexKomComment" SG_ 828 PSG_RBT_Fault "RBT_P_PKT";
BA_ "FlexKomIsMotorola" SG_ 828 PSG_RBT_Fault 1;
BA_ "GenSigSNA" SG_ 828 PSG_RBT_Fault "1h";
BA_ "GenSigSendType" SG_ 828 PSG_RBT_ACT 5;
BA_ "GenSigCycleTime" SG_ 828 PSG_RBT_ACT 1000;
BA_ "FlexKomSigStartValue" SG_ 828 PSG_RBT_ACT "0000000000000000h";
BA_ "FlexKomSID" SG_ 828 PSG_RBT_ACT 844;
BA_ "FlexKomSigStartPos" SG_ 828 PSG_RBT_ACT 7;
BA_ "FlexKomSigLaenge" SG_ 828 PSG_RBT_ACT 64;
BA_ "FlexKomSigName" SG_ 828 PSG_RBT_ACT "RBT_P_PKT";
BA_ "FlexKomComment" SG_ 828 PSG_RBT_ACT "RBT_P_PKT";
BA_ "FlexKomIsMotorola" SG_ 828 PSG_RBT_ACT 1;
BA_ "GenSigSNA" SG_ 828 PSG_RBT_ACT "3h";
BA_ "GenSigCycleTime" SG_ 831 FL_Lvl 200;
BA_ "FlexKomSigStartValue" SG_ 831 FL_Lvl "FEh";
BA_ "GenSigStartValue" SG_ 831 FL_Lvl 254;
BA_ "GenSigTimeout_CBC" SG_ 831 FL_Lvl 2100;
BA_ "GenSigTimeout_IC" SG_ 831 FL_Lvl 2100;
BA_ "FlexKomSID" SG_ 831 FL_Lvl 1448;
BA_ "FlexKomSigStartPos" SG_ 831 FL_Lvl 7;
BA_ "FlexKomSigLaenge" SG_ 831 FL_Lvl 8;
BA_ "FlexKomSigName" SG_ 831 FL_Lvl "FL_Lvl";
BA_ "FlexKomComment" SG_ 831 FL_Lvl "Front left level";
BA_ "FlexKomIsMotorola" SG_ 831 FL_Lvl 1;
BA_ "GenSigSNA" SG_ 831 FL_Lvl "FFh";
BA_ "GenSigCycleTime" SG_ 831 FR_Lvl 200;
BA_ "FlexKomSigStartValue" SG_ 831 FR_Lvl "FEh";
BA_ "GenSigStartValue" SG_ 831 FR_Lvl 254;
BA_ "GenSigTimeout_CBC" SG_ 831 FR_Lvl 2100;
BA_ "GenSigTimeout_IC" SG_ 831 FR_Lvl 2100;
BA_ "FlexKomSID" SG_ 831 FR_Lvl 1449;
BA_ "FlexKomSigStartPos" SG_ 831 FR_Lvl 15;
BA_ "FlexKomSigLaenge" SG_ 831 FR_Lvl 8;
BA_ "FlexKomSigName" SG_ 831 FR_Lvl "FR_Lvl";
BA_ "FlexKomComment" SG_ 831 FR_Lvl "Front right level";
BA_ "FlexKomIsMotorola" SG_ 831 FR_Lvl 1;
BA_ "GenSigSNA" SG_ 831 FR_Lvl "FFh";
BA_ "GenSigCycleTime" SG_ 831 RL_Lvl 200;
BA_ "FlexKomSigStartValue" SG_ 831 RL_Lvl "FEh";
BA_ "GenSigStartValue" SG_ 831 RL_Lvl 254;
BA_ "GenSigTimeout_CBC" SG_ 831 RL_Lvl 2100;
BA_ "GenSigTimeout_IC" SG_ 831 RL_Lvl 2100;
BA_ "FlexKomSID" SG_ 831 RL_Lvl 1450;
BA_ "FlexKomSigStartPos" SG_ 831 RL_Lvl 23;
BA_ "FlexKomSigLaenge" SG_ 831 RL_Lvl 8;
BA_ "FlexKomSigName" SG_ 831 RL_Lvl "RL_Lvl";
BA_ "FlexKomComment" SG_ 831 RL_Lvl "Rear left level";
BA_ "FlexKomIsMotorola" SG_ 831 RL_Lvl 1;
BA_ "GenSigSNA" SG_ 831 RL_Lvl "FFh";
BA_ "GenSigCycleTime" SG_ 831 RR_Lvl 200;
BA_ "FlexKomSigStartValue" SG_ 831 RR_Lvl "FEh";
BA_ "GenSigStartValue" SG_ 831 RR_Lvl 254;
BA_ "GenSigTimeout_CBC" SG_ 831 RR_Lvl 2100;
BA_ "GenSigTimeout_IC" SG_ 831 RR_Lvl 2100;
BA_ "FlexKomSID" SG_ 831 RR_Lvl 1451;
BA_ "FlexKomSigStartPos" SG_ 831 RR_Lvl 31;
BA_ "FlexKomSigLaenge" SG_ 831 RR_Lvl 8;
BA_ "FlexKomSigName" SG_ 831 RR_Lvl "RR_Lvl";
BA_ "FlexKomComment" SG_ 831 RR_Lvl "Rear right level";
BA_ "FlexKomIsMotorola" SG_ 831 RR_Lvl 1;
BA_ "GenSigSNA" SG_ 831 RR_Lvl "FFh";
BA_ "GenSigCycleTime" SG_ 831 FL_Lvl_Adj 200;
BA_ "FlexKomSigStartValue" SG_ 831 FL_Lvl_Adj "00h";
BA_ "FlexKomSID" SG_ 831 FL_Lvl_Adj 1452;
BA_ "FlexKomSigStartPos" SG_ 831 FL_Lvl_Adj 32;
BA_ "FlexKomSigLaenge" SG_ 831 FL_Lvl_Adj 1;
BA_ "FlexKomSigName" SG_ 831 FL_Lvl_Adj "FL_Lvl_Adj";
BA_ "FlexKomComment" SG_ 831 FL_Lvl_Adj "Front left level adjust (1=adjusting)";
BA_ "FlexKomIsMotorola" SG_ 831 FL_Lvl_Adj 1;
BA_ "GenSigSNA" SG_ 831 FL_Lvl_Adj "0h";
BA_ "GenSigCycleTime" SG_ 831 FR_Lvl_Adj 200;
BA_ "FlexKomSigStartValue" SG_ 831 FR_Lvl_Adj "00h";
BA_ "FlexKomSID" SG_ 831 FR_Lvl_Adj 1453;
BA_ "FlexKomSigStartPos" SG_ 831 FR_Lvl_Adj 33;
BA_ "FlexKomSigLaenge" SG_ 831 FR_Lvl_Adj 1;
BA_ "FlexKomSigName" SG_ 831 FR_Lvl_Adj "FR_Lvl_Adj";
BA_ "FlexKomComment" SG_ 831 FR_Lvl_Adj "Front right level adjust (1=adjusting)";
BA_ "FlexKomIsMotorola" SG_ 831 FR_Lvl_Adj 1;
BA_ "GenSigSNA" SG_ 831 FR_Lvl_Adj "0h";
BA_ "GenSigCycleTime" SG_ 831 RL_Lvl_Adj 200;
BA_ "FlexKomSigStartValue" SG_ 831 RL_Lvl_Adj "00h";
BA_ "FlexKomSID" SG_ 831 RL_Lvl_Adj 1454;
BA_ "FlexKomSigStartPos" SG_ 831 RL_Lvl_Adj 34;
BA_ "FlexKomSigLaenge" SG_ 831 RL_Lvl_Adj 1;
BA_ "FlexKomSigName" SG_ 831 RL_Lvl_Adj "RL_Lvl_Adj";
BA_ "FlexKomComment" SG_ 831 RL_Lvl_Adj "Rear left level adjust (1=adjusting)";
BA_ "FlexKomIsMotorola" SG_ 831 RL_Lvl_Adj 1;
BA_ "GenSigSNA" SG_ 831 RL_Lvl_Adj "0h";
BA_ "GenSigCycleTime" SG_ 831 RR_Lvl_Adj 200;
BA_ "FlexKomSigStartValue" SG_ 831 RR_Lvl_Adj "00h";
BA_ "FlexKomSID" SG_ 831 RR_Lvl_Adj 1457;
BA_ "FlexKomSigStartPos" SG_ 831 RR_Lvl_Adj 35;
BA_ "FlexKomSigLaenge" SG_ 831 RR_Lvl_Adj 1;
BA_ "FlexKomSigName" SG_ 831 RR_Lvl_Adj "RR_Lvl_Adj";
BA_ "FlexKomComment" SG_ 831 RR_Lvl_Adj "Rear right level adjust (1=adjusting)";
BA_ "FlexKomIsMotorola" SG_ 831 RR_Lvl_Adj 1;
BA_ "GenSigSNA" SG_ 831 RR_Lvl_Adj "0h";
BA_ "GenSigCycleTime" SG_ 831 LvlCalCmplt 200;
BA_ "FlexKomSigStartValue" SG_ 831 LvlCalCmplt "00h";
BA_ "FlexKomSID" SG_ 831 LvlCalCmplt 1456;
BA_ "FlexKomSigStartPos" SG_ 831 LvlCalCmplt 36;
BA_ "FlexKomSigLaenge" SG_ 831 LvlCalCmplt 1;
BA_ "FlexKomSigName" SG_ 831 LvlCalCmplt "LvlCalCmplt";
BA_ "FlexKomComment" SG_ 831 LvlCalCmplt "Level calibration complete; 1 = True";
BA_ "FlexKomIsMotorola" SG_ 831 LvlCalCmplt 1;
BA_ "GenSigSNA" SG_ 831 LvlCalCmplt "0h";
BA_ "GenSigCycleTime" SG_ 832 VehAccelPeak_X 500;
BA_ "FlexKomSigStartValue" SG_ 832 VehAccelPeak_X "FFh";
BA_ "GenSigStartValue" SG_ 832 VehAccelPeak_X 255;
BA_ "GenSigTimeout_CBC" SG_ 832 VehAccelPeak_X 5250;
BA_ "FlexKomSID" SG_ 832 VehAccelPeak_X 1431;
BA_ "FlexKomSigStartPos" SG_ 832 VehAccelPeak_X 7;
BA_ "FlexKomSigLaenge" SG_ 832 VehAccelPeak_X 8;
BA_ "FlexKomSigName" SG_ 832 VehAccelPeak_X "VehAccelPeak_X";
BA_ "FlexKomComment" SG_ 832 VehAccelPeak_X "Vehicle longitudinal acceleration peak (+ means fo";
BA_ "FlexKomIsMotorola" SG_ 832 VehAccelPeak_X 1;
BA_ "GenSigSNA" SG_ 832 VehAccelPeak_X "FFh";
BA_ "GenSigCycleTime" SG_ 832 VehAccelPeak_Y 500;
BA_ "FlexKomSigStartValue" SG_ 832 VehAccelPeak_Y "FFh";
BA_ "GenSigStartValue" SG_ 832 VehAccelPeak_Y 255;
BA_ "GenSigTimeout_CBC" SG_ 832 VehAccelPeak_Y 5250;
BA_ "FlexKomSID" SG_ 832 VehAccelPeak_Y 1432;
BA_ "FlexKomSigStartPos" SG_ 832 VehAccelPeak_Y 15;
BA_ "FlexKomSigLaenge" SG_ 832 VehAccelPeak_Y 8;
BA_ "FlexKomSigName" SG_ 832 VehAccelPeak_Y "VehAccelPeak_Y";
BA_ "FlexKomComment" SG_ 832 VehAccelPeak_Y "Vehicle lateral acceleration peak (+ means left)";
BA_ "FlexKomIsMotorola" SG_ 832 VehAccelPeak_Y 1;
BA_ "GenSigSNA" SG_ 832 VehAccelPeak_Y "FFh";
BA_ "GenSigCycleTime" SG_ 832 VehSpd_MPH 500;
BA_ "FlexKomSigStartValue" SG_ 832 VehSpd_MPH "00h";
BA_ "FlexKomSID" SG_ 832 VehSpd_MPH 1585;
BA_ "FlexKomSigStartPos" SG_ 832 VehSpd_MPH 47;
BA_ "FlexKomSigLaenge" SG_ 832 VehSpd_MPH 1;
BA_ "FlexKomSigName" SG_ 832 VehSpd_MPH "VehSpd_MPH";
BA_ "FlexKomComment" SG_ 832 VehSpd_MPH "Vehicle speed signal is in miles per hour format";
BA_ "FlexKomIsMotorola" SG_ 832 VehSpd_MPH 1;
BA_ "GenSigSNA" SG_ 832 VehSpd_MPH "0h";
BA_ "GenSigCycleTime" SG_ 832 VehSpdDisp 500;
BA_ "FlexKomSigStartValue" SG_ 832 VehSpdDisp "FFFFh";
BA_ "GenSigStartValue" SG_ 832 VehSpdDisp 65535;
BA_ "GenSigTimeout_CBC" SG_ 832 VehSpdDisp 5250;
BA_ "FlexKomSID" SG_ 832 VehSpdDisp 1430;
BA_ "FlexKomSigStartPos" SG_ 832 VehSpdDisp 55;
BA_ "FlexKomSigLaenge" SG_ 832 VehSpdDisp 16;
BA_ "FlexKomSigName" SG_ 832 VehSpdDisp "VehSpdDisp";
BA_ "FlexKomComment" SG_ 832 VehSpdDisp "Vehicle speed - displayed";
BA_ "FlexKomIsMotorola" SG_ 832 VehSpdDisp 1;
BA_ "GenSigSNA" SG_ 832 VehSpdDisp "FFFFh";
BA_ "GenSigSendType" SG_ 836 SPCR_RF_CHIME_RQ 5;
BA_ "GenSigCycleTime" SG_ 836 SPCR_RF_CHIME_RQ 1000;
BA_ "FlexKomSigStartValue" SG_ 836 SPCR_RF_CHIME_RQ "0000h";
BA_ "FlexKomSID" SG_ 836 SPCR_RF_CHIME_RQ 1015;
BA_ "FlexKomSigStartPos" SG_ 836 SPCR_RF_CHIME_RQ 7;
BA_ "FlexKomSigLaenge" SG_ 836 SPCR_RF_CHIME_RQ 16;
BA_ "FlexKomSigName" SG_ 836 SPCR_RF_CHIME_RQ "SPCR_CHIME_STAT";
BA_ "FlexKomComment" SG_ 836 SPCR_RF_CHIME_RQ "SPCR chime status";
BA_ "FlexKomIsMotorola" SG_ 836 SPCR_RF_CHIME_RQ 1;
BA_ "GenSigSNA" SG_ 836 SPCR_RF_CHIME_RQ "0h";
BA_ "GenSigSendType" SG_ 836 SPCR_LF_CHIME_RQ 5;
BA_ "GenSigCycleTime" SG_ 836 SPCR_LF_CHIME_RQ 1000;
BA_ "FlexKomSigStartValue" SG_ 836 SPCR_LF_CHIME_RQ "0000h";
BA_ "FlexKomSID" SG_ 836 SPCR_LF_CHIME_RQ 1015;
BA_ "FlexKomSigStartPos" SG_ 836 SPCR_LF_CHIME_RQ 7;
BA_ "FlexKomSigLaenge" SG_ 836 SPCR_LF_CHIME_RQ 16;
BA_ "FlexKomSigName" SG_ 836 SPCR_LF_CHIME_RQ "SPCR_CHIME_STAT";
BA_ "FlexKomComment" SG_ 836 SPCR_LF_CHIME_RQ "SPCR chime status";
BA_ "FlexKomIsMotorola" SG_ 836 SPCR_LF_CHIME_RQ 1;
BA_ "GenSigSNA" SG_ 836 SPCR_LF_CHIME_RQ "0h";
BA_ "GenSigSendType" SG_ 836 SPCR_RR_CHIME_RQ 5;
BA_ "GenSigCycleTime" SG_ 836 SPCR_RR_CHIME_RQ 1000;
BA_ "FlexKomSigStartValue" SG_ 836 SPCR_RR_CHIME_RQ "0000h";
BA_ "FlexKomSID" SG_ 836 SPCR_RR_CHIME_RQ 1015;
BA_ "FlexKomSigStartPos" SG_ 836 SPCR_RR_CHIME_RQ 7;
BA_ "FlexKomSigLaenge" SG_ 836 SPCR_RR_CHIME_RQ 16;
BA_ "FlexKomSigName" SG_ 836 SPCR_RR_CHIME_RQ "SPCR_CHIME_STAT";
BA_ "FlexKomComment" SG_ 836 SPCR_RR_CHIME_RQ "SPCR chime status";
BA_ "FlexKomIsMotorola" SG_ 836 SPCR_RR_CHIME_RQ 1;
BA_ "GenSigSNA" SG_ 836 SPCR_RR_CHIME_RQ "0h";
BA_ "GenSigSendType" SG_ 836 SPCR_LR_CHIME_RQ 5;
BA_ "GenSigCycleTime" SG_ 836 SPCR_LR_CHIME_RQ 1000;
BA_ "FlexKomSigStartValue" SG_ 836 SPCR_LR_CHIME_RQ "0000h";
BA_ "FlexKomSID" SG_ 836 SPCR_LR_CHIME_RQ 1015;
BA_ "FlexKomSigStartPos" SG_ 836 SPCR_LR_CHIME_RQ 7;
BA_ "FlexKomSigLaenge" SG_ 836 SPCR_LR_CHIME_RQ 16;
BA_ "FlexKomSigName" SG_ 836 SPCR_LR_CHIME_RQ "SPCR_CHIME_STAT";
BA_ "FlexKomComment" SG_ 836 SPCR_LR_CHIME_RQ "SPCR chime status";
BA_ "FlexKomIsMotorola" SG_ 836 SPCR_LR_CHIME_RQ 1;
BA_ "GenSigSNA" SG_ 836 SPCR_LR_CHIME_RQ "0h";
BA_ "GenSigSendType" SG_ 836 SPCR_CHIME_TYPE 5;
BA_ "GenSigCycleTime" SG_ 836 SPCR_CHIME_TYPE 1000;
BA_ "FlexKomSigStartValue" SG_ 836 SPCR_CHIME_TYPE "0000h";
BA_ "FlexKomSID" SG_ 836 SPCR_CHIME_TYPE 1015;
BA_ "FlexKomSigStartPos" SG_ 836 SPCR_CHIME_TYPE 7;
BA_ "FlexKomSigLaenge" SG_ 836 SPCR_CHIME_TYPE 16;
BA_ "FlexKomSigName" SG_ 836 SPCR_CHIME_TYPE "SPCR_CHIME_STAT";
BA_ "FlexKomComment" SG_ 836 SPCR_CHIME_TYPE "SPCR chime status";
BA_ "FlexKomIsMotorola" SG_ 836 SPCR_CHIME_TYPE 1;
BA_ "GenSigSNA" SG_ 836 SPCR_CHIME_TYPE "Fh";
BA_ "GenSigSendType" SG_ 836 SPCR_CHIME_RATE 5;
BA_ "GenSigCycleTime" SG_ 836 SPCR_CHIME_RATE 1000;
BA_ "FlexKomSigStartValue" SG_ 836 SPCR_CHIME_RATE "0000h";
BA_ "FlexKomSID" SG_ 836 SPCR_CHIME_RATE 1015;
BA_ "FlexKomSigStartPos" SG_ 836 SPCR_CHIME_RATE 7;
BA_ "FlexKomSigLaenge" SG_ 836 SPCR_CHIME_RATE 16;
BA_ "FlexKomSigName" SG_ 836 SPCR_CHIME_RATE "SPCR_CHIME_STAT";
BA_ "FlexKomComment" SG_ 836 SPCR_CHIME_RATE "SPCR chime status";
BA_ "FlexKomIsMotorola" SG_ 836 SPCR_CHIME_RATE 1;
BA_ "GenSigSNA" SG_ 836 SPCR_CHIME_RATE "0h";
BA_ "GenSigSendType" SG_ 838 AS_RF_CHIME_RQ 5;
BA_ "GenSigCycleTime" SG_ 838 AS_RF_CHIME_RQ 1000;
BA_ "FlexKomSigStartValue" SG_ 838 AS_RF_CHIME_RQ "0000h";
BA_ "FlexKomSID" SG_ 838 AS_RF_CHIME_RQ 1016;
BA_ "FlexKomSigStartPos" SG_ 838 AS_RF_CHIME_RQ 7;
BA_ "FlexKomSigLaenge" SG_ 838 AS_RF_CHIME_RQ 16;
BA_ "FlexKomSigName" SG_ 838 AS_RF_CHIME_RQ "AS_CHIME_STAT";
BA_ "FlexKomComment" SG_ 838 AS_RF_CHIME_RQ "AS chime status";
BA_ "FlexKomIsMotorola" SG_ 838 AS_RF_CHIME_RQ 1;
BA_ "GenSigSNA" SG_ 838 AS_RF_CHIME_RQ "0h";
BA_ "GenSigSendType" SG_ 838 AS_LF_CHIME_RQ 5;
BA_ "GenSigCycleTime" SG_ 838 AS_LF_CHIME_RQ 1000;
BA_ "FlexKomSigStartValue" SG_ 838 AS_LF_CHIME_RQ "0000h";
BA_ "FlexKomSID" SG_ 838 AS_LF_CHIME_RQ 1016;
BA_ "FlexKomSigStartPos" SG_ 838 AS_LF_CHIME_RQ 7;
BA_ "FlexKomSigLaenge" SG_ 838 AS_LF_CHIME_RQ 16;
BA_ "FlexKomSigName" SG_ 838 AS_LF_CHIME_RQ "AS_CHIME_STAT";
BA_ "FlexKomComment" SG_ 838 AS_LF_CHIME_RQ "AS chime status";
BA_ "FlexKomIsMotorola" SG_ 838 AS_LF_CHIME_RQ 1;
BA_ "GenSigSNA" SG_ 838 AS_LF_CHIME_RQ "0h";
BA_ "GenSigSendType" SG_ 838 AS_RR_CHIME_RQ 5;
BA_ "GenSigCycleTime" SG_ 838 AS_RR_CHIME_RQ 1000;
BA_ "FlexKomSigStartValue" SG_ 838 AS_RR_CHIME_RQ "0000h";
BA_ "FlexKomSID" SG_ 838 AS_RR_CHIME_RQ 1016;
BA_ "FlexKomSigStartPos" SG_ 838 AS_RR_CHIME_RQ 7;
BA_ "FlexKomSigLaenge" SG_ 838 AS_RR_CHIME_RQ 16;
BA_ "FlexKomSigName" SG_ 838 AS_RR_CHIME_RQ "AS_CHIME_STAT";
BA_ "FlexKomComment" SG_ 838 AS_RR_CHIME_RQ "AS chime status";
BA_ "FlexKomIsMotorola" SG_ 838 AS_RR_CHIME_RQ 1;
BA_ "GenSigSNA" SG_ 838 AS_RR_CHIME_RQ "0h";
BA_ "GenSigSendType" SG_ 838 AS_LR_CHIME_RQ 5;
BA_ "GenSigCycleTime" SG_ 838 AS_LR_CHIME_RQ 1000;
BA_ "FlexKomSigStartValue" SG_ 838 AS_LR_CHIME_RQ "0000h";
BA_ "FlexKomSID" SG_ 838 AS_LR_CHIME_RQ 1016;
BA_ "FlexKomSigStartPos" SG_ 838 AS_LR_CHIME_RQ 7;
BA_ "FlexKomSigLaenge" SG_ 838 AS_LR_CHIME_RQ 16;
BA_ "FlexKomSigName" SG_ 838 AS_LR_CHIME_RQ "AS_CHIME_STAT";
BA_ "FlexKomComment" SG_ 838 AS_LR_CHIME_RQ "AS chime status";
BA_ "FlexKomIsMotorola" SG_ 838 AS_LR_CHIME_RQ 1;
BA_ "GenSigSNA" SG_ 838 AS_LR_CHIME_RQ "0h";
BA_ "GenSigSendType" SG_ 838 AS_CHIME_TYPE 5;
BA_ "GenSigCycleTime" SG_ 838 AS_CHIME_TYPE 1000;
BA_ "FlexKomSigStartValue" SG_ 838 AS_CHIME_TYPE "0000h";
BA_ "GenSigTimeout_IC" SG_ 838 AS_CHIME_TYPE 10500;
BA_ "GenSigTimeout_ORC" SG_ 838 AS_CHIME_TYPE 3500;
BA_ "FlexKomSID" SG_ 838 AS_CHIME_TYPE 1016;
BA_ "FlexKomSigStartPos" SG_ 838 AS_CHIME_TYPE 7;
BA_ "FlexKomSigLaenge" SG_ 838 AS_CHIME_TYPE 16;
BA_ "FlexKomSigName" SG_ 838 AS_CHIME_TYPE "AS_CHIME_STAT";
BA_ "FlexKomComment" SG_ 838 AS_CHIME_TYPE "AS chime status";
BA_ "FlexKomIsMotorola" SG_ 838 AS_CHIME_TYPE 1;
BA_ "GenSigSNA" SG_ 838 AS_CHIME_TYPE "Fh";
BA_ "GenSigSendType" SG_ 838 AS_CHIME_REP_RATE 5;
BA_ "GenSigCycleTime" SG_ 838 AS_CHIME_REP_RATE 1000;
BA_ "FlexKomSigStartValue" SG_ 838 AS_CHIME_REP_RATE "0000h";
BA_ "FlexKomSID" SG_ 838 AS_CHIME_REP_RATE 1016;
BA_ "FlexKomSigStartPos" SG_ 838 AS_CHIME_REP_RATE 7;
BA_ "FlexKomSigLaenge" SG_ 838 AS_CHIME_REP_RATE 16;
BA_ "FlexKomSigName" SG_ 838 AS_CHIME_REP_RATE "AS_CHIME_STAT";
BA_ "FlexKomComment" SG_ 838 AS_CHIME_REP_RATE "AS chime status";
BA_ "FlexKomIsMotorola" SG_ 838 AS_CHIME_REP_RATE 1;
BA_ "GenSigSNA" SG_ 838 AS_CHIME_REP_RATE "0h";
BA_ "GenSigSendType" SG_ 840 FailSafeError 1;
BA_ "FlexKomSigStartValue" SG_ 840 FailSafeError "0000h";
BA_ "FlexKomSID" SG_ 840 FailSafeError 13;
BA_ "FlexKomSigStartPos" SG_ 840 FailSafeError 7;
BA_ "FlexKomSigLaenge" SG_ 840 FailSafeError 16;
BA_ "FlexKomSigName" SG_ 840 FailSafeError "FailSafeError";
BA_ "FlexKomComment" SG_ 840 FailSafeError "Fail safe error";
BA_ "FlexKomIsMotorola" SG_ 840 FailSafeError 1;
BA_ "GenSigSNA" SG_ 840 FailSafeError "FFFFh";
BA_ "GenSigSendType" SG_ 844 ASCM_Stat 5;
BA_ "GenSigCycleTime" SG_ 844 ASCM_Stat 1000;
BA_ "FlexKomSigStartValue" SG_ 844 ASCM_Stat "00h";
BA_ "GenSigTimeout_CBC" SG_ 844 ASCM_Stat 10500;
BA_ "GenSigTimeout_IC" SG_ 844 ASCM_Stat 10500;
BA_ "FlexKomSID" SG_ 844 ASCM_Stat 1459;
BA_ "FlexKomSigStartPos" SG_ 844 ASCM_Stat 3;
BA_ "FlexKomSigLaenge" SG_ 844 ASCM_Stat 4;
BA_ "FlexKomSigName" SG_ 844 ASCM_Stat "ASCM_Stat";
BA_ "FlexKomComment" SG_ 844 ASCM_Stat "Air suspension status";
BA_ "FlexKomIsMotorola" SG_ 844 ASCM_Stat 1;
BA_ "GenSigSNA" SG_ 844 ASCM_Stat "Fh";
BA_ "GenSigSendType" SG_ 844 ASCM_StatDisp 5;
BA_ "GenSigCycleTime" SG_ 844 ASCM_StatDisp 1000;
BA_ "FlexKomSigStartValue" SG_ 844 ASCM_StatDisp "00h";
BA_ "GenSigTimeout_CBC" SG_ 844 ASCM_StatDisp 10500;
BA_ "GenSigTimeout_IC" SG_ 844 ASCM_StatDisp 10500;
BA_ "FlexKomSID" SG_ 844 ASCM_StatDisp 1626;
BA_ "FlexKomSigStartPos" SG_ 844 ASCM_StatDisp 7;
BA_ "FlexKomSigLaenge" SG_ 844 ASCM_StatDisp 4;
BA_ "FlexKomSigName" SG_ 844 ASCM_StatDisp "ASCM_StatDisp";
BA_ "FlexKomComment" SG_ 844 ASCM_StatDisp "Air suspension status for display";
BA_ "FlexKomIsMotorola" SG_ 844 ASCM_StatDisp 1;
BA_ "GenSigSNA" SG_ 844 ASCM_StatDisp "Fh";
BA_ "GenSigSendType" SG_ 844 ASCM_HMI_Stat 5;
BA_ "GenSigCycleTime" SG_ 844 ASCM_HMI_Stat 1000;
BA_ "FlexKomSigStartValue" SG_ 844 ASCM_HMI_Stat "8Fh";
BA_ "GenSigStartValue" SG_ 844 ASCM_HMI_Stat 15;
BA_ "GenSigTimeout_CBC" SG_ 844 ASCM_HMI_Stat 10500;
BA_ "GenSigTimeout_IC" SG_ 844 ASCM_HMI_Stat 10500;
BA_ "FlexKomSID" SG_ 844 ASCM_HMI_Stat 1458;
BA_ "FlexKomSigStartPos" SG_ 844 ASCM_HMI_Stat 15;
BA_ "FlexKomSigLaenge" SG_ 844 ASCM_HMI_Stat 8;
BA_ "FlexKomSigName" SG_ 844 ASCM_HMI_Stat "ASCM_Info";
BA_ "FlexKomComment" SG_ 844 ASCM_HMI_Stat "General ASCM system information";
BA_ "FlexKomIsMotorola" SG_ 844 ASCM_HMI_Stat 1;
BA_ "GenSigSNA" SG_ 844 ASCM_HMI_Stat "Fh";
BA_ "GenSigSendType" SG_ 844 ASCM_Srv 5;
BA_ "GenSigCycleTime" SG_ 844 ASCM_Srv 1000;
BA_ "FlexKomSigStartValue" SG_ 844 ASCM_Srv "8Fh";
BA_ "GenSigTimeout_IC" SG_ 844 ASCM_Srv 10500;
BA_ "FlexKomSID" SG_ 844 ASCM_Srv 1458;
BA_ "FlexKomSigStartPos" SG_ 844 ASCM_Srv 15;
BA_ "FlexKomSigLaenge" SG_ 844 ASCM_Srv 8;
BA_ "FlexKomSigName" SG_ 844 ASCM_Srv "ASCM_Info";
BA_ "FlexKomComment" SG_ 844 ASCM_Srv "General ASCM system information";
BA_ "FlexKomIsMotorola" SG_ 844 ASCM_Srv 1;
BA_ "GenSigSNA" SG_ 844 ASCM_Srv "0h";
BA_ "GenSigSendType" SG_ 844 ASCM_SysFail 5;
BA_ "GenSigCycleTime" SG_ 844 ASCM_SysFail 1000;
BA_ "FlexKomSigStartValue" SG_ 844 ASCM_SysFail "8Fh";
BA_ "GenSigTimeout_IC" SG_ 844 ASCM_SysFail 10500;
BA_ "FlexKomSID" SG_ 844 ASCM_SysFail 1458;
BA_ "FlexKomSigStartPos" SG_ 844 ASCM_SysFail 15;
BA_ "FlexKomSigLaenge" SG_ 844 ASCM_SysFail 8;
BA_ "FlexKomSigName" SG_ 844 ASCM_SysFail "ASCM_Info";
BA_ "FlexKomComment" SG_ 844 ASCM_SysFail "General ASCM system information";
BA_ "FlexKomIsMotorola" SG_ 844 ASCM_SysFail 1;
BA_ "GenSigSNA" SG_ 844 ASCM_SysFail "0h";
BA_ "GenSigSendType" SG_ 844 ASCM_TJM 5;
BA_ "GenSigCycleTime" SG_ 844 ASCM_TJM 1000;
BA_ "FlexKomSigStartValue" SG_ 844 ASCM_TJM "8Fh";
BA_ "GenSigTimeout_IC" SG_ 844 ASCM_TJM 10500;
BA_ "FlexKomSID" SG_ 844 ASCM_TJM 1458;
BA_ "FlexKomSigStartPos" SG_ 844 ASCM_TJM 15;
BA_ "FlexKomSigLaenge" SG_ 844 ASCM_TJM 8;
BA_ "FlexKomSigName" SG_ 844 ASCM_TJM "ASCM_Info";
BA_ "FlexKomComment" SG_ 844 ASCM_TJM "General ASCM system information";
BA_ "FlexKomIsMotorola" SG_ 844 ASCM_TJM 1;
BA_ "GenSigSNA" SG_ 844 ASCM_TJM "0h";
BA_ "GenSigSendType" SG_ 844 ASCM_AeroDsbl 5;
BA_ "GenSigCycleTime" SG_ 844 ASCM_AeroDsbl 1000;
BA_ "FlexKomSigStartValue" SG_ 844 ASCM_AeroDsbl "8Fh";
BA_ "GenSigStartValue" SG_ 844 ASCM_AeroDsbl 1;
BA_ "GenSigTimeout_IC" SG_ 844 ASCM_AeroDsbl 10500;
BA_ "FlexKomSID" SG_ 844 ASCM_AeroDsbl 1458;
BA_ "FlexKomSigStartPos" SG_ 844 ASCM_AeroDsbl 15;
BA_ "FlexKomSigLaenge" SG_ 844 ASCM_AeroDsbl 8;
BA_ "FlexKomSigName" SG_ 844 ASCM_AeroDsbl "ASCM_Info";
BA_ "FlexKomComment" SG_ 844 ASCM_AeroDsbl "General ASCM system information";
BA_ "FlexKomIsMotorola" SG_ 844 ASCM_AeroDsbl 1;
BA_ "GenSigSNA" SG_ 844 ASCM_AeroDsbl "1h";
BA_ "GenSigSendType" SG_ 844 Tgt_Level 5;
BA_ "GenSigCycleTime" SG_ 844 Tgt_Level 1000;
BA_ "FlexKomSigStartValue" SG_ 844 Tgt_Level "3Fh";
BA_ "GenSigStartValue" SG_ 844 Tgt_Level 7;
BA_ "GenSigTimeout_CBC" SG_ 844 Tgt_Level 10500;
BA_ "GenSigTimeout_IC" SG_ 844 Tgt_Level 10500;
BA_ "FlexKomSID" SG_ 844 Tgt_Level 1460;
BA_ "FlexKomSigStartPos" SG_ 844 Tgt_Level 23;
BA_ "FlexKomSigLaenge" SG_ 844 Tgt_Level 8;
BA_ "FlexKomSigName" SG_ 844 Tgt_Level "Tgt_LvlPkt";
BA_ "FlexKomComment" SG_ 844 Tgt_Level "Target Level packet";
BA_ "FlexKomIsMotorola" SG_ 844 Tgt_Level 1;
BA_ "GenSigSNA" SG_ 844 Tgt_Level "7h";
BA_ "GenSigSendType" SG_ 844 Loading_Lv 5;
BA_ "GenSigCycleTime" SG_ 844 Loading_Lv 1000;
BA_ "FlexKomSigStartValue" SG_ 844 Loading_Lv "3Fh";
BA_ "GenSigStartValue" SG_ 844 Loading_Lv 7;
BA_ "GenSigTimeout_CBC" SG_ 844 Loading_Lv 10500;
BA_ "GenSigTimeout_IC" SG_ 844 Loading_Lv 10500;
BA_ "FlexKomSID" SG_ 844 Loading_Lv 1460;
BA_ "FlexKomSigStartPos" SG_ 844 Loading_Lv 23;
BA_ "FlexKomSigLaenge" SG_ 844 Loading_Lv 8;
BA_ "FlexKomSigName" SG_ 844 Loading_Lv "Tgt_LvlPkt";
BA_ "FlexKomComment" SG_ 844 Loading_Lv "Target Level packet";
BA_ "FlexKomIsMotorola" SG_ 844 Loading_Lv 1;
BA_ "GenSigSNA" SG_ 844 Loading_Lv "7h";
BA_ "GenSigSendType" SG_ 844 ASCM_RemStat 5;
BA_ "GenSigCycleTime" SG_ 844 ASCM_RemStat 1000;
BA_ "FlexKomSigStartValue" SG_ 844 ASCM_RemStat "00h";
BA_ "GenSigTimeout_RF_HUB" SG_ 844 ASCM_RemStat 10500;
BA_ "GenSigTimeout_CBC" SG_ 844 ASCM_RemStat 10500;
BA_ "GenSigTimeout_IC" SG_ 844 ASCM_RemStat 10500;
BA_ "FlexKomSID" SG_ 844 ASCM_RemStat 1775;
BA_ "FlexKomSigStartPos" SG_ 844 ASCM_RemStat 23;
BA_ "FlexKomSigLaenge" SG_ 844 ASCM_RemStat 2;
BA_ "FlexKomSigName" SG_ 844 ASCM_RemStat "ASCM_RemStat";
BA_ "FlexKomComment" SG_ 844 ASCM_RemStat "ASCM remote lowering status";
BA_ "FlexKomIsMotorola" SG_ 844 ASCM_RemStat 1;
BA_ "GenSigSNA" SG_ 844 ASCM_RemStat "3h";
BA_ "GenSigSendType" SG_ 844 ASCM_OR2_Rq 5;
BA_ "GenSigCycleTime" SG_ 844 ASCM_OR2_Rq 1000;
BA_ "FlexKomSigStartValue" SG_ 844 ASCM_OR2_Rq "00h";
BA_ "GenSigTimeout_CBC" SG_ 844 ASCM_OR2_Rq 10500;
BA_ "GenSigTimeout_IC" SG_ 844 ASCM_OR2_Rq 10500;
BA_ "FlexKomSID" SG_ 844 ASCM_OR2_Rq 1461;
BA_ "FlexKomSigStartPos" SG_ 844 ASCM_OR2_Rq 31;
BA_ "FlexKomSigLaenge" SG_ 844 ASCM_OR2_Rq 8;
BA_ "FlexKomSigName" SG_ 844 ASCM_OR2_Rq "IndStatPkt";
BA_ "FlexKomComment" SG_ 844 ASCM_OR2_Rq "Indicator status packet";
BA_ "FlexKomIsMotorola" SG_ 844 ASCM_OR2_Rq 1;
BA_ "GenSigSNA" SG_ 844 ASCM_OR2_Rq "3h";
BA_ "GenSigSendType" SG_ 844 ASCM_OR1_Rq 5;
BA_ "GenSigCycleTime" SG_ 844 ASCM_OR1_Rq 1000;
BA_ "FlexKomSigStartValue" SG_ 844 ASCM_OR1_Rq "00h";
BA_ "GenSigTimeout_CBC" SG_ 844 ASCM_OR1_Rq 10500;
BA_ "GenSigTimeout_IC" SG_ 844 ASCM_OR1_Rq 10500;
BA_ "FlexKomSID" SG_ 844 ASCM_OR1_Rq 1461;
BA_ "FlexKomSigStartPos" SG_ 844 ASCM_OR1_Rq 31;
BA_ "FlexKomSigLaenge" SG_ 844 ASCM_OR1_Rq 8;
BA_ "FlexKomSigName" SG_ 844 ASCM_OR1_Rq "IndStatPkt";
BA_ "FlexKomComment" SG_ 844 ASCM_OR1_Rq "Indicator status packet";
BA_ "FlexKomIsMotorola" SG_ 844 ASCM_OR1_Rq 1;
BA_ "GenSigSNA" SG_ 844 ASCM_OR1_Rq "3h";
BA_ "GenSigSendType" SG_ 844 ASCM_Norm_Rq 5;
BA_ "GenSigCycleTime" SG_ 844 ASCM_Norm_Rq 1000;
BA_ "FlexKomSigStartValue" SG_ 844 ASCM_Norm_Rq "00h";
BA_ "GenSigTimeout_CBC" SG_ 844 ASCM_Norm_Rq 10500;
BA_ "GenSigTimeout_IC" SG_ 844 ASCM_Norm_Rq 10500;
BA_ "FlexKomSID" SG_ 844 ASCM_Norm_Rq 1461;
BA_ "FlexKomSigStartPos" SG_ 844 ASCM_Norm_Rq 31;
BA_ "FlexKomSigLaenge" SG_ 844 ASCM_Norm_Rq 8;
BA_ "FlexKomSigName" SG_ 844 ASCM_Norm_Rq "IndStatPkt";
BA_ "FlexKomComment" SG_ 844 ASCM_Norm_Rq "Indicator status packet";
BA_ "FlexKomIsMotorola" SG_ 844 ASCM_Norm_Rq 1;
BA_ "GenSigSNA" SG_ 844 ASCM_Norm_Rq "3h";
BA_ "GenSigSendType" SG_ 844 ASCM_Exit_Rq 5;
BA_ "GenSigCycleTime" SG_ 844 ASCM_Exit_Rq 1000;
BA_ "FlexKomSigStartValue" SG_ 844 ASCM_Exit_Rq "00h";
BA_ "GenSigTimeout_CBC" SG_ 844 ASCM_Exit_Rq 10500;
BA_ "GenSigTimeout_IC" SG_ 844 ASCM_Exit_Rq 10500;
BA_ "FlexKomSID" SG_ 844 ASCM_Exit_Rq 1461;
BA_ "FlexKomSigStartPos" SG_ 844 ASCM_Exit_Rq 31;
BA_ "FlexKomSigLaenge" SG_ 844 ASCM_Exit_Rq 8;
BA_ "FlexKomSigName" SG_ 844 ASCM_Exit_Rq "IndStatPkt";
BA_ "FlexKomComment" SG_ 844 ASCM_Exit_Rq "Indicator status packet";
BA_ "FlexKomIsMotorola" SG_ 844 ASCM_Exit_Rq 1;
BA_ "GenSigSNA" SG_ 844 ASCM_Exit_Rq "3h";
BA_ "GenSigSendType" SG_ 844 ALM_Enbl 5;
BA_ "GenSigCycleTime" SG_ 844 ALM_Enbl 1000;
BA_ "FlexKomSigStartValue" SG_ 844 ALM_Enbl "00h";
BA_ "GenSigTimeout_IC" SG_ 844 ALM_Enbl 10500;
BA_ "FlexKomSID" SG_ 844 ALM_Enbl 1627;
BA_ "FlexKomSigStartPos" SG_ 844 ALM_Enbl 39;
BA_ "FlexKomSigLaenge" SG_ 844 ALM_Enbl 8;
BA_ "FlexKomSigName" SG_ 844 ALM_Enbl "ASCM_Info2";
BA_ "FlexKomComment" SG_ 844 ALM_Enbl "General ASCM system information #2";
BA_ "FlexKomIsMotorola" SG_ 844 ALM_Enbl 1;
BA_ "GenSigSNA" SG_ 844 ALM_Enbl "0h";
BA_ "GenSigSendType" SG_ 844 WAL_Enbl 5;
BA_ "GenSigCycleTime" SG_ 844 WAL_Enbl 1000;
BA_ "FlexKomSigStartValue" SG_ 844 WAL_Enbl "00h";
BA_ "GenSigTimeout_IC" SG_ 844 WAL_Enbl 10500;
BA_ "FlexKomSID" SG_ 844 WAL_Enbl 1627;
BA_ "FlexKomSigStartPos" SG_ 844 WAL_Enbl 39;
BA_ "FlexKomSigLaenge" SG_ 844 WAL_Enbl 8;
BA_ "FlexKomSigName" SG_ 844 WAL_Enbl "ASCM_Info2";
BA_ "FlexKomComment" SG_ 844 WAL_Enbl "General ASCM system information #2";
BA_ "FlexKomIsMotorola" SG_ 844 WAL_Enbl 1;
BA_ "GenSigSNA" SG_ 844 WAL_Enbl "0h";
BA_ "GenSigSendType" SG_ 844 ASCM_WarnOnly 5;
BA_ "GenSigCycleTime" SG_ 844 ASCM_WarnOnly 1000;
BA_ "FlexKomSigStartValue" SG_ 844 ASCM_WarnOnly "00h";
BA_ "GenSigTimeout_IC" SG_ 844 ASCM_WarnOnly 10500;
BA_ "FlexKomSID" SG_ 844 ASCM_WarnOnly 1627;
BA_ "FlexKomSigStartPos" SG_ 844 ASCM_WarnOnly 39;
BA_ "FlexKomSigLaenge" SG_ 844 ASCM_WarnOnly 8;
BA_ "FlexKomSigName" SG_ 844 ASCM_WarnOnly "ASCM_Info2";
BA_ "FlexKomComment" SG_ 844 ASCM_WarnOnly "General ASCM system information #2";
BA_ "FlexKomIsMotorola" SG_ 844 ASCM_WarnOnly 1;
BA_ "GenSigSNA" SG_ 844 ASCM_WarnOnly "0h";
BA_ "GenSigSendType" SG_ 844 LvlAdjStat 5;
BA_ "GenSigCycleTime" SG_ 844 LvlAdjStat 1000;
BA_ "FlexKomSigStartValue" SG_ 844 LvlAdjStat "00h";
BA_ "GenSigTimeout_CBC" SG_ 844 LvlAdjStat 10500;
BA_ "GenSigTimeout_IC" SG_ 844 LvlAdjStat 10500;
BA_ "FlexKomSID" SG_ 844 LvlAdjStat 1627;
BA_ "FlexKomSigStartPos" SG_ 844 LvlAdjStat 39;
BA_ "FlexKomSigLaenge" SG_ 844 LvlAdjStat 8;
BA_ "FlexKomSigName" SG_ 844 LvlAdjStat "ASCM_Info2";
BA_ "FlexKomComment" SG_ 844 LvlAdjStat "General ASCM system information #2";
BA_ "FlexKomIsMotorola" SG_ 844 LvlAdjStat 1;
BA_ "GenSigSNA" SG_ 844 LvlAdjStat "0h";
BA_ "GenSigSendType" SG_ 844 TM_Enbl 5;
BA_ "GenSigCycleTime" SG_ 844 TM_Enbl 1000;
BA_ "FlexKomSigStartValue" SG_ 844 TM_Enbl "00h";
BA_ "GenSigTimeout_IC" SG_ 844 TM_Enbl 10500;
BA_ "FlexKomSID" SG_ 844 TM_Enbl 1627;
BA_ "FlexKomSigStartPos" SG_ 844 TM_Enbl 39;
BA_ "FlexKomSigLaenge" SG_ 844 TM_Enbl 8;
BA_ "FlexKomSigName" SG_ 844 TM_Enbl "ASCM_Info2";
BA_ "FlexKomComment" SG_ 844 TM_Enbl "General ASCM system information #2";
BA_ "FlexKomIsMotorola" SG_ 844 TM_Enbl 1;
BA_ "GenSigSNA" SG_ 844 TM_Enbl "0h";
BA_ "GenSigSendType" SG_ 844 LowShftToPark 5;
BA_ "GenSigCycleTime" SG_ 844 LowShftToPark 1000;
BA_ "FlexKomSigStartValue" SG_ 844 LowShftToPark "00h";
BA_ "GenSigTimeout_IC" SG_ 844 LowShftToPark 10500;
BA_ "FlexKomSID" SG_ 844 LowShftToPark 1627;
BA_ "FlexKomSigStartPos" SG_ 844 LowShftToPark 39;
BA_ "FlexKomSigLaenge" SG_ 844 LowShftToPark 8;
BA_ "FlexKomSigName" SG_ 844 LowShftToPark "ASCM_Info2";
BA_ "FlexKomComment" SG_ 844 LowShftToPark "General ASCM system information #2";
BA_ "FlexKomIsMotorola" SG_ 844 LowShftToPark 1;
BA_ "GenSigSNA" SG_ 844 LowShftToPark "0h";
BA_ "GenSigSendType" SG_ 847 RFMemRq 1;
BA_ "FlexKomSigStartValue" SG_ 847 RFMemRq "00h";
BA_ "FlexKomSID" SG_ 847 RFMemRq 1513;
BA_ "FlexKomSigStartPos" SG_ 847 RFMemRq 7;
BA_ "FlexKomSigLaenge" SG_ 847 RFMemRq 8;
BA_ "FlexKomSigName" SG_ 847 RFMemRq "RFMemPkt";
BA_ "FlexKomComment" SG_ 847 RFMemRq "RF memory packet";
BA_ "FlexKomIsMotorola" SG_ 847 RFMemRq 1;
BA_ "GenSigSNA" SG_ 847 RFMemRq "0h";
BA_ "GenSigSendType" SG_ 847 RF_FobNum 1;
BA_ "FlexKomSigStartValue" SG_ 847 RF_FobNum "00h";
BA_ "FlexKomSID" SG_ 847 RF_FobNum 1513;
BA_ "FlexKomSigStartPos" SG_ 847 RF_FobNum 7;
BA_ "FlexKomSigLaenge" SG_ 847 RF_FobNum 8;
BA_ "FlexKomSigName" SG_ 847 RF_FobNum "RFMemPkt";
BA_ "FlexKomComment" SG_ 847 RF_FobNum "RF memory packet";
BA_ "FlexKomIsMotorola" SG_ 847 RF_FobNum 1;
BA_ "GenSigSNA" SG_ 847 RF_FobNum "Fh";
BA_ "GenSigCycleTime" SG_ 848 DateTmSec 1000;
BA_ "FlexKomSigStartValue" SG_ 848 DateTmSec "FFFFFFh";
BA_ "GenSigStartValue" SG_ 848 DateTmSec 255;
BA_ "GenSigTimeout_RF_HUB" SG_ 848 DateTmSec 10500;
BA_ "GenSigTimeout_IC" SG_ 848 DateTmSec 10500;
BA_ "FlexKomSID" SG_ 848 DateTmSec 398;
BA_ "FlexKomSigStartPos" SG_ 848 DateTmSec 7;
BA_ "FlexKomSigLaenge" SG_ 848 DateTmSec 24;
BA_ "FlexKomSigName" SG_ 848 DateTmSec "Clock";
BA_ "FlexKomComment" SG_ 848 DateTmSec "Time of day clock";
BA_ "FlexKomIsMotorola" SG_ 848 DateTmSec 1;
BA_ "GenSigSNA" SG_ 848 DateTmSec "FFh";
BA_ "GenSigCycleTime" SG_ 848 DateTmMinute 1000;
BA_ "FlexKomSigStartValue" SG_ 848 DateTmMinute "FFFFFFh";
BA_ "GenSigStartValue" SG_ 848 DateTmMinute 255;
BA_ "GenSigTimeout_RF_HUB" SG_ 848 DateTmMinute 10500;
BA_ "GenSigTimeout_IC" SG_ 848 DateTmMinute 10500;
BA_ "FlexKomSID" SG_ 848 DateTmMinute 398;
BA_ "FlexKomSigStartPos" SG_ 848 DateTmMinute 7;
BA_ "FlexKomSigLaenge" SG_ 848 DateTmMinute 24;
BA_ "FlexKomSigName" SG_ 848 DateTmMinute "Clock";
BA_ "FlexKomComment" SG_ 848 DateTmMinute "Time of day clock";
BA_ "FlexKomIsMotorola" SG_ 848 DateTmMinute 1;
BA_ "GenSigSNA" SG_ 848 DateTmMinute "FFh";
BA_ "GenSigCycleTime" SG_ 848 DateTmHour 1000;
BA_ "FlexKomSigStartValue" SG_ 848 DateTmHour "FFFFFFh";
BA_ "GenSigStartValue" SG_ 848 DateTmHour 255;
BA_ "GenSigTimeout_RF_HUB" SG_ 848 DateTmHour 10500;
BA_ "GenSigTimeout_IC" SG_ 848 DateTmHour 10500;
BA_ "FlexKomSID" SG_ 848 DateTmHour 398;
BA_ "FlexKomSigStartPos" SG_ 848 DateTmHour 7;
BA_ "FlexKomSigLaenge" SG_ 848 DateTmHour 24;
BA_ "FlexKomSigName" SG_ 848 DateTmHour "Clock";
BA_ "FlexKomComment" SG_ 848 DateTmHour "Time of day clock";
BA_ "FlexKomIsMotorola" SG_ 848 DateTmHour 1;
BA_ "GenSigSNA" SG_ 848 DateTmHour "FFh";
BA_ "GenSigCycleTime" SG_ 848 DateTmYear 1000;
BA_ "FlexKomSigStartValue" SG_ 848 DateTmYear "FFFFFFFFh";
BA_ "GenSigStartValue" SG_ 848 DateTmYear 65535;
BA_ "GenSigTimeout_RF_HUB" SG_ 848 DateTmYear 10500;
BA_ "GenSigTimeout_IC" SG_ 848 DateTmYear 10500;
BA_ "GenSigTimeout_TPM" SG_ 848 DateTmYear 15500;
BA_ "FlexKomSID" SG_ 848 DateTmYear 645;
BA_ "FlexKomSigStartPos" SG_ 848 DateTmYear 31;
BA_ "FlexKomSigLaenge" SG_ 848 DateTmYear 32;
BA_ "FlexKomSigName" SG_ 848 DateTmYear "DATE";
BA_ "FlexKomComment" SG_ 848 DateTmYear "DATE";
BA_ "FlexKomIsMotorola" SG_ 848 DateTmYear 1;
BA_ "GenSigSNA" SG_ 848 DateTmYear "FFFFh";
BA_ "GenSigCycleTime" SG_ 848 DateTmMonth 1000;
BA_ "FlexKomSigStartValue" SG_ 848 DateTmMonth "FFFFFFFFh";
BA_ "GenSigStartValue" SG_ 848 DateTmMonth 255;
BA_ "GenSigTimeout_RF_HUB" SG_ 848 DateTmMonth 10500;
BA_ "GenSigTimeout_IC" SG_ 848 DateTmMonth 10500;
BA_ "GenSigTimeout_TPM" SG_ 848 DateTmMonth 15500;
BA_ "FlexKomSID" SG_ 848 DateTmMonth 645;
BA_ "FlexKomSigStartPos" SG_ 848 DateTmMonth 31;
BA_ "FlexKomSigLaenge" SG_ 848 DateTmMonth 32;
BA_ "FlexKomSigName" SG_ 848 DateTmMonth "DATE";
BA_ "FlexKomComment" SG_ 848 DateTmMonth "DATE";
BA_ "FlexKomIsMotorola" SG_ 848 DateTmMonth 1;
BA_ "GenSigSNA" SG_ 848 DateTmMonth "FFh";
BA_ "GenSigCycleTime" SG_ 848 DateTmDay 1000;
BA_ "FlexKomSigStartValue" SG_ 848 DateTmDay "FFFFFFFFh";
BA_ "GenSigStartValue" SG_ 848 DateTmDay 255;
BA_ "GenSigTimeout_RF_HUB" SG_ 848 DateTmDay 10500;
BA_ "GenSigTimeout_IC" SG_ 848 DateTmDay 10500;
BA_ "GenSigTimeout_TPM" SG_ 848 DateTmDay 15500;
BA_ "FlexKomSID" SG_ 848 DateTmDay 645;
BA_ "FlexKomSigStartPos" SG_ 848 DateTmDay 31;
BA_ "FlexKomSigLaenge" SG_ 848 DateTmDay 32;
BA_ "FlexKomSigName" SG_ 848 DateTmDay "DATE";
BA_ "FlexKomComment" SG_ 848 DateTmDay "DATE";
BA_ "FlexKomIsMotorola" SG_ 848 DateTmDay 1;
BA_ "GenSigSNA" SG_ 848 DateTmDay "FFh";
BA_ "GenSigCycleTime" SG_ 848 DateTmFormat 1000;
BA_ "FlexKomSigStartValue" SG_ 848 DateTmFormat "07h";
BA_ "GenSigStartValue" SG_ 848 DateTmFormat 7;
BA_ "GenSigTimeout_IC" SG_ 848 DateTmFormat 10500;
BA_ "FlexKomSID" SG_ 848 DateTmFormat 971;
BA_ "FlexKomSigStartPos" SG_ 848 DateTmFormat 58;
BA_ "FlexKomSigLaenge" SG_ 848 DateTmFormat 3;
BA_ "FlexKomSigName" SG_ 848 DateTmFormat "DateTmFormat";
BA_ "FlexKomComment" SG_ 848 DateTmFormat "Date and Time Format";
BA_ "FlexKomIsMotorola" SG_ 848 DateTmFormat 1;
BA_ "GenSigSNA" SG_ 848 DateTmFormat "7h";
BA_ "GenSigSendType" SG_ 850 ECM_APPL2 1;
BA_ "FlexKomSigStartValue" SG_ 850 ECM_APPL2 "0000000000000000h";
BA_ "FlexKomSID" SG_ 850 ECM_APPL2 1110;
BA_ "FlexKomSigStartPos" SG_ 850 ECM_APPL2 7;
BA_ "FlexKomSigLaenge" SG_ 850 ECM_APPL2 64;
BA_ "FlexKomSigName" SG_ 850 ECM_APPL2 "ECM_APPL2";
BA_ "FlexKomComment" SG_ 850 ECM_APPL2 "Application";
BA_ "FlexKomIsMotorola" SG_ 850 ECM_APPL2 1;
BA_ "GenSigSNA" SG_ 850 ECM_APPL2 "0h";
BA_ "GenSigSendType" SG_ 853 TERRAIN_RQ 5;
BA_ "GenSigCycleTime" SG_ 853 TERRAIN_RQ 1000;
BA_ "FlexKomSigStartValue" SG_ 853 TERRAIN_RQ "00h";
BA_ "FlexKomSID" SG_ 853 TERRAIN_RQ 1662;
BA_ "FlexKomSigStartPos" SG_ 853 TERRAIN_RQ 1;
BA_ "FlexKomSigLaenge" SG_ 853 TERRAIN_RQ 2;
BA_ "FlexKomSigName" SG_ 853 TERRAIN_RQ "TERRAIN_RQ";
BA_ "FlexKomComment" SG_ 853 TERRAIN_RQ "Terrain setting request";
BA_ "FlexKomIsMotorola" SG_ 853 TERRAIN_RQ 1;
BA_ "GenSigSNA" SG_ 853 TERRAIN_RQ "3h";
BA_ "GenSigSendType" SG_ 853 TCASE_RQ 5;
BA_ "GenSigCycleTime" SG_ 853 TCASE_RQ 1000;
BA_ "FlexKomSigStartValue" SG_ 853 TCASE_RQ "00h";
BA_ "FlexKomSID" SG_ 853 TCASE_RQ 1663;
BA_ "FlexKomSigStartPos" SG_ 853 TCASE_RQ 3;
BA_ "FlexKomSigLaenge" SG_ 853 TCASE_RQ 2;
BA_ "FlexKomSigName" SG_ 853 TCASE_RQ "TCASE_RQ";
BA_ "FlexKomComment" SG_ 853 TCASE_RQ "Transfer case request";
BA_ "FlexKomIsMotorola" SG_ 853 TCASE_RQ 1;
BA_ "GenSigSNA" SG_ 853 TCASE_RQ "3h";
BA_ "GenSigSendType" SG_ 853 TCASE_NEUT_RQ 5;
BA_ "GenSigCycleTime" SG_ 853 TCASE_NEUT_RQ 1000;
BA_ "FlexKomSigStartValue" SG_ 853 TCASE_NEUT_RQ "03h";
BA_ "GenSigStartValue" SG_ 853 TCASE_NEUT_RQ 3;
BA_ "FlexKomSID" SG_ 853 TCASE_NEUT_RQ 1664;
BA_ "FlexKomSigStartPos" SG_ 853 TCASE_NEUT_RQ 5;
BA_ "FlexKomSigLaenge" SG_ 853 TCASE_NEUT_RQ 2;
BA_ "FlexKomSigName" SG_ 853 TCASE_NEUT_RQ "TCASE_NEUT_RQ";
BA_ "FlexKomComment" SG_ 853 TCASE_NEUT_RQ "Transfer case neutral request";
BA_ "FlexKomIsMotorola" SG_ 853 TCASE_NEUT_RQ 1;
BA_ "GenSigSNA" SG_ 853 TCASE_NEUT_RQ "3h";
BA_ "GenSigSendType" SG_ 853 Tcase2WD_Rq 5;
BA_ "GenSigCycleTime" SG_ 853 Tcase2WD_Rq 1000;
BA_ "FlexKomSigStartValue" SG_ 853 Tcase2WD_Rq "03h";
BA_ "GenSigStartValue" SG_ 853 Tcase2WD_Rq 3;
BA_ "FlexKomSID" SG_ 853 Tcase2WD_Rq 1700;
BA_ "FlexKomSigStartPos" SG_ 853 Tcase2WD_Rq 7;
BA_ "FlexKomSigLaenge" SG_ 853 Tcase2WD_Rq 2;
BA_ "FlexKomSigName" SG_ 853 Tcase2WD_Rq "Tcase2WD_Rq";
BA_ "FlexKomComment" SG_ 853 Tcase2WD_Rq "Transfer case 2 wheel drive request";
BA_ "FlexKomIsMotorola" SG_ 853 Tcase2WD_Rq 1;
BA_ "GenSigSNA" SG_ 853 Tcase2WD_Rq "3h";
BA_ "GenSigSendType" SG_ 853 TcaseAWD_Rq 5;
BA_ "GenSigCycleTime" SG_ 853 TcaseAWD_Rq 1000;
BA_ "FlexKomSigStartValue" SG_ 853 TcaseAWD_Rq "03h";
BA_ "GenSigStartValue" SG_ 853 TcaseAWD_Rq 3;
BA_ "FlexKomSID" SG_ 853 TcaseAWD_Rq 1701;
BA_ "FlexKomSigStartPos" SG_ 853 TcaseAWD_Rq 9;
BA_ "FlexKomSigLaenge" SG_ 853 TcaseAWD_Rq 2;
BA_ "FlexKomSigName" SG_ 853 TcaseAWD_Rq "TcaseAWD_Rq";
BA_ "FlexKomComment" SG_ 853 TcaseAWD_Rq "Transfer case all wheel drive request";
BA_ "FlexKomIsMotorola" SG_ 853 TcaseAWD_Rq 1;
BA_ "GenSigSNA" SG_ 853 TcaseAWD_Rq "3h";
BA_ "GenSigSendType" SG_ 853 Tcase4Lock_Rq 5;
BA_ "GenSigCycleTime" SG_ 853 Tcase4Lock_Rq 1000;
BA_ "FlexKomSigStartValue" SG_ 853 Tcase4Lock_Rq "03h";
BA_ "GenSigStartValue" SG_ 853 Tcase4Lock_Rq 3;
BA_ "FlexKomSID" SG_ 853 Tcase4Lock_Rq 1702;
BA_ "FlexKomSigStartPos" SG_ 853 Tcase4Lock_Rq 11;
BA_ "FlexKomSigLaenge" SG_ 853 Tcase4Lock_Rq 2;
BA_ "FlexKomSigName" SG_ 853 Tcase4Lock_Rq "Tcase4Lock_Rq";
BA_ "FlexKomComment" SG_ 853 Tcase4Lock_Rq "Transfer case 4 wheel lock request";
BA_ "FlexKomIsMotorola" SG_ 853 Tcase4Lock_Rq 1;
BA_ "GenSigSNA" SG_ 853 Tcase4Lock_Rq "3h";
BA_ "GenSigSendType" SG_ 853 Tcase4Low_Rq 5;
BA_ "GenSigCycleTime" SG_ 853 Tcase4Low_Rq 1000;
BA_ "FlexKomSigStartValue" SG_ 853 Tcase4Low_Rq "03h";
BA_ "GenSigStartValue" SG_ 853 Tcase4Low_Rq 3;
BA_ "FlexKomSID" SG_ 853 Tcase4Low_Rq 1703;
BA_ "FlexKomSigStartPos" SG_ 853 Tcase4Low_Rq 13;
BA_ "FlexKomSigLaenge" SG_ 853 Tcase4Low_Rq 2;
BA_ "FlexKomSigName" SG_ 853 Tcase4Low_Rq "Tcase4Low_Rq";
BA_ "FlexKomComment" SG_ 853 Tcase4Low_Rq "Transfer case 4 wheel low request";
BA_ "FlexKomIsMotorola" SG_ 853 Tcase4Low_Rq 1;
BA_ "GenSigSNA" SG_ 853 Tcase4Low_Rq "3h";
BA_ "GenSigSendType" SG_ 853 TcaseSwTyp 5;
BA_ "GenSigCycleTime" SG_ 853 TcaseSwTyp 1000;
BA_ "FlexKomSigStartValue" SG_ 853 TcaseSwTyp "03h";
BA_ "GenSigStartValue" SG_ 853 TcaseSwTyp 3;
BA_ "GenSigTimeout_DTCM" SG_ 853 TcaseSwTyp 10500;
BA_ "FlexKomSID" SG_ 853 TcaseSwTyp 1704;
BA_ "FlexKomSigStartPos" SG_ 853 TcaseSwTyp 15;
BA_ "FlexKomSigLaenge" SG_ 853 TcaseSwTyp 2;
BA_ "FlexKomSigName" SG_ 853 TcaseSwTyp "TcaseSwTyp";
BA_ "FlexKomComment" SG_ 853 TcaseSwTyp "Transfer case LIN switch type";
BA_ "FlexKomIsMotorola" SG_ 853 TcaseSwTyp 1;
BA_ "GenSigSNA" SG_ 853 TcaseSwTyp "3h";
BA_ "GenSigSendType" SG_ 853 ASBM_AUX5_On 5;
BA_ "GenSigCycleTime" SG_ 853 ASBM_AUX5_On 1000;
BA_ "FlexKomSigStartValue" SG_ 853 ASBM_AUX5_On "00h";
BA_ "FlexKomSID" SG_ 853 ASBM_AUX5_On 1961;
BA_ "FlexKomSigStartPos" SG_ 853 ASBM_AUX5_On 18;
BA_ "FlexKomSigLaenge" SG_ 853 ASBM_AUX5_On 1;
BA_ "FlexKomSigName" SG_ 853 ASBM_AUX5_On "ASBM_AUX5_On";
BA_ "FlexKomComment" SG_ 853 ASBM_AUX5_On "Aux Switch 5 Status ON";
BA_ "FlexKomIsMotorola" SG_ 853 ASBM_AUX5_On 1;
BA_ "GenSigSNA" SG_ 853 ASBM_AUX5_On "0h";
BA_ "GenSigSendType" SG_ 853 SuspSwPsd 5;
BA_ "GenSigCycleTime" SG_ 853 SuspSwPsd 1000;
BA_ "FlexKomSigStartValue" SG_ 853 SuspSwPsd "00h";
BA_ "FlexKomSID" SG_ 853 SuspSwPsd 1807;
BA_ "FlexKomSigStartPos" SG_ 853 SuspSwPsd 20;
BA_ "FlexKomSigLaenge" SG_ 853 SuspSwPsd 2;
BA_ "FlexKomSigName" SG_ 853 SuspSwPsd "SuspSwPsd";
BA_ "FlexKomComment" SG_ 853 SuspSwPsd "Suspension switch pressed";
BA_ "FlexKomIsMotorola" SG_ 853 SuspSwPsd 1;
BA_ "GenSigSNA" SG_ 853 SuspSwPsd "3h";
BA_ "GenSigSendType" SG_ 853 PARK_ASST_RQ 5;
BA_ "GenSigCycleTime" SG_ 853 PARK_ASST_RQ 1000;
BA_ "FlexKomSigStartValue" SG_ 853 PARK_ASST_RQ "00h";
BA_ "GenSigTimeout_PTS" SG_ 853 PARK_ASST_RQ 10500;
BA_ "FlexKomSID" SG_ 853 PARK_ASST_RQ 1722;
BA_ "FlexKomSigStartPos" SG_ 853 PARK_ASST_RQ 22;
BA_ "FlexKomSigLaenge" SG_ 853 PARK_ASST_RQ 2;
BA_ "FlexKomSigName" SG_ 853 PARK_ASST_RQ "PARK_ASST_RQ";
BA_ "FlexKomComment" SG_ 853 PARK_ASST_RQ "Park Assist Request";
BA_ "FlexKomIsMotorola" SG_ 853 PARK_ASST_RQ 1;
BA_ "GenSigSNA" SG_ 853 PARK_ASST_RQ "3h";
BA_ "GenSigSendType" SG_ 853 Ntrl_LED_Fail 5;
BA_ "GenSigCycleTime" SG_ 853 Ntrl_LED_Fail 1000;
BA_ "FlexKomSigStartValue" SG_ 853 Ntrl_LED_Fail "00h";
BA_ "FlexKomSID" SG_ 853 Ntrl_LED_Fail 1705;
BA_ "FlexKomSigStartPos" SG_ 853 Ntrl_LED_Fail 23;
BA_ "FlexKomSigLaenge" SG_ 853 Ntrl_LED_Fail 1;
BA_ "FlexKomSigName" SG_ 853 Ntrl_LED_Fail "Ntrl_LED_Fail";
BA_ "FlexKomComment" SG_ 853 Ntrl_LED_Fail "Neutral LED failure";
BA_ "FlexKomIsMotorola" SG_ 853 Ntrl_LED_Fail 1;
BA_ "GenSigSNA" SG_ 853 Ntrl_LED_Fail "0h";
BA_ "GenSigSendType" SG_ 853 UGDO_CHNL 5;
BA_ "GenSigCycleTime" SG_ 853 UGDO_CHNL 1000;
BA_ "FlexKomSigStartValue" SG_ 853 UGDO_CHNL "0000h";
BA_ "GenSigTimeout_IC" SG_ 853 UGDO_CHNL 10500;
BA_ "FlexKomSID" SG_ 853 UGDO_CHNL 1844;
BA_ "FlexKomSigStartPos" SG_ 853 UGDO_CHNL 31;
BA_ "FlexKomSigLaenge" SG_ 853 UGDO_CHNL 16;
BA_ "FlexKomSigName" SG_ 853 UGDO_CHNL "UGDO_Pkt";
BA_ "FlexKomComment" SG_ 853 UGDO_CHNL "Universal garage door opener packet";
BA_ "FlexKomIsMotorola" SG_ 853 UGDO_CHNL 1;
BA_ "GenSigSNA" SG_ 853 UGDO_CHNL "7h";
BA_ "GenSigSendType" SG_ 853 UGDO_STAT 5;
BA_ "GenSigCycleTime" SG_ 853 UGDO_STAT 1000;
BA_ "FlexKomSigStartValue" SG_ 853 UGDO_STAT "0000h";
BA_ "GenSigTimeout_IC" SG_ 853 UGDO_STAT 10500;
BA_ "FlexKomSID" SG_ 853 UGDO_STAT 1844;
BA_ "FlexKomSigStartPos" SG_ 853 UGDO_STAT 31;
BA_ "FlexKomSigLaenge" SG_ 853 UGDO_STAT 16;
BA_ "FlexKomSigName" SG_ 853 UGDO_STAT "UGDO_Pkt";
BA_ "FlexKomComment" SG_ 853 UGDO_STAT "Universal garage door opener packet";
BA_ "FlexKomIsMotorola" SG_ 853 UGDO_STAT 1;
BA_ "GenSigSNA" SG_ 853 UGDO_STAT "Fh";
BA_ "GenSigSendType" SG_ 853 Ch1_Stuck 5;
BA_ "GenSigCycleTime" SG_ 853 Ch1_Stuck 1000;
BA_ "FlexKomSigStartValue" SG_ 853 Ch1_Stuck "0000h";
BA_ "GenSigTimeout_IC" SG_ 853 Ch1_Stuck 10500;
BA_ "FlexKomSID" SG_ 853 Ch1_Stuck 1844;
BA_ "FlexKomSigStartPos" SG_ 853 Ch1_Stuck 31;
BA_ "FlexKomSigLaenge" SG_ 853 Ch1_Stuck 16;
BA_ "FlexKomSigName" SG_ 853 Ch1_Stuck "UGDO_Pkt";
BA_ "FlexKomComment" SG_ 853 Ch1_Stuck "Universal garage door opener packet";
BA_ "FlexKomIsMotorola" SG_ 853 Ch1_Stuck 1;
BA_ "GenSigSNA" SG_ 853 Ch1_Stuck "0h";
BA_ "GenSigSendType" SG_ 853 Ch2_Stuck 5;
BA_ "GenSigCycleTime" SG_ 853 Ch2_Stuck 1000;
BA_ "FlexKomSigStartValue" SG_ 853 Ch2_Stuck "0000h";
BA_ "GenSigTimeout_IC" SG_ 853 Ch2_Stuck 10500;
BA_ "FlexKomSID" SG_ 853 Ch2_Stuck 1844;
BA_ "FlexKomSigStartPos" SG_ 853 Ch2_Stuck 31;
BA_ "FlexKomSigLaenge" SG_ 853 Ch2_Stuck 16;
BA_ "FlexKomSigName" SG_ 853 Ch2_Stuck "UGDO_Pkt";
BA_ "FlexKomComment" SG_ 853 Ch2_Stuck "Universal garage door opener packet";
BA_ "FlexKomIsMotorola" SG_ 853 Ch2_Stuck 1;
BA_ "GenSigSNA" SG_ 853 Ch2_Stuck "0h";
BA_ "GenSigSendType" SG_ 853 Ch3_Stuck 5;
BA_ "GenSigCycleTime" SG_ 853 Ch3_Stuck 1000;
BA_ "FlexKomSigStartValue" SG_ 853 Ch3_Stuck "0000h";
BA_ "GenSigTimeout_IC" SG_ 853 Ch3_Stuck 10500;
BA_ "FlexKomSID" SG_ 853 Ch3_Stuck 1844;
BA_ "FlexKomSigStartPos" SG_ 853 Ch3_Stuck 31;
BA_ "FlexKomSigLaenge" SG_ 853 Ch3_Stuck 16;
BA_ "FlexKomSigName" SG_ 853 Ch3_Stuck "UGDO_Pkt";
BA_ "FlexKomComment" SG_ 853 Ch3_Stuck "Universal garage door opener packet";
BA_ "FlexKomIsMotorola" SG_ 853 Ch3_Stuck 1;
BA_ "GenSigSNA" SG_ 853 Ch3_Stuck "0h";
BA_ "GenSigSendType" SG_ 853 HL_Failure 5;
BA_ "GenSigCycleTime" SG_ 853 HL_Failure 1000;
BA_ "FlexKomSigStartValue" SG_ 853 HL_Failure "0000h";
BA_ "GenSigTimeout_IC" SG_ 853 HL_Failure 10500;
BA_ "FlexKomSID" SG_ 853 HL_Failure 1844;
BA_ "FlexKomSigStartPos" SG_ 853 HL_Failure 31;
BA_ "FlexKomSigLaenge" SG_ 853 HL_Failure 16;
BA_ "FlexKomSigName" SG_ 853 HL_Failure "UGDO_Pkt";
BA_ "FlexKomComment" SG_ 853 HL_Failure "Universal garage door opener packet";
BA_ "FlexKomIsMotorola" SG_ 853 HL_Failure 1;
BA_ "GenSigSNA" SG_ 853 HL_Failure "0h";
BA_ "GenSigSendType" SG_ 853 CLS_UnlkSw_Psd_D 5;
BA_ "GenSigCycleTime" SG_ 853 CLS_UnlkSw_Psd_D 1000;
BA_ "FlexKomSigStartValue" SG_ 853 CLS_UnlkSw_Psd_D "00h";
BA_ "FlexKomSID" SG_ 853 CLS_UnlkSw_Psd_D 692;
BA_ "FlexKomSigStartPos" SG_ 853 CLS_UnlkSw_Psd_D 41;
BA_ "FlexKomSigLaenge" SG_ 853 CLS_UnlkSw_Psd_D 2;
BA_ "FlexKomSigName" SG_ 853 CLS_UnlkSw_Psd_D "CLS_InsdSw_D";
BA_ "FlexKomComment" SG_ 853 CLS_UnlkSw_Psd_D "Central locking system inside switch - driver side";
BA_ "FlexKomIsMotorola" SG_ 853 CLS_UnlkSw_Psd_D 1;
BA_ "GenSigSNA" SG_ 853 CLS_UnlkSw_Psd_D "0h";
BA_ "GenSigSendType" SG_ 853 CLS_LkSw_Psd_D 5;
BA_ "GenSigCycleTime" SG_ 853 CLS_LkSw_Psd_D 1000;
BA_ "FlexKomSigStartValue" SG_ 853 CLS_LkSw_Psd_D "00h";
BA_ "FlexKomSID" SG_ 853 CLS_LkSw_Psd_D 692;
BA_ "FlexKomSigStartPos" SG_ 853 CLS_LkSw_Psd_D 41;
BA_ "FlexKomSigLaenge" SG_ 853 CLS_LkSw_Psd_D 2;
BA_ "FlexKomSigName" SG_ 853 CLS_LkSw_Psd_D "CLS_InsdSw_D";
BA_ "FlexKomComment" SG_ 853 CLS_LkSw_Psd_D "Central locking system inside switch - driver side";
BA_ "FlexKomIsMotorola" SG_ 853 CLS_LkSw_Psd_D 1;
BA_ "GenSigSNA" SG_ 853 CLS_LkSw_Psd_D "0h";
BA_ "GenSigSendType" SG_ 853 Converter_2_Mode 5;
BA_ "GenSigCycleTime" SG_ 853 Converter_2_Mode 1000;
BA_ "FlexKomSigStartValue" SG_ 853 Converter_2_Mode "00h";
BA_ "FlexKomSID" SG_ 853 Converter_2_Mode 1914;
BA_ "FlexKomSigStartPos" SG_ 853 Converter_2_Mode 45;
BA_ "FlexKomSigLaenge" SG_ 853 Converter_2_Mode 4;
BA_ "FlexKomSigName" SG_ 853 Converter_2_Mode "DC_2_DC_Pkt";
BA_ "FlexKomComment" SG_ 853 Converter_2_Mode "DC to DC #2 information packet";
BA_ "FlexKomIsMotorola" SG_ 853 Converter_2_Mode 1;
BA_ "GenSigSNA" SG_ 853 Converter_2_Mode "0h";
BA_ "GenSigSendType" SG_ 853 Converter_2_State 5;
BA_ "GenSigCycleTime" SG_ 853 Converter_2_State 1000;
BA_ "FlexKomSigStartValue" SG_ 853 Converter_2_State "00h";
BA_ "FlexKomSID" SG_ 853 Converter_2_State 1914;
BA_ "FlexKomSigStartPos" SG_ 853 Converter_2_State 45;
BA_ "FlexKomSigLaenge" SG_ 853 Converter_2_State 4;
BA_ "FlexKomSigName" SG_ 853 Converter_2_State "DC_2_DC_Pkt";
BA_ "FlexKomComment" SG_ 853 Converter_2_State "DC to DC #2 information packet";
BA_ "FlexKomIsMotorola" SG_ 853 Converter_2_State 1;
BA_ "GenSigSNA" SG_ 853 Converter_2_State "0h";
BA_ "GenSigSendType" SG_ 853 CLS_UnlkSw_Psd_P 5;
BA_ "GenSigCycleTime" SG_ 853 CLS_UnlkSw_Psd_P 1000;
BA_ "FlexKomSigStartValue" SG_ 853 CLS_UnlkSw_Psd_P "00h";
BA_ "FlexKomSID" SG_ 853 CLS_UnlkSw_Psd_P 691;
BA_ "FlexKomSigStartPos" SG_ 853 CLS_UnlkSw_Psd_P 47;
BA_ "FlexKomSigLaenge" SG_ 853 CLS_UnlkSw_Psd_P 2;
BA_ "FlexKomSigName" SG_ 853 CLS_UnlkSw_Psd_P "CLS_InsdSw_P";
BA_ "FlexKomComment" SG_ 853 CLS_UnlkSw_Psd_P "Central locking system inside switch - passenger s";
BA_ "FlexKomIsMotorola" SG_ 853 CLS_UnlkSw_Psd_P 1;
BA_ "GenSigSNA" SG_ 853 CLS_UnlkSw_Psd_P "0h";
BA_ "GenSigSendType" SG_ 853 CLS_LkSw_Psd_P 5;
BA_ "GenSigCycleTime" SG_ 853 CLS_LkSw_Psd_P 1000;
BA_ "FlexKomSigStartValue" SG_ 853 CLS_LkSw_Psd_P "00h";
BA_ "FlexKomSID" SG_ 853 CLS_LkSw_Psd_P 691;
BA_ "FlexKomSigStartPos" SG_ 853 CLS_LkSw_Psd_P 47;
BA_ "FlexKomSigLaenge" SG_ 853 CLS_LkSw_Psd_P 2;
BA_ "FlexKomSigName" SG_ 853 CLS_LkSw_Psd_P "CLS_InsdSw_P";
BA_ "FlexKomComment" SG_ 853 CLS_LkSw_Psd_P "Central locking system inside switch - passenger s";
BA_ "FlexKomIsMotorola" SG_ 853 CLS_LkSw_Psd_P 1;
BA_ "GenSigSNA" SG_ 853 CLS_LkSw_Psd_P "0h";
BA_ "GenSigSendType" SG_ 853 FT_PARK_ASST_RQ 5;
BA_ "GenSigCycleTime" SG_ 853 FT_PARK_ASST_RQ 1000;
BA_ "FlexKomSigStartValue" SG_ 853 FT_PARK_ASST_RQ "00h";
BA_ "GenSigTimeout_PTS" SG_ 853 FT_PARK_ASST_RQ 10500;
BA_ "FlexKomSID" SG_ 853 FT_PARK_ASST_RQ 1955;
BA_ "FlexKomSigStartPos" SG_ 853 FT_PARK_ASST_RQ 49;
BA_ "FlexKomSigLaenge" SG_ 853 FT_PARK_ASST_RQ 2;
BA_ "FlexKomSigName" SG_ 853 FT_PARK_ASST_RQ "FT_PARK_ASST_RQ";
BA_ "FlexKomComment" SG_ 853 FT_PARK_ASST_RQ "Front park assist request";
BA_ "FlexKomIsMotorola" SG_ 853 FT_PARK_ASST_RQ 1;
BA_ "GenSigSNA" SG_ 853 FT_PARK_ASST_RQ "3h";
BA_ "GenSigSendType" SG_ 853 SpSt_Pad1 5;
BA_ "GenSigCycleTime" SG_ 853 SpSt_Pad1 1000;
BA_ "FlexKomSigStartValue" SG_ 853 SpSt_Pad1 "00h";
BA_ "FlexKomSID" SG_ 853 SpSt_Pad1 1959;
BA_ "FlexKomSigStartPos" SG_ 853 SpSt_Pad1 52;
BA_ "FlexKomSigLaenge" SG_ 853 SpSt_Pad1 3;
BA_ "FlexKomSigName" SG_ 853 SpSt_Pad1 "SpSt_Pad1";
BA_ "FlexKomComment" SG_ 853 SpSt_Pad1 "Stop / start switch - pad 1";
BA_ "FlexKomIsMotorola" SG_ 853 SpSt_Pad1 1;
BA_ "GenSigSNA" SG_ 853 SpSt_Pad1 "7h";
BA_ "GenSigSendType" SG_ 853 SpSt_Pad2 5;
BA_ "GenSigCycleTime" SG_ 853 SpSt_Pad2 1000;
BA_ "FlexKomSigStartValue" SG_ 853 SpSt_Pad2 "00h";
BA_ "FlexKomSID" SG_ 853 SpSt_Pad2 1960;
BA_ "FlexKomSigStartPos" SG_ 853 SpSt_Pad2 55;
BA_ "FlexKomSigLaenge" SG_ 853 SpSt_Pad2 3;
BA_ "FlexKomSigName" SG_ 853 SpSt_Pad2 "SpSt_Pad2";
BA_ "FlexKomComment" SG_ 853 SpSt_Pad2 "Stop / start switch - pad 2";
BA_ "FlexKomIsMotorola" SG_ 853 SpSt_Pad2 1;
BA_ "GenSigSNA" SG_ 853 SpSt_Pad2 "7h";
BA_ "GenSigCycleTime" SG_ 853 IBS_IBATT_QUIESCENT 1000;
BA_ "FlexKomSigStartValue" SG_ 853 IBS_IBATT_QUIESCENT "FFh";
BA_ "GenSigStartValue" SG_ 853 IBS_IBATT_QUIESCENT 255;
BA_ "FlexKomSID" SG_ 853 IBS_IBATT_QUIESCENT 1854;
BA_ "FlexKomSigStartPos" SG_ 853 IBS_IBATT_QUIESCENT 63;
BA_ "FlexKomSigLaenge" SG_ 853 IBS_IBATT_QUIESCENT 8;
BA_ "FlexKomSigName" SG_ 853 IBS_IBATT_QUIESCENT "IBS_IBATT_QUIESCENT";
BA_ "FlexKomComment" SG_ 853 IBS_IBATT_QUIESCENT "Battery quiescent current";
BA_ "FlexKomIsMotorola" SG_ 853 IBS_IBATT_QUIESCENT 1;
BA_ "GenSigSNA" SG_ 853 IBS_IBATT_QUIESCENT "FFh";
BA_ "GenSigCycleTime" SG_ 856 CMP_DIR 1000;
BA_ "FlexKomSigStartValue" SG_ 856 CMP_DIR "0Fh";
BA_ "GenSigStartValue" SG_ 856 CMP_DIR 15;
BA_ "GenSigTimeout_IC" SG_ 856 CMP_DIR 10500;
BA_ "FlexKomSID" SG_ 856 CMP_DIR 817;
BA_ "FlexKomSigStartPos" SG_ 856 CMP_DIR 3;
BA_ "FlexKomSigLaenge" SG_ 856 CMP_DIR 4;
BA_ "FlexKomSigName" SG_ 856 CMP_DIR "CMP_DIR";
BA_ "FlexKomComment" SG_ 856 CMP_DIR "Compass direction (WK/LX)";
BA_ "FlexKomIsMotorola" SG_ 856 CMP_DIR 1;
BA_ "GenSigSNA" SG_ 856 CMP_DIR "Fh";
BA_ "GenSigCycleTime" SG_ 856 VAR_VAL 1000;
BA_ "FlexKomSigStartValue" SG_ 856 VAR_VAL "0Fh";
BA_ "GenSigStartValue" SG_ 856 VAR_VAL 15;
BA_ "GenSigTimeout_IC" SG_ 856 VAR_VAL 10500;
BA_ "FlexKomSID" SG_ 856 VAR_VAL 811;
BA_ "FlexKomSigStartPos" SG_ 856 VAR_VAL 7;
BA_ "FlexKomSigLaenge" SG_ 856 VAR_VAL 4;
BA_ "FlexKomSigName" SG_ 856 VAR_VAL "VAR_VAL";
BA_ "FlexKomComment" SG_ 856 VAR_VAL "RCM Variance Value";
BA_ "FlexKomIsMotorola" SG_ 856 VAR_VAL 1;
BA_ "GenSigSNA" SG_ 856 VAR_VAL "Fh";
BA_ "GenSigCycleTime" SG_ 856 CMP_DIR_RAW 1000;
BA_ "FlexKomSigStartValue" SG_ 856 CMP_DIR_RAW "0000h";
BA_ "GenSigTimeout_IC" SG_ 856 CMP_DIR_RAW 10500;
BA_ "FlexKomSID" SG_ 856 CMP_DIR_RAW 818;
BA_ "FlexKomSigStartPos" SG_ 856 CMP_DIR_RAW 15;
BA_ "FlexKomSigLaenge" SG_ 856 CMP_DIR_RAW 16;
BA_ "FlexKomSigName" SG_ 856 CMP_DIR_RAW "CMP_DIR_RAW";
BA_ "FlexKomComment" SG_ 856 CMP_DIR_RAW "Compass direction raw";
BA_ "FlexKomIsMotorola" SG_ 856 CMP_DIR_RAW 1;
BA_ "GenSigSNA" SG_ 856 CMP_DIR_RAW "0h";
BA_ "GenSigCycleTime" SG_ 856 CAL_REQD 1000;
BA_ "FlexKomSigStartValue" SG_ 856 CAL_REQD "00h";
BA_ "GenSigTimeout_IC" SG_ 856 CAL_REQD 10500;
BA_ "FlexKomSID" SG_ 856 CAL_REQD 819;
BA_ "FlexKomSigStartPos" SG_ 856 CAL_REQD 10;
BA_ "FlexKomSigLaenge" SG_ 856 CAL_REQD 1;
BA_ "FlexKomSigName" SG_ 856 CAL_REQD "CAL_REQD";
BA_ "FlexKomComment" SG_ 856 CAL_REQD "Calibration needed";
BA_ "FlexKomIsMotorola" SG_ 856 CAL_REQD 1;
BA_ "GenSigSNA" SG_ 856 CAL_REQD "0h";
BA_ "GenSigCycleTime" SG_ 856 IN_CAL_MD 1000;
BA_ "FlexKomSigStartValue" SG_ 856 IN_CAL_MD "00h";
BA_ "GenSigTimeout_IC" SG_ 856 IN_CAL_MD 10500;
BA_ "FlexKomSID" SG_ 856 IN_CAL_MD 814;
BA_ "FlexKomSigStartPos" SG_ 856 IN_CAL_MD 11;
BA_ "FlexKomSigLaenge" SG_ 856 IN_CAL_MD 1;
BA_ "FlexKomSigName" SG_ 856 IN_CAL_MD "IN_CAL_MD";
BA_ "FlexKomComment" SG_ 856 IN_CAL_MD "In Calibration Mode";
BA_ "FlexKomIsMotorola" SG_ 856 IN_CAL_MD 1;
BA_ "GenSigSNA" SG_ 856 IN_CAL_MD "0h";
BA_ "GenSigSendType" SG_ 860 DIST_TO_TURN 5;
BA_ "GenSigCycleTime" SG_ 860 DIST_TO_TURN 1000;
BA_ "FlexKomSigStartValue" SG_ 860 DIST_TO_TURN "00000000h";
BA_ "GenSigTimeout_IC" SG_ 860 DIST_TO_TURN 10500;
BA_ "FlexKomSID" SG_ 860 DIST_TO_TURN 986;
BA_ "FlexKomSigStartPos" SG_ 860 DIST_TO_TURN 7;
BA_ "FlexKomSigLaenge" SG_ 860 DIST_TO_TURN 32;
BA_ "FlexKomSigName" SG_ 860 DIST_TO_TURN "TURN_INFO";
BA_ "FlexKomComment" SG_ 860 DIST_TO_TURN "Navigation turn information packet";
BA_ "FlexKomIsMotorola" SG_ 860 DIST_TO_TURN 1;
BA_ "GenSigSNA" SG_ 860 DIST_TO_TURN "FFFFh";
BA_ "GenSigSendType" SG_ 860 UNITS 5;
BA_ "GenSigCycleTime" SG_ 860 UNITS 1000;
BA_ "FlexKomSigStartValue" SG_ 860 UNITS "00000000h";
BA_ "GenSigTimeout_IC" SG_ 860 UNITS 10500;
BA_ "FlexKomSID" SG_ 860 UNITS 986;
BA_ "FlexKomSigStartPos" SG_ 860 UNITS 7;
BA_ "FlexKomSigLaenge" SG_ 860 UNITS 32;
BA_ "FlexKomSigName" SG_ 860 UNITS "TURN_INFO";
BA_ "FlexKomComment" SG_ 860 UNITS "Navigation turn information packet";
BA_ "FlexKomIsMotorola" SG_ 860 UNITS 1;
BA_ "GenSigSNA" SG_ 860 UNITS "7h";
BA_ "GenSigSendType" SG_ 860 T_BY_T_ON 5;
BA_ "GenSigCycleTime" SG_ 860 T_BY_T_ON 1000;
BA_ "FlexKomSigStartValue" SG_ 860 T_BY_T_ON "00000000h";
BA_ "GenSigTimeout_IC" SG_ 860 T_BY_T_ON 10500;
BA_ "FlexKomSID" SG_ 860 T_BY_T_ON 986;
BA_ "FlexKomSigStartPos" SG_ 860 T_BY_T_ON 7;
BA_ "FlexKomSigLaenge" SG_ 860 T_BY_T_ON 32;
BA_ "FlexKomSigName" SG_ 860 T_BY_T_ON "TURN_INFO";
BA_ "FlexKomComment" SG_ 860 T_BY_T_ON "Navigation turn information packet";
BA_ "FlexKomIsMotorola" SG_ 860 T_BY_T_ON 1;
BA_ "GenSigSNA" SG_ 860 T_BY_T_ON "0h";
BA_ "GenSigSendType" SG_ 860 TURN_COMP 5;
BA_ "GenSigCycleTime" SG_ 860 TURN_COMP 1000;
BA_ "FlexKomSigStartValue" SG_ 860 TURN_COMP "00000000h";
BA_ "GenSigTimeout_IC" SG_ 860 TURN_COMP 10500;
BA_ "FlexKomSID" SG_ 860 TURN_COMP 986;
BA_ "FlexKomSigStartPos" SG_ 860 TURN_COMP 7;
BA_ "FlexKomSigLaenge" SG_ 860 TURN_COMP 32;
BA_ "FlexKomSigName" SG_ 860 TURN_COMP "TURN_INFO";
BA_ "FlexKomComment" SG_ 860 TURN_COMP "Navigation turn information packet";
BA_ "FlexKomIsMotorola" SG_ 860 TURN_COMP 1;
BA_ "GenSigSNA" SG_ 860 TURN_COMP "0h";
BA_ "GenSigSendType" SG_ 860 NAV_ARROW 5;
BA_ "GenSigCycleTime" SG_ 860 NAV_ARROW 1000;
BA_ "FlexKomSigStartValue" SG_ 860 NAV_ARROW "00000000h";
BA_ "GenSigTimeout_IC" SG_ 860 NAV_ARROW 10500;
BA_ "FlexKomSID" SG_ 860 NAV_ARROW 986;
BA_ "FlexKomSigStartPos" SG_ 860 NAV_ARROW 7;
BA_ "FlexKomSigLaenge" SG_ 860 NAV_ARROW 32;
BA_ "FlexKomSigName" SG_ 860 NAV_ARROW "TURN_INFO";
BA_ "FlexKomComment" SG_ 860 NAV_ARROW "Navigation turn information packet";
BA_ "FlexKomIsMotorola" SG_ 860 NAV_ARROW 1;
BA_ "GenSigSNA" SG_ 860 NAV_ARROW "0h";
BA_ "GenSigSendType" SG_ 860 NAVPrsnt 5;
BA_ "GenSigCycleTime" SG_ 860 NAVPrsnt 1000;
BA_ "FlexKomSigStartValue" SG_ 860 NAVPrsnt "00000000h";
BA_ "FlexKomSID" SG_ 860 NAVPrsnt 986;
BA_ "FlexKomSigStartPos" SG_ 860 NAVPrsnt 7;
BA_ "FlexKomSigLaenge" SG_ 860 NAVPrsnt 32;
BA_ "FlexKomSigName" SG_ 860 NAVPrsnt "TURN_INFO";
BA_ "FlexKomComment" SG_ 860 NAVPrsnt "Navigation turn information packet";
BA_ "FlexKomIsMotorola" SG_ 860 NAVPrsnt 1;
BA_ "GenSigSNA" SG_ 860 NAVPrsnt "0h";
BA_ "GenSigSendType" SG_ 860 HU_CMP 5;
BA_ "GenSigCycleTime" SG_ 860 HU_CMP 1000;
BA_ "FlexKomSigStartValue" SG_ 860 HU_CMP "0Fh";
BA_ "GenSigStartValue" SG_ 860 HU_CMP 15;
BA_ "GenSigTimeout_IC" SG_ 860 HU_CMP 10500;
BA_ "FlexKomSID" SG_ 860 HU_CMP 987;
BA_ "FlexKomSigStartPos" SG_ 860 HU_CMP 35;
BA_ "FlexKomSigLaenge" SG_ 860 HU_CMP 4;
BA_ "FlexKomSigName" SG_ 860 HU_CMP "HU_CMP";
BA_ "FlexKomComment" SG_ 860 HU_CMP "Radio compass direction";
BA_ "FlexKomIsMotorola" SG_ 860 HU_CMP 1;
BA_ "GenSigSNA" SG_ 860 HU_CMP "Fh";
BA_ "GenSigSendType" SG_ 860 RADIO_W_GYRO 5;
BA_ "GenSigCycleTime" SG_ 860 RADIO_W_GYRO 1000;
BA_ "FlexKomSigStartValue" SG_ 860 RADIO_W_GYRO "00h";
BA_ "GenSigTimeout_IC" SG_ 860 RADIO_W_GYRO 10500;
BA_ "FlexKomSID" SG_ 860 RADIO_W_GYRO 1465;
BA_ "FlexKomSigStartPos" SG_ 860 RADIO_W_GYRO 36;
BA_ "FlexKomSigLaenge" SG_ 860 RADIO_W_GYRO 1;
BA_ "FlexKomSigName" SG_ 860 RADIO_W_GYRO "RADIO_W_GYRO";
BA_ "FlexKomComment" SG_ 860 RADIO_W_GYRO "Radio with gyro (1=present)";
BA_ "FlexKomIsMotorola" SG_ 860 RADIO_W_GYRO 1;
BA_ "GenSigSNA" SG_ 860 RADIO_W_GYRO "0h";
BA_ "GenSigSendType" SG_ 860 HU_CMP_RAW 5;
BA_ "GenSigCycleTime" SG_ 860 HU_CMP_RAW 1000;
BA_ "FlexKomSigStartValue" SG_ 860 HU_CMP_RAW "FFh";
BA_ "GenSigStartValue" SG_ 860 HU_CMP_RAW 255;
BA_ "GenSigTimeout_IC" SG_ 860 HU_CMP_RAW 10500;
BA_ "FlexKomSID" SG_ 860 HU_CMP_RAW 988;
BA_ "FlexKomSigStartPos" SG_ 860 HU_CMP_RAW 47;
BA_ "FlexKomSigLaenge" SG_ 860 HU_CMP_RAW 8;
BA_ "FlexKomSigName" SG_ 860 HU_CMP_RAW "HU_CMP_RAW";
BA_ "FlexKomComment" SG_ 860 HU_CMP_RAW "Compass direction raw";
BA_ "FlexKomIsMotorola" SG_ 860 HU_CMP_RAW 1;
BA_ "GenSigSNA" SG_ 860 HU_CMP_RAW "FFh";
BA_ "GenSigCycleTime" SG_ 863 PSI_Gr1_RPM 100;
BA_ "FlexKomSigStartValue" SG_ 863 PSI_Gr1_RPM "00h";
BA_ "GenSigTimeout_ETM" SG_ 863 PSI_Gr1_RPM 1050;
BA_ "FlexKomSID" SG_ 863 PSI_Gr1_RPM 2057;
BA_ "FlexKomSigStartPos" SG_ 863 PSI_Gr1_RPM 4;
BA_ "FlexKomSigLaenge" SG_ 863 PSI_Gr1_RPM 5;
BA_ "FlexKomSigName" SG_ 863 PSI_Gr1_RPM "PSI_Gr1_RPM";
BA_ "FlexKomComment" SG_ 863 PSI_Gr1_RPM "Actual rpm set point for performance shift indicat";
BA_ "FlexKomIsMotorola" SG_ 863 PSI_Gr1_RPM 1;
BA_ "GenSigSNA" SG_ 863 PSI_Gr1_RPM "1Fh";
BA_ "GenSigCycleTime" SG_ 863 PSI_EnableSts 100;
BA_ "FlexKomSigStartValue" SG_ 863 PSI_EnableSts "00h";
BA_ "FlexKomSID" SG_ 863 PSI_EnableSts 2096;
BA_ "FlexKomSigStartPos" SG_ 863 PSI_EnableSts 5;
BA_ "FlexKomSigLaenge" SG_ 863 PSI_EnableSts 1;
BA_ "FlexKomSigName" SG_ 863 PSI_EnableSts "PSI_EnableSts";
BA_ "FlexKomComment" SG_ 863 PSI_EnableSts "Performance shift indication enabled status; enabl";
BA_ "FlexKomIsMotorola" SG_ 863 PSI_EnableSts 1;
BA_ "GenSigSNA" SG_ 863 PSI_EnableSts "0h";
BA_ "GenSigCycleTime" SG_ 863 PSI_Gr2_RPM 100;
BA_ "FlexKomSigStartValue" SG_ 863 PSI_Gr2_RPM "00h";
BA_ "GenSigTimeout_ETM" SG_ 863 PSI_Gr2_RPM 1050;
BA_ "FlexKomSID" SG_ 863 PSI_Gr2_RPM 2058;
BA_ "FlexKomSigStartPos" SG_ 863 PSI_Gr2_RPM 12;
BA_ "FlexKomSigLaenge" SG_ 863 PSI_Gr2_RPM 5;
BA_ "FlexKomSigName" SG_ 863 PSI_Gr2_RPM "PSI_Gr2_RPM";
BA_ "FlexKomComment" SG_ 863 PSI_Gr2_RPM "Actual rpm set point for performance shift indicat";
BA_ "FlexKomIsMotorola" SG_ 863 PSI_Gr2_RPM 1;
BA_ "GenSigSNA" SG_ 863 PSI_Gr2_RPM "1Fh";
BA_ "GenSigCycleTime" SG_ 863 PSI_Gr3_RPM 100;
BA_ "FlexKomSigStartValue" SG_ 863 PSI_Gr3_RPM "00h";
BA_ "GenSigTimeout_ETM" SG_ 863 PSI_Gr3_RPM 1050;
BA_ "FlexKomSID" SG_ 863 PSI_Gr3_RPM 2059;
BA_ "FlexKomSigStartPos" SG_ 863 PSI_Gr3_RPM 20;
BA_ "FlexKomSigLaenge" SG_ 863 PSI_Gr3_RPM 5;
BA_ "FlexKomSigName" SG_ 863 PSI_Gr3_RPM "PSI_Gr3_RPM";
BA_ "FlexKomComment" SG_ 863 PSI_Gr3_RPM "Actual rpm set point for performance shift indicat";
BA_ "FlexKomIsMotorola" SG_ 863 PSI_Gr3_RPM 1;
BA_ "GenSigSNA" SG_ 863 PSI_Gr3_RPM "1Fh";
BA_ "GenSigCycleTime" SG_ 863 PSI_Gr4_RPM 100;
BA_ "FlexKomSigStartValue" SG_ 863 PSI_Gr4_RPM "00h";
BA_ "GenSigTimeout_ETM" SG_ 863 PSI_Gr4_RPM 1050;
BA_ "FlexKomSID" SG_ 863 PSI_Gr4_RPM 2060;
BA_ "FlexKomSigStartPos" SG_ 863 PSI_Gr4_RPM 28;
BA_ "FlexKomSigLaenge" SG_ 863 PSI_Gr4_RPM 5;
BA_ "FlexKomSigName" SG_ 863 PSI_Gr4_RPM "PSI_Gr4_RPM";
BA_ "FlexKomComment" SG_ 863 PSI_Gr4_RPM "Actual rpm set point for performance shift indicat";
BA_ "FlexKomIsMotorola" SG_ 863 PSI_Gr4_RPM 1;
BA_ "GenSigSNA" SG_ 863 PSI_Gr4_RPM "1Fh";
BA_ "GenSigCycleTime" SG_ 863 PSI_Gr5_RPM 100;
BA_ "FlexKomSigStartValue" SG_ 863 PSI_Gr5_RPM "00h";
BA_ "GenSigTimeout_ETM" SG_ 863 PSI_Gr5_RPM 1050;
BA_ "FlexKomSID" SG_ 863 PSI_Gr5_RPM 2061;
BA_ "FlexKomSigStartPos" SG_ 863 PSI_Gr5_RPM 36;
BA_ "FlexKomSigLaenge" SG_ 863 PSI_Gr5_RPM 5;
BA_ "FlexKomSigName" SG_ 863 PSI_Gr5_RPM "PSI_Gr5_RPM";
BA_ "FlexKomComment" SG_ 863 PSI_Gr5_RPM "Actual rpm set point for performance shift indicat";
BA_ "FlexKomIsMotorola" SG_ 863 PSI_Gr5_RPM 1;
BA_ "GenSigSNA" SG_ 863 PSI_Gr5_RPM "1Fh";
BA_ "GenSigCycleTime" SG_ 863 ECM_MSG_RQ 100;
BA_ "FlexKomSigStartValue" SG_ 863 ECM_MSG_RQ "00h";
BA_ "GenSigTimeout_CBC" SG_ 863 ECM_MSG_RQ 1050;
BA_ "FlexKomSID" SG_ 863 ECM_MSG_RQ 2079;
BA_ "FlexKomSigStartPos" SG_ 863 ECM_MSG_RQ 47;
BA_ "FlexKomSigLaenge" SG_ 863 ECM_MSG_RQ 5;
BA_ "FlexKomSigName" SG_ 863 ECM_MSG_RQ "ECM_MSG_RQ";
BA_ "FlexKomComment" SG_ 863 ECM_MSG_RQ "ECM Driver Instruction Messages";
BA_ "FlexKomIsMotorola" SG_ 863 ECM_MSG_RQ 1;
BA_ "GenSigSNA" SG_ 863 ECM_MSG_RQ "1Fh";
BA_ "GenSigCycleTime" SG_ 863 RevOilLifeRst 100;
BA_ "FlexKomSigStartValue" SG_ 863 RevOilLifeRst "FFFFh";
BA_ "GenSigStartValue" SG_ 863 RevOilLifeRst 65535;
BA_ "GenSigTimeout_CBC" SG_ 863 RevOilLifeRst 1050;
BA_ "FlexKomSID" SG_ 863 RevOilLifeRst 2109;
BA_ "FlexKomSigStartPos" SG_ 863 RevOilLifeRst 55;
BA_ "FlexKomSigLaenge" SG_ 863 RevOilLifeRst 16;
BA_ "FlexKomSigName" SG_ 863 RevOilLifeRst "RevOilLifeRst";
BA_ "FlexKomComment" SG_ 863 RevOilLifeRst "Engine revolutions since last oil life reset";
BA_ "FlexKomIsMotorola" SG_ 863 RevOilLifeRst 1;
BA_ "GenSigSNA" SG_ 863 RevOilLifeRst "FFFFh";
BA_ "GenSigSendType" SG_ 864 ECM_APPL1 1;
BA_ "FlexKomSigStartValue" SG_ 864 ECM_APPL1 "0000000000000000h";
BA_ "FlexKomSID" SG_ 864 ECM_APPL1 780;
BA_ "FlexKomSigStartPos" SG_ 864 ECM_APPL1 7;
BA_ "FlexKomSigLaenge" SG_ 864 ECM_APPL1 64;
BA_ "FlexKomSigName" SG_ 864 ECM_APPL1 "ECM_APPL1";
BA_ "FlexKomComment" SG_ 864 ECM_APPL1 "Application";
BA_ "FlexKomIsMotorola" SG_ 864 ECM_APPL1 1;
BA_ "GenSigSNA" SG_ 864 ECM_APPL1 "0h";
BA_ "GenSigSendType" SG_ 865 TCM_HS1 1;
BA_ "FlexKomSigStartValue" SG_ 865 TCM_HS1 "0000000000000000h";
BA_ "FlexKomSID" SG_ 865 TCM_HS1 1147;
BA_ "FlexKomSigStartPos" SG_ 865 TCM_HS1 7;
BA_ "FlexKomSigLaenge" SG_ 865 TCM_HS1 64;
BA_ "FlexKomSigName" SG_ 865 TCM_HS1 "TCM_HS1";
BA_ "FlexKomComment" SG_ 865 TCM_HS1 "Manual control at test bench";
BA_ "FlexKomIsMotorola" SG_ 865 TCM_HS1 1;
BA_ "GenSigSNA" SG_ 865 TCM_HS1 "0h";
BA_ "GenSigSendType" SG_ 866 TCM_HS2 1;
BA_ "FlexKomSigStartValue" SG_ 866 TCM_HS2 "0000000000000000h";
BA_ "FlexKomSID" SG_ 866 TCM_HS2 1148;
BA_ "FlexKomSigStartPos" SG_ 866 TCM_HS2 7;
BA_ "FlexKomSigLaenge" SG_ 866 TCM_HS2 64;
BA_ "FlexKomSigName" SG_ 866 TCM_HS2 "TCM_HS2";
BA_ "FlexKomComment" SG_ 866 TCM_HS2 "Manual control at test bench";
BA_ "FlexKomIsMotorola" SG_ 866 TCM_HS2 1;
BA_ "GenSigSNA" SG_ 866 TCM_HS2 "0h";
BA_ "GenSigSendType" SG_ 867 TCM_HS3 1;
BA_ "FlexKomSigStartValue" SG_ 867 TCM_HS3 "0000000000000000h";
BA_ "FlexKomSID" SG_ 867 TCM_HS3 1149;
BA_ "FlexKomSigStartPos" SG_ 867 TCM_HS3 7;
BA_ "FlexKomSigLaenge" SG_ 867 TCM_HS3 64;
BA_ "FlexKomSigName" SG_ 867 TCM_HS3 "TCM_HS3";
BA_ "FlexKomComment" SG_ 867 TCM_HS3 "Manual control at test bench";
BA_ "FlexKomIsMotorola" SG_ 867 TCM_HS3 1;
BA_ "GenSigSNA" SG_ 867 TCM_HS3 "0h";
BA_ "GenSigSendType" SG_ 868 MESS_TPM1 1;
BA_ "FlexKomSigStartValue" SG_ 868 MESS_TPM1 "0000000000000000h";
BA_ "FlexKomSID" SG_ 868 MESS_TPM1 867;
BA_ "FlexKomSigStartPos" SG_ 868 MESS_TPM1 7;
BA_ "FlexKomSigLaenge" SG_ 868 MESS_TPM1 64;
BA_ "FlexKomSigName" SG_ 868 MESS_TPM1 "MESS_TPM1";
BA_ "FlexKomComment" SG_ 868 MESS_TPM1 "Measurement data";
BA_ "FlexKomIsMotorola" SG_ 868 MESS_TPM1 1;
BA_ "GenSigSNA" SG_ 868 MESS_TPM1 "0h";
BA_ "GenSigSendType" SG_ 872 TCM_HSA 1;
BA_ "FlexKomSigStartValue" SG_ 872 TCM_HSA "0000000000000000h";
BA_ "FlexKomSID" SG_ 872 TCM_HSA 799;
BA_ "FlexKomSigStartPos" SG_ 872 TCM_HSA 7;
BA_ "FlexKomSigLaenge" SG_ 872 TCM_HSA 64;
BA_ "FlexKomSigName" SG_ 872 TCM_HSA "TCM_HSA";
BA_ "FlexKomComment" SG_ 872 TCM_HSA "Manual control at test bench";
BA_ "FlexKomIsMotorola" SG_ 872 TCM_HSA 1;
BA_ "GenSigSNA" SG_ 872 TCM_HSA "0h";
BA_ "GenSigSendType" SG_ 874 ADC_Stat 5;
BA_ "GenSigCycleTime" SG_ 874 ADC_Stat 1000;
BA_ "FlexKomSigStartValue" SG_ 874 ADC_Stat "00h";
BA_ "GenSigTimeout_CBC" SG_ 874 ADC_Stat 10500;
BA_ "GenSigTimeout_IC" SG_ 874 ADC_Stat 10500;
BA_ "FlexKomSID" SG_ 874 ADC_Stat 1151;
BA_ "FlexKomSigStartPos" SG_ 874 ADC_Stat 1;
BA_ "FlexKomSigLaenge" SG_ 874 ADC_Stat 2;
BA_ "FlexKomSigName" SG_ 874 ADC_Stat "ADC_Stat";
BA_ "FlexKomComment" SG_ 874 ADC_Stat "Active damping control status";
BA_ "FlexKomIsMotorola" SG_ 874 ADC_Stat 1;
BA_ "GenSigSNA" SG_ 874 ADC_Stat "3h";
BA_ "GenSigSendType" SG_ 874 ADS_MODE_CFG_Stat 5;
BA_ "GenSigCycleTime" SG_ 874 ADS_MODE_CFG_Stat 1000;
BA_ "FlexKomSigStartValue" SG_ 874 ADS_MODE_CFG_Stat "00h";
BA_ "GenSigTimeout_CBC" SG_ 874 ADS_MODE_CFG_Stat 10500;
BA_ "GenSigTimeout_IC" SG_ 874 ADS_MODE_CFG_Stat 10500;
BA_ "FlexKomSID" SG_ 874 ADS_MODE_CFG_Stat 2112;
BA_ "FlexKomSigStartPos" SG_ 874 ADS_MODE_CFG_Stat 3;
BA_ "FlexKomSigLaenge" SG_ 874 ADS_MODE_CFG_Stat 2;
BA_ "FlexKomSigName" SG_ 874 ADS_MODE_CFG_Stat "ADS_MODE_CFG_Stat";
BA_ "FlexKomComment" SG_ 874 ADS_MODE_CFG_Stat "Default setting - ADS mode";
BA_ "FlexKomIsMotorola" SG_ 874 ADS_MODE_CFG_Stat 1;
BA_ "GenSigSNA" SG_ 874 ADS_MODE_CFG_Stat "3h";
BA_ "GenSigSendType" SG_ 874 ADS_YelLmp 5;
BA_ "GenSigCycleTime" SG_ 874 ADS_YelLmp 1000;
BA_ "FlexKomSigStartValue" SG_ 874 ADS_YelLmp "00h";
BA_ "GenSigTimeout_IC" SG_ 874 ADS_YelLmp 10500;
BA_ "FlexKomSID" SG_ 874 ADS_YelLmp 1152;
BA_ "FlexKomSigStartPos" SG_ 874 ADS_YelLmp 15;
BA_ "FlexKomSigLaenge" SG_ 874 ADS_YelLmp 8;
BA_ "FlexKomSigName" SG_ 874 ADS_YelLmp "ADS_FltMds";
BA_ "FlexKomComment" SG_ 874 ADS_YelLmp "ADS fault modes";
BA_ "FlexKomIsMotorola" SG_ 874 ADS_YelLmp 1;
BA_ "GenSigSNA" SG_ 874 ADS_YelLmp "0h";
BA_ "GenSigSendType" SG_ 874 ADS_RedLmp 5;
BA_ "GenSigCycleTime" SG_ 874 ADS_RedLmp 1000;
BA_ "FlexKomSigStartValue" SG_ 874 ADS_RedLmp "00h";
BA_ "GenSigTimeout_IC" SG_ 874 ADS_RedLmp 10500;
BA_ "FlexKomSID" SG_ 874 ADS_RedLmp 1152;
BA_ "FlexKomSigStartPos" SG_ 874 ADS_RedLmp 15;
BA_ "FlexKomSigLaenge" SG_ 874 ADS_RedLmp 8;
BA_ "FlexKomSigName" SG_ 874 ADS_RedLmp "ADS_FltMds";
BA_ "FlexKomComment" SG_ 874 ADS_RedLmp "ADS fault modes";
BA_ "FlexKomIsMotorola" SG_ 874 ADS_RedLmp 1;
BA_ "GenSigSNA" SG_ 874 ADS_RedLmp "0h";
BA_ "GenSigSendType" SG_ 874 ADS_SrvSys 5;
BA_ "GenSigCycleTime" SG_ 874 ADS_SrvSys 1000;
BA_ "FlexKomSigStartValue" SG_ 874 ADS_SrvSys "00h";
BA_ "GenSigTimeout_IC" SG_ 874 ADS_SrvSys 10500;
BA_ "FlexKomSID" SG_ 874 ADS_SrvSys 1152;
BA_ "FlexKomSigStartPos" SG_ 874 ADS_SrvSys 15;
BA_ "FlexKomSigLaenge" SG_ 874 ADS_SrvSys 8;
BA_ "FlexKomSigName" SG_ 874 ADS_SrvSys "ADS_FltMds";
BA_ "FlexKomComment" SG_ 874 ADS_SrvSys "ADS fault modes";
BA_ "FlexKomIsMotorola" SG_ 874 ADS_SrvSys 1;
BA_ "GenSigSNA" SG_ 874 ADS_SrvSys "0h";
BA_ "GenSigSendType" SG_ 880 ECM_APPL3 1;
BA_ "FlexKomSigStartValue" SG_ 880 ECM_APPL3 "0000000000000000h";
BA_ "FlexKomSID" SG_ 880 ECM_APPL3 781;
BA_ "FlexKomSigStartPos" SG_ 880 ECM_APPL3 7;
BA_ "FlexKomSigLaenge" SG_ 880 ECM_APPL3 64;
BA_ "FlexKomSigName" SG_ 880 ECM_APPL3 "ECM_APPL3";
BA_ "FlexKomComment" SG_ 880 ECM_APPL3 "CCP synchronous - TDC event DAQ";
BA_ "FlexKomIsMotorola" SG_ 880 ECM_APPL3 1;
BA_ "GenSigSNA" SG_ 880 ECM_APPL3 "0h";
BA_ "GenSigSendType" SG_ 882 TorqueUnit 5;
BA_ "GenSigCycleTime" SG_ 882 TorqueUnit 1000;
BA_ "FlexKomSigStartValue" SG_ 882 TorqueUnit "00h";
BA_ "FlexKomSID" SG_ 882 TorqueUnit 1998;
BA_ "FlexKomSigStartPos" SG_ 882 TorqueUnit 7;
BA_ "FlexKomSigLaenge" SG_ 882 TorqueUnit 1;
BA_ "FlexKomSigName" SG_ 882 TorqueUnit "TorqueUnit";
BA_ "FlexKomComment" SG_ 882 TorqueUnit "Torque units; Foot Pounds (ft-lb) = [1]";
BA_ "FlexKomIsMotorola" SG_ 882 TorqueUnit 1;
BA_ "GenSigSNA" SG_ 882 TorqueUnit "0h";
BA_ "GenSigSendType" SG_ 882 US_METRIC_C 5;
BA_ "GenSigCycleTime" SG_ 882 US_METRIC_C 1000;
BA_ "FlexKomSigStartValue" SG_ 882 US_METRIC_C "3Eh";
BA_ "FlexKomSID" SG_ 882 US_METRIC_C 1804;
BA_ "FlexKomSigStartPos" SG_ 882 US_METRIC_C 15;
BA_ "FlexKomSigLaenge" SG_ 882 US_METRIC_C 6;
BA_ "FlexKomSigName" SG_ 882 US_METRIC_C "CFG_STAT_C";
BA_ "FlexKomComment" SG_ 882 US_METRIC_C "Configuration status";
BA_ "FlexKomIsMotorola" SG_ 882 US_METRIC_C 1;
BA_ "GenSigSNA" SG_ 882 US_METRIC_C "0h";
BA_ "GenSigSendType" SG_ 882 LANG_C 5;
BA_ "GenSigCycleTime" SG_ 882 LANG_C 1000;
BA_ "FlexKomSigStartValue" SG_ 882 LANG_C "3Eh";
BA_ "GenSigStartValue" SG_ 882 LANG_C 31;
BA_ "GenSigTimeout_CBC" SG_ 882 LANG_C 10500;
BA_ "FlexKomSID" SG_ 882 LANG_C 1804;
BA_ "FlexKomSigStartPos" SG_ 882 LANG_C 15;
BA_ "FlexKomSigLaenge" SG_ 882 LANG_C 6;
BA_ "FlexKomSigName" SG_ 882 LANG_C "CFG_STAT_C";
BA_ "FlexKomComment" SG_ 882 LANG_C "Configuration status";
BA_ "FlexKomIsMotorola" SG_ 882 LANG_C 1;
BA_ "GenSigSNA" SG_ 882 LANG_C "1Fh";
BA_ "GenSigCycleTime" SG_ 882 VehPerfAccelPeak_X 1000;
BA_ "FlexKomSigStartValue" SG_ 882 VehPerfAccelPeak_X "01FEh";
BA_ "GenSigStartValue" SG_ 882 VehPerfAccelPeak_X 510;
BA_ "GenSigTimeout_ETM" SG_ 882 VehPerfAccelPeak_X 10500;
BA_ "FlexKomSID" SG_ 882 VehPerfAccelPeak_X 1900;
BA_ "FlexKomSigStartPos" SG_ 882 VehPerfAccelPeak_X 39;
BA_ "FlexKomSigLaenge" SG_ 882 VehPerfAccelPeak_X 16;
BA_ "FlexKomSigName" SG_ 882 VehPerfAccelPeak_X "VehPerfAccelPeak_X";
BA_ "FlexKomComment" SG_ 882 VehPerfAccelPeak_X "Vehicle longitudinal acceleration peak (+ means fo";
BA_ "FlexKomIsMotorola" SG_ 882 VehPerfAccelPeak_X 1;
BA_ "GenSigSNA" SG_ 882 VehPerfAccelPeak_X "3FFh";
BA_ "GenSigSendType" SG_ 882 PowerUnit 5;
BA_ "GenSigCycleTime" SG_ 882 PowerUnit 1000;
BA_ "FlexKomSigStartValue" SG_ 882 PowerUnit "00h";
BA_ "GenSigTimeout_CBC" SG_ 882 PowerUnit 10500;
BA_ "FlexKomSID" SG_ 882 PowerUnit 1999;
BA_ "FlexKomSigStartPos" SG_ 882 PowerUnit 35;
BA_ "FlexKomSigLaenge" SG_ 882 PowerUnit 2;
BA_ "FlexKomSigName" SG_ 882 PowerUnit "PowerUnit";
BA_ "FlexKomComment" SG_ 882 PowerUnit "Power units";
BA_ "FlexKomIsMotorola" SG_ 882 PowerUnit 1;
BA_ "GenSigSNA" SG_ 882 PowerUnit "0h";
BA_ "GenSigSendType" SG_ 882 PressureUnit 5;
BA_ "GenSigCycleTime" SG_ 882 PressureUnit 1000;
BA_ "FlexKomSigStartValue" SG_ 882 PressureUnit "00h";
BA_ "GenSigTimeout_CBC" SG_ 882 PressureUnit 10500;
BA_ "FlexKomSID" SG_ 882 PressureUnit 2000;
BA_ "FlexKomSigStartPos" SG_ 882 PressureUnit 37;
BA_ "FlexKomSigLaenge" SG_ 882 PressureUnit 2;
BA_ "FlexKomSigName" SG_ 882 PressureUnit "PressureUnit";
BA_ "FlexKomComment" SG_ 882 PressureUnit "Pressure units";
BA_ "FlexKomIsMotorola" SG_ 882 PressureUnit 1;
BA_ "GenSigSNA" SG_ 882 PressureUnit "0h";
BA_ "GenSigSendType" SG_ 882 CapacityUnit 5;
BA_ "GenSigCycleTime" SG_ 882 CapacityUnit 1000;
BA_ "FlexKomSigStartValue" SG_ 882 CapacityUnit "00h";
BA_ "GenSigTimeout_CBC" SG_ 882 CapacityUnit 10500;
BA_ "FlexKomSID" SG_ 882 CapacityUnit 2001;
BA_ "FlexKomSigStartPos" SG_ 882 CapacityUnit 39;
BA_ "FlexKomSigLaenge" SG_ 882 CapacityUnit 2;
BA_ "FlexKomSigName" SG_ 882 CapacityUnit "CapacityUnit";
BA_ "FlexKomComment" SG_ 882 CapacityUnit "Fuel capacity units";
BA_ "FlexKomIsMotorola" SG_ 882 CapacityUnit 1;
BA_ "GenSigSNA" SG_ 882 CapacityUnit "0h";
BA_ "GenSigCycleTime" SG_ 882 VehPerfAccelPeak_Y 1000;
BA_ "FlexKomSigStartValue" SG_ 882 VehPerfAccelPeak_Y "01FEh";
BA_ "GenSigStartValue" SG_ 882 VehPerfAccelPeak_Y 510;
BA_ "GenSigTimeout_ETM" SG_ 882 VehPerfAccelPeak_Y 10500;
BA_ "FlexKomSID" SG_ 882 VehPerfAccelPeak_Y 1899;
BA_ "FlexKomSigStartPos" SG_ 882 VehPerfAccelPeak_Y 55;
BA_ "FlexKomSigLaenge" SG_ 882 VehPerfAccelPeak_Y 16;
BA_ "FlexKomSigName" SG_ 882 VehPerfAccelPeak_Y "VehPerfAccelPeak_Y";
BA_ "FlexKomComment" SG_ 882 VehPerfAccelPeak_Y "Vehicle lateral acceleration peak (+ means left)";
BA_ "FlexKomIsMotorola" SG_ 882 VehPerfAccelPeak_Y 1;
BA_ "GenSigSNA" SG_ 882 VehPerfAccelPeak_Y "3FFh";
BA_ "GenSigSendType" SG_ 882 DistanceUnit 5;
BA_ "GenSigCycleTime" SG_ 882 DistanceUnit 1000;
BA_ "FlexKomSigStartValue" SG_ 882 DistanceUnit "00h";
BA_ "FlexKomSID" SG_ 882 DistanceUnit 2002;
BA_ "FlexKomSigStartPos" SG_ 882 DistanceUnit 50;
BA_ "FlexKomSigLaenge" SG_ 882 DistanceUnit 1;
BA_ "FlexKomSigName" SG_ 882 DistanceUnit "DistanceUnit";
BA_ "FlexKomComment" SG_ 882 DistanceUnit "Distance (odometer) units; Miles = [1]";
BA_ "FlexKomIsMotorola" SG_ 882 DistanceUnit 1;
BA_ "GenSigSNA" SG_ 882 DistanceUnit "0h";
BA_ "GenSigSendType" SG_ 882 SpeedUnit 5;
BA_ "GenSigCycleTime" SG_ 882 SpeedUnit 1000;
BA_ "FlexKomSigStartValue" SG_ 882 SpeedUnit "00h";
BA_ "FlexKomSID" SG_ 882 SpeedUnit 2004;
BA_ "FlexKomSigStartPos" SG_ 882 SpeedUnit 51;
BA_ "FlexKomSigLaenge" SG_ 882 SpeedUnit 1;
BA_ "FlexKomSigName" SG_ 882 SpeedUnit "SpeedUnit";
BA_ "FlexKomComment" SG_ 882 SpeedUnit "Speed (speedometer) units; Miles = [1]";
BA_ "FlexKomIsMotorola" SG_ 882 SpeedUnit 1;
BA_ "GenSigSNA" SG_ 882 SpeedUnit "0h";
BA_ "GenSigSendType" SG_ 882 TemperatureUnit 5;
BA_ "GenSigCycleTime" SG_ 882 TemperatureUnit 1000;
BA_ "FlexKomSigStartValue" SG_ 882 TemperatureUnit "00h";
BA_ "FlexKomSID" SG_ 882 TemperatureUnit 2003;
BA_ "FlexKomSigStartPos" SG_ 882 TemperatureUnit 52;
BA_ "FlexKomSigLaenge" SG_ 882 TemperatureUnit 1;
BA_ "FlexKomSigName" SG_ 882 TemperatureUnit "TemperatureUnit";
BA_ "FlexKomComment" SG_ 882 TemperatureUnit "Temperature units; Farenheit = [1]";
BA_ "FlexKomIsMotorola" SG_ 882 TemperatureUnit 1;
BA_ "GenSigSNA" SG_ 882 TemperatureUnit "0h";
BA_ "GenSigSendType" SG_ 882 ConsumptionUnit 5;
BA_ "GenSigCycleTime" SG_ 882 ConsumptionUnit 1000;
BA_ "FlexKomSigStartValue" SG_ 882 ConsumptionUnit "00h";
BA_ "GenSigTimeout_CBC" SG_ 882 ConsumptionUnit 10500;
BA_ "FlexKomSID" SG_ 882 ConsumptionUnit 2005;
BA_ "FlexKomSigStartPos" SG_ 882 ConsumptionUnit 55;
BA_ "FlexKomSigLaenge" SG_ 882 ConsumptionUnit 3;
BA_ "FlexKomSigName" SG_ 882 ConsumptionUnit "ConsumptionUnit";
BA_ "FlexKomComment" SG_ 882 ConsumptionUnit "Fuel consumption units";
BA_ "FlexKomIsMotorola" SG_ 882 ConsumptionUnit 1;
BA_ "GenSigSNA" SG_ 882 ConsumptionUnit "7h";
BA_ "GenSigSendType" SG_ 888 TCM_HSB 1;
BA_ "FlexKomSigStartValue" SG_ 888 TCM_HSB "0000000000000000h";
BA_ "FlexKomSID" SG_ 888 TCM_HSB 800;
BA_ "FlexKomSigStartPos" SG_ 888 TCM_HSB 7;
BA_ "FlexKomSigLaenge" SG_ 888 TCM_HSB 64;
BA_ "FlexKomSigName" SG_ 888 TCM_HSB "TCM_HSB";
BA_ "FlexKomComment" SG_ 888 TCM_HSB "Manual control at test bench";
BA_ "FlexKomIsMotorola" SG_ 888 TCM_HSB 1;
BA_ "GenSigSNA" SG_ 888 TCM_HSB "0h";
BA_ "GenSigSendType" SG_ 896 ECM_APPL4 1;
BA_ "FlexKomSigStartValue" SG_ 896 ECM_APPL4 "0000000000000000h";
BA_ "FlexKomSID" SG_ 896 ECM_APPL4 782;
BA_ "FlexKomSigStartPos" SG_ 896 ECM_APPL4 7;
BA_ "FlexKomSigLaenge" SG_ 896 ECM_APPL4 64;
BA_ "FlexKomSigName" SG_ 896 ECM_APPL4 "ECM_APPL4";
BA_ "FlexKomComment" SG_ 896 ECM_APPL4 "CCP 5ms DAQ  (from ENGINE to external tool)";
BA_ "FlexKomIsMotorola" SG_ 896 ECM_APPL4 1;
BA_ "GenSigSNA" SG_ 896 ECM_APPL4 "0h";
BA_ "GenSigSendType" SG_ 897 VC_VehCfg7_Stat 5;
BA_ "GenSigCycleTime" SG_ 897 VC_VehCfg7_Stat 2000;
BA_ "FlexKomSigStartValue" SG_ 897 VC_VehCfg7_Stat "033F000000000000h";
BA_ "GenSigStartValue" SG_ 897 VC_VehCfg7_Stat 3;
BA_ "GenSigTimeout_IC" SG_ 897 VC_VehCfg7_Stat 21000;
BA_ "FlexKomSID" SG_ 897 VC_VehCfg7_Stat 2026;
BA_ "FlexKomSigStartPos" SG_ 897 VC_VehCfg7_Stat 7;
BA_ "FlexKomSigLaenge" SG_ 897 VC_VehCfg7_Stat 64;
BA_ "FlexKomSigName" SG_ 897 VC_VehCfg7_Stat "VehCfg7_Pkt";
BA_ "FlexKomComment" SG_ 897 VC_VehCfg7_Stat "Vehicle Configuration 7 Packet";
BA_ "FlexKomIsMotorola" SG_ 897 VC_VehCfg7_Stat 1;
BA_ "GenSigSNA" SG_ 897 VC_VehCfg7_Stat "3h";
BA_ "GenSigSendType" SG_ 897 VC_LDW 5;
BA_ "GenSigCycleTime" SG_ 897 VC_LDW 2000;
BA_ "FlexKomSigStartValue" SG_ 897 VC_LDW "033F000000000000h";
BA_ "FlexKomSID" SG_ 897 VC_LDW 2026;
BA_ "FlexKomSigStartPos" SG_ 897 VC_LDW 7;
BA_ "FlexKomSigLaenge" SG_ 897 VC_LDW 64;
BA_ "FlexKomSigName" SG_ 897 VC_LDW "VehCfg7_Pkt";
BA_ "FlexKomComment" SG_ 897 VC_LDW "Vehicle Configuration 7 Packet";
BA_ "FlexKomIsMotorola" SG_ 897 VC_LDW 1;
BA_ "GenSigSNA" SG_ 897 VC_LDW "0h";
BA_ "GenSigSendType" SG_ 897 VC_TrnsDrvMdPrsnt 5;
BA_ "GenSigCycleTime" SG_ 897 VC_TrnsDrvMdPrsnt 2000;
BA_ "FlexKomSigStartValue" SG_ 897 VC_TrnsDrvMdPrsnt "033F000000000000h";
BA_ "GenSigTimeout_IC" SG_ 897 VC_TrnsDrvMdPrsnt 21000;
BA_ "FlexKomSID" SG_ 897 VC_TrnsDrvMdPrsnt 2026;
BA_ "FlexKomSigStartPos" SG_ 897 VC_TrnsDrvMdPrsnt 7;
BA_ "FlexKomSigLaenge" SG_ 897 VC_TrnsDrvMdPrsnt 64;
BA_ "FlexKomSigName" SG_ 897 VC_TrnsDrvMdPrsnt "VehCfg7_Pkt";
BA_ "FlexKomComment" SG_ 897 VC_TrnsDrvMdPrsnt "Vehicle Configuration 7 Packet";
BA_ "FlexKomIsMotorola" SG_ 897 VC_TrnsDrvMdPrsnt 1;
BA_ "GenSigSNA" SG_ 897 VC_TrnsDrvMdPrsnt "0h";
BA_ "GenSigSendType" SG_ 897 VC_PdlsMdPrsnt 5;
BA_ "GenSigCycleTime" SG_ 897 VC_PdlsMdPrsnt 2000;
BA_ "FlexKomSigStartValue" SG_ 897 VC_PdlsMdPrsnt "033F000000000000h";
BA_ "GenSigTimeout_IC" SG_ 897 VC_PdlsMdPrsnt 21000;
BA_ "FlexKomSID" SG_ 897 VC_PdlsMdPrsnt 2026;
BA_ "FlexKomSigStartPos" SG_ 897 VC_PdlsMdPrsnt 7;
BA_ "FlexKomSigLaenge" SG_ 897 VC_PdlsMdPrsnt 64;
BA_ "FlexKomSigName" SG_ 897 VC_PdlsMdPrsnt "VehCfg7_Pkt";
BA_ "FlexKomComment" SG_ 897 VC_PdlsMdPrsnt "Vehicle Configuration 7 Packet";
BA_ "FlexKomIsMotorola" SG_ 897 VC_PdlsMdPrsnt 1;
BA_ "GenSigSNA" SG_ 897 VC_PdlsMdPrsnt "0h";
BA_ "GenSigSendType" SG_ 897 VC_DST_Present 5;
BA_ "GenSigCycleTime" SG_ 897 VC_DST_Present 2000;
BA_ "FlexKomSigStartValue" SG_ 897 VC_DST_Present "033F000000000000h";
BA_ "FlexKomSID" SG_ 897 VC_DST_Present 2026;
BA_ "FlexKomSigStartPos" SG_ 897 VC_DST_Present 7;
BA_ "FlexKomSigLaenge" SG_ 897 VC_DST_Present 64;
BA_ "FlexKomSigName" SG_ 897 VC_DST_Present "VehCfg7_Pkt";
BA_ "FlexKomComment" SG_ 897 VC_DST_Present "Vehicle Configuration 7 Packet";
BA_ "FlexKomIsMotorola" SG_ 897 VC_DST_Present 1;
BA_ "GenSigSNA" SG_ 897 VC_DST_Present "0h";
BA_ "GenSigSendType" SG_ 897 VC_STP_PRSNT 5;
BA_ "GenSigCycleTime" SG_ 897 VC_STP_PRSNT 2000;
BA_ "FlexKomSigStartValue" SG_ 897 VC_STP_PRSNT "033F000000000000h";
BA_ "GenSigTimeout_IC" SG_ 897 VC_STP_PRSNT 21000;
BA_ "FlexKomSID" SG_ 897 VC_STP_PRSNT 2026;
BA_ "FlexKomSigStartPos" SG_ 897 VC_STP_PRSNT 7;
BA_ "FlexKomSigLaenge" SG_ 897 VC_STP_PRSNT 64;
BA_ "FlexKomSigName" SG_ 897 VC_STP_PRSNT "VehCfg7_Pkt";
BA_ "FlexKomComment" SG_ 897 VC_STP_PRSNT "Vehicle Configuration 7 Packet";
BA_ "FlexKomIsMotorola" SG_ 897 VC_STP_PRSNT 1;
BA_ "GenSigSNA" SG_ 897 VC_STP_PRSNT "0h";
BA_ "GenSigSendType" SG_ 897 VC_eShifter_Prsnt 5;
BA_ "GenSigCycleTime" SG_ 897 VC_eShifter_Prsnt 2000;
BA_ "FlexKomSigStartValue" SG_ 897 VC_eShifter_Prsnt "033F000000000000h";
BA_ "GenSigTimeout_RF_HUB" SG_ 897 VC_eShifter_Prsnt 21000;
BA_ "FlexKomSID" SG_ 897 VC_eShifter_Prsnt 2026;
BA_ "FlexKomSigStartPos" SG_ 897 VC_eShifter_Prsnt 7;
BA_ "FlexKomSigLaenge" SG_ 897 VC_eShifter_Prsnt 64;
BA_ "FlexKomSigName" SG_ 897 VC_eShifter_Prsnt "VehCfg7_Pkt";
BA_ "FlexKomComment" SG_ 897 VC_eShifter_Prsnt "Vehicle Configuration 7 Packet";
BA_ "FlexKomIsMotorola" SG_ 897 VC_eShifter_Prsnt 1;
BA_ "GenSigSNA" SG_ 897 VC_eShifter_Prsnt "0h";
BA_ "GenSigSendType" SG_ 897 VC_TransType 5;
BA_ "GenSigCycleTime" SG_ 897 VC_TransType 2000;
BA_ "FlexKomSigStartValue" SG_ 897 VC_TransType "033F000000000000h";
BA_ "GenSigStartValue" SG_ 897 VC_TransType 63;
BA_ "GenSigTimeout_IC" SG_ 897 VC_TransType 21000;
BA_ "FlexKomSID" SG_ 897 VC_TransType 2026;
BA_ "FlexKomSigStartPos" SG_ 897 VC_TransType 7;
BA_ "FlexKomSigLaenge" SG_ 897 VC_TransType 64;
BA_ "FlexKomSigName" SG_ 897 VC_TransType "VehCfg7_Pkt";
BA_ "FlexKomComment" SG_ 897 VC_TransType "Vehicle Configuration 7 Packet";
BA_ "FlexKomIsMotorola" SG_ 897 VC_TransType 1;
BA_ "GenSigSNA" SG_ 897 VC_TransType "3Fh";
BA_ "GenSigSendType" SG_ 897 VC_AS_ERS 5;
BA_ "GenSigCycleTime" SG_ 897 VC_AS_ERS 2000;
BA_ "FlexKomSigStartValue" SG_ 897 VC_AS_ERS "033F000000000000h";
BA_ "GenSigTimeout_IC" SG_ 897 VC_AS_ERS 21000;
BA_ "FlexKomSID" SG_ 897 VC_AS_ERS 2026;
BA_ "FlexKomSigStartPos" SG_ 897 VC_AS_ERS 7;
BA_ "FlexKomSigLaenge" SG_ 897 VC_AS_ERS 64;
BA_ "FlexKomSigName" SG_ 897 VC_AS_ERS "VehCfg7_Pkt";
BA_ "FlexKomComment" SG_ 897 VC_AS_ERS "Vehicle Configuration 7 Packet";
BA_ "FlexKomIsMotorola" SG_ 897 VC_AS_ERS 1;
BA_ "GenSigSNA" SG_ 897 VC_AS_ERS "3h";
BA_ "GenSigSendType" SG_ 897 VC_FullSpeedRange_FCW 5;
BA_ "GenSigCycleTime" SG_ 897 VC_FullSpeedRange_FCW 2000;
BA_ "FlexKomSigStartValue" SG_ 897 VC_FullSpeedRange_FCW "033F000000000000h";
BA_ "FlexKomSID" SG_ 897 VC_FullSpeedRange_FCW 2026;
BA_ "FlexKomSigStartPos" SG_ 897 VC_FullSpeedRange_FCW 7;
BA_ "FlexKomSigLaenge" SG_ 897 VC_FullSpeedRange_FCW 64;
BA_ "FlexKomSigName" SG_ 897 VC_FullSpeedRange_FCW "VehCfg7_Pkt";
BA_ "FlexKomComment" SG_ 897 VC_FullSpeedRange_FCW "Vehicle Configuration 7 Packet";
BA_ "FlexKomIsMotorola" SG_ 897 VC_FullSpeedRange_FCW 1;
BA_ "GenSigSNA" SG_ 897 VC_FullSpeedRange_FCW "0h";
BA_ "GenSigSendType" SG_ 897 VC_ACC_Type 5;
BA_ "GenSigCycleTime" SG_ 897 VC_ACC_Type 2000;
BA_ "FlexKomSigStartValue" SG_ 897 VC_ACC_Type "033F000000000000h";
BA_ "FlexKomSID" SG_ 897 VC_ACC_Type 2026;
BA_ "FlexKomSigStartPos" SG_ 897 VC_ACC_Type 7;
BA_ "FlexKomSigLaenge" SG_ 897 VC_ACC_Type 64;
BA_ "FlexKomSigName" SG_ 897 VC_ACC_Type "VehCfg7_Pkt";
BA_ "FlexKomComment" SG_ 897 VC_ACC_Type "Vehicle Configuration 7 Packet";
BA_ "FlexKomIsMotorola" SG_ 897 VC_ACC_Type 1;
BA_ "GenSigSNA" SG_ 897 VC_ACC_Type "0h";
BA_ "GenSigSendType" SG_ 897 VC_SuspPrsnt 5;
BA_ "GenSigCycleTime" SG_ 897 VC_SuspPrsnt 2000;
BA_ "FlexKomSigStartValue" SG_ 897 VC_SuspPrsnt "033F000000000000h";
BA_ "GenSigTimeout_IC" SG_ 897 VC_SuspPrsnt 21000;
BA_ "FlexKomSID" SG_ 897 VC_SuspPrsnt 2026;
BA_ "FlexKomSigStartPos" SG_ 897 VC_SuspPrsnt 7;
BA_ "FlexKomSigLaenge" SG_ 897 VC_SuspPrsnt 64;
BA_ "FlexKomSigName" SG_ 897 VC_SuspPrsnt "VehCfg7_Pkt";
BA_ "FlexKomComment" SG_ 897 VC_SuspPrsnt "Vehicle Configuration 7 Packet";
BA_ "FlexKomIsMotorola" SG_ 897 VC_SuspPrsnt 1;
BA_ "GenSigSNA" SG_ 897 VC_SuspPrsnt "0h";
BA_ "GenSigSendType" SG_ 897 VC_DampingPrsnt 5;
BA_ "GenSigCycleTime" SG_ 897 VC_DampingPrsnt 2000;
BA_ "FlexKomSigStartValue" SG_ 897 VC_DampingPrsnt "033F000000000000h";
BA_ "GenSigTimeout_IC" SG_ 897 VC_DampingPrsnt 21000;
BA_ "FlexKomSID" SG_ 897 VC_DampingPrsnt 2026;
BA_ "FlexKomSigStartPos" SG_ 897 VC_DampingPrsnt 7;
BA_ "FlexKomSigLaenge" SG_ 897 VC_DampingPrsnt 64;
BA_ "FlexKomSigName" SG_ 897 VC_DampingPrsnt "VehCfg7_Pkt";
BA_ "FlexKomComment" SG_ 897 VC_DampingPrsnt "Vehicle Configuration 7 Packet";
BA_ "FlexKomIsMotorola" SG_ 897 VC_DampingPrsnt 1;
BA_ "GenSigSNA" SG_ 897 VC_DampingPrsnt "0h";
BA_ "GenSigSendType" SG_ 897 VC_Screen_Off 5;
BA_ "GenSigCycleTime" SG_ 897 VC_Screen_Off 2000;
BA_ "FlexKomSigStartValue" SG_ 897 VC_Screen_Off "033F000000000000h";
BA_ "FlexKomSID" SG_ 897 VC_Screen_Off 2026;
BA_ "FlexKomSigStartPos" SG_ 897 VC_Screen_Off 7;
BA_ "FlexKomSigLaenge" SG_ 897 VC_Screen_Off 64;
BA_ "FlexKomSigName" SG_ 897 VC_Screen_Off "VehCfg7_Pkt";
BA_ "FlexKomComment" SG_ 897 VC_Screen_Off "Vehicle Configuration 7 Packet";
BA_ "FlexKomIsMotorola" SG_ 897 VC_Screen_Off 1;
BA_ "GenSigSNA" SG_ 897 VC_Screen_Off "0h";
BA_ "GenSigSendType" SG_ 898 VC_BU_VehCfg7_Stat 1;
BA_ "FlexKomSigStartValue" SG_ 898 VC_BU_VehCfg7_Stat "033F000000000000h";
BA_ "GenSigStartValue" SG_ 898 VC_BU_VehCfg7_Stat 3;
BA_ "FlexKomSID" SG_ 898 VC_BU_VehCfg7_Stat 2027;
BA_ "FlexKomSigStartPos" SG_ 898 VC_BU_VehCfg7_Stat 7;
BA_ "FlexKomSigLaenge" SG_ 898 VC_BU_VehCfg7_Stat 64;
BA_ "FlexKomSigName" SG_ 898 VC_BU_VehCfg7_Stat "VehCfgBU7_Pkt";
BA_ "FlexKomComment" SG_ 898 VC_BU_VehCfg7_Stat "Backup for vehicle configuration 7 packet";
BA_ "FlexKomIsMotorola" SG_ 898 VC_BU_VehCfg7_Stat 1;
BA_ "GenSigSNA" SG_ 898 VC_BU_VehCfg7_Stat "3h";
BA_ "GenSigSendType" SG_ 898 VC_BU_LDW 1;
BA_ "FlexKomSigStartValue" SG_ 898 VC_BU_LDW "033F000000000000h";
BA_ "FlexKomSID" SG_ 898 VC_BU_LDW 2027;
BA_ "FlexKomSigStartPos" SG_ 898 VC_BU_LDW 7;
BA_ "FlexKomSigLaenge" SG_ 898 VC_BU_LDW 64;
BA_ "FlexKomSigName" SG_ 898 VC_BU_LDW "VehCfgBU7_Pkt";
BA_ "FlexKomComment" SG_ 898 VC_BU_LDW "Backup for vehicle configuration 7 packet";
BA_ "FlexKomIsMotorola" SG_ 898 VC_BU_LDW 1;
BA_ "GenSigSNA" SG_ 898 VC_BU_LDW "0h";
BA_ "GenSigSendType" SG_ 898 VC_BU_TrnsDrvMdPrsnt 1;
BA_ "FlexKomSigStartValue" SG_ 898 VC_BU_TrnsDrvMdPrsnt "033F000000000000h";
BA_ "FlexKomSID" SG_ 898 VC_BU_TrnsDrvMdPrsnt 2027;
BA_ "FlexKomSigStartPos" SG_ 898 VC_BU_TrnsDrvMdPrsnt 7;
BA_ "FlexKomSigLaenge" SG_ 898 VC_BU_TrnsDrvMdPrsnt 64;
BA_ "FlexKomSigName" SG_ 898 VC_BU_TrnsDrvMdPrsnt "VehCfgBU7_Pkt";
BA_ "FlexKomComment" SG_ 898 VC_BU_TrnsDrvMdPrsnt "Backup for vehicle configuration 7 packet";
BA_ "FlexKomIsMotorola" SG_ 898 VC_BU_TrnsDrvMdPrsnt 1;
BA_ "GenSigSNA" SG_ 898 VC_BU_TrnsDrvMdPrsnt "0h";
BA_ "GenSigSendType" SG_ 898 VC_BU_PdlsMdPrsnt 1;
BA_ "FlexKomSigStartValue" SG_ 898 VC_BU_PdlsMdPrsnt "033F000000000000h";
BA_ "FlexKomSID" SG_ 898 VC_BU_PdlsMdPrsnt 2027;
BA_ "FlexKomSigStartPos" SG_ 898 VC_BU_PdlsMdPrsnt 7;
BA_ "FlexKomSigLaenge" SG_ 898 VC_BU_PdlsMdPrsnt 64;
BA_ "FlexKomSigName" SG_ 898 VC_BU_PdlsMdPrsnt "VehCfgBU7_Pkt";
BA_ "FlexKomComment" SG_ 898 VC_BU_PdlsMdPrsnt "Backup for vehicle configuration 7 packet";
BA_ "FlexKomIsMotorola" SG_ 898 VC_BU_PdlsMdPrsnt 1;
BA_ "GenSigSNA" SG_ 898 VC_BU_PdlsMdPrsnt "0h";
BA_ "GenSigSendType" SG_ 898 VC_BU_DST_Present 1;
BA_ "FlexKomSigStartValue" SG_ 898 VC_BU_DST_Present "033F000000000000h";
BA_ "FlexKomSID" SG_ 898 VC_BU_DST_Present 2027;
BA_ "FlexKomSigStartPos" SG_ 898 VC_BU_DST_Present 7;
BA_ "FlexKomSigLaenge" SG_ 898 VC_BU_DST_Present 64;
BA_ "FlexKomSigName" SG_ 898 VC_BU_DST_Present "VehCfgBU7_Pkt";
BA_ "FlexKomComment" SG_ 898 VC_BU_DST_Present "Backup for vehicle configuration 7 packet";
BA_ "FlexKomIsMotorola" SG_ 898 VC_BU_DST_Present 1;
BA_ "GenSigSNA" SG_ 898 VC_BU_DST_Present "0h";
BA_ "GenSigSendType" SG_ 898 VC_BU_STP_PRSNT 1;
BA_ "FlexKomSigStartValue" SG_ 898 VC_BU_STP_PRSNT "033F000000000000h";
BA_ "FlexKomSID" SG_ 898 VC_BU_STP_PRSNT 2027;
BA_ "FlexKomSigStartPos" SG_ 898 VC_BU_STP_PRSNT 7;
BA_ "FlexKomSigLaenge" SG_ 898 VC_BU_STP_PRSNT 64;
BA_ "FlexKomSigName" SG_ 898 VC_BU_STP_PRSNT "VehCfgBU7_Pkt";
BA_ "FlexKomComment" SG_ 898 VC_BU_STP_PRSNT "Backup for vehicle configuration 7 packet";
BA_ "FlexKomIsMotorola" SG_ 898 VC_BU_STP_PRSNT 1;
BA_ "GenSigSNA" SG_ 898 VC_BU_STP_PRSNT "0h";
BA_ "GenSigSendType" SG_ 898 VC_BU_eShifter_Prsnt 1;
BA_ "FlexKomSigStartValue" SG_ 898 VC_BU_eShifter_Prsnt "033F000000000000h";
BA_ "FlexKomSID" SG_ 898 VC_BU_eShifter_Prsnt 2027;
BA_ "FlexKomSigStartPos" SG_ 898 VC_BU_eShifter_Prsnt 7;
BA_ "FlexKomSigLaenge" SG_ 898 VC_BU_eShifter_Prsnt 64;
BA_ "FlexKomSigName" SG_ 898 VC_BU_eShifter_Prsnt "VehCfgBU7_Pkt";
BA_ "FlexKomComment" SG_ 898 VC_BU_eShifter_Prsnt "Backup for vehicle configuration 7 packet";
BA_ "FlexKomIsMotorola" SG_ 898 VC_BU_eShifter_Prsnt 1;
BA_ "GenSigSNA" SG_ 898 VC_BU_eShifter_Prsnt "0h";
BA_ "GenSigSendType" SG_ 898 VC_BU_TransType 1;
BA_ "FlexKomSigStartValue" SG_ 898 VC_BU_TransType "033F000000000000h";
BA_ "GenSigStartValue" SG_ 898 VC_BU_TransType 63;
BA_ "FlexKomSID" SG_ 898 VC_BU_TransType 2027;
BA_ "FlexKomSigStartPos" SG_ 898 VC_BU_TransType 7;
BA_ "FlexKomSigLaenge" SG_ 898 VC_BU_TransType 64;
BA_ "FlexKomSigName" SG_ 898 VC_BU_TransType "VehCfgBU7_Pkt";
BA_ "FlexKomComment" SG_ 898 VC_BU_TransType "Backup for vehicle configuration 7 packet";
BA_ "FlexKomIsMotorola" SG_ 898 VC_BU_TransType 1;
BA_ "GenSigSNA" SG_ 898 VC_BU_TransType "3Fh";
BA_ "GenSigSendType" SG_ 898 VC_BU_AS_ERS 1;
BA_ "FlexKomSigStartValue" SG_ 898 VC_BU_AS_ERS "033F000000000000h";
BA_ "FlexKomSID" SG_ 898 VC_BU_AS_ERS 2027;
BA_ "FlexKomSigStartPos" SG_ 898 VC_BU_AS_ERS 7;
BA_ "FlexKomSigLaenge" SG_ 898 VC_BU_AS_ERS 64;
BA_ "FlexKomSigName" SG_ 898 VC_BU_AS_ERS "VehCfgBU7_Pkt";
BA_ "FlexKomComment" SG_ 898 VC_BU_AS_ERS "Backup for vehicle configuration 7 packet";
BA_ "FlexKomIsMotorola" SG_ 898 VC_BU_AS_ERS 1;
BA_ "GenSigSNA" SG_ 898 VC_BU_AS_ERS "3h";
BA_ "GenSigSendType" SG_ 898 VC_BU_FullSpeedRange_FCW 1;
BA_ "FlexKomSigStartValue" SG_ 898 VC_BU_FullSpeedRange_FCW "033F000000000000h";
BA_ "FlexKomSID" SG_ 898 VC_BU_FullSpeedRange_FCW 2027;
BA_ "FlexKomSigStartPos" SG_ 898 VC_BU_FullSpeedRange_FCW 7;
BA_ "FlexKomSigLaenge" SG_ 898 VC_BU_FullSpeedRange_FCW 64;
BA_ "FlexKomSigName" SG_ 898 VC_BU_FullSpeedRange_FCW "VehCfgBU7_Pkt";
BA_ "FlexKomComment" SG_ 898 VC_BU_FullSpeedRange_FCW "Backup for vehicle configuration 7 packet";
BA_ "FlexKomIsMotorola" SG_ 898 VC_BU_FullSpeedRange_FCW 1;
BA_ "GenSigSNA" SG_ 898 VC_BU_FullSpeedRange_FCW "0h";
BA_ "GenSigSendType" SG_ 898 VC_BU_ACC_Type 1;
BA_ "FlexKomSigStartValue" SG_ 898 VC_BU_ACC_Type "033F000000000000h";
BA_ "FlexKomSID" SG_ 898 VC_BU_ACC_Type 2027;
BA_ "FlexKomSigStartPos" SG_ 898 VC_BU_ACC_Type 7;
BA_ "FlexKomSigLaenge" SG_ 898 VC_BU_ACC_Type 64;
BA_ "FlexKomSigName" SG_ 898 VC_BU_ACC_Type "VehCfgBU7_Pkt";
BA_ "FlexKomComment" SG_ 898 VC_BU_ACC_Type "Backup for vehicle configuration 7 packet";
BA_ "FlexKomIsMotorola" SG_ 898 VC_BU_ACC_Type 1;
BA_ "GenSigSNA" SG_ 898 VC_BU_ACC_Type "0h";
BA_ "GenSigSendType" SG_ 898 VC_BU_SuspPrsnt 1;
BA_ "FlexKomSigStartValue" SG_ 898 VC_BU_SuspPrsnt "033F000000000000h";
BA_ "FlexKomSID" SG_ 898 VC_BU_SuspPrsnt 2027;
BA_ "FlexKomSigStartPos" SG_ 898 VC_BU_SuspPrsnt 7;
BA_ "FlexKomSigLaenge" SG_ 898 VC_BU_SuspPrsnt 64;
BA_ "FlexKomSigName" SG_ 898 VC_BU_SuspPrsnt "VehCfgBU7_Pkt";
BA_ "FlexKomComment" SG_ 898 VC_BU_SuspPrsnt "Backup for vehicle configuration 7 packet";
BA_ "FlexKomIsMotorola" SG_ 898 VC_BU_SuspPrsnt 1;
BA_ "GenSigSNA" SG_ 898 VC_BU_SuspPrsnt "0h";
BA_ "GenSigSendType" SG_ 898 VC_BU_DampingPrsnt 1;
BA_ "FlexKomSigStartValue" SG_ 898 VC_BU_DampingPrsnt "033F000000000000h";
BA_ "FlexKomSID" SG_ 898 VC_BU_DampingPrsnt 2027;
BA_ "FlexKomSigStartPos" SG_ 898 VC_BU_DampingPrsnt 7;
BA_ "FlexKomSigLaenge" SG_ 898 VC_BU_DampingPrsnt 64;
BA_ "FlexKomSigName" SG_ 898 VC_BU_DampingPrsnt "VehCfgBU7_Pkt";
BA_ "FlexKomComment" SG_ 898 VC_BU_DampingPrsnt "Backup for vehicle configuration 7 packet";
BA_ "FlexKomIsMotorola" SG_ 898 VC_BU_DampingPrsnt 1;
BA_ "GenSigSNA" SG_ 898 VC_BU_DampingPrsnt "0h";
BA_ "GenSigSendType" SG_ 898 VC_BU_Screen_Off 1;
BA_ "FlexKomSigStartValue" SG_ 898 VC_BU_Screen_Off "033F000000000000h";
BA_ "FlexKomSID" SG_ 898 VC_BU_Screen_Off 2027;
BA_ "FlexKomSigStartPos" SG_ 898 VC_BU_Screen_Off 7;
BA_ "FlexKomSigLaenge" SG_ 898 VC_BU_Screen_Off 64;
BA_ "FlexKomSigName" SG_ 898 VC_BU_Screen_Off "VehCfgBU7_Pkt";
BA_ "FlexKomComment" SG_ 898 VC_BU_Screen_Off "Backup for vehicle configuration 7 packet";
BA_ "FlexKomIsMotorola" SG_ 898 VC_BU_Screen_Off 1;
BA_ "GenSigSNA" SG_ 898 VC_BU_Screen_Off "0h";
VAL_ 820 OR_SW_PSD 3 "SNA" 2 "PSD" 1 "NDEF1" 0 "NPSD" ;
VAL_ 820 DR_LK_STAT 3 "SNA" 2 "ALL_DR_UNLKD" 1 "DRV_DR_UNLKD" 0 "LKD" ;
VAL_ 820 FOB_SrchRq 2 "RCVD_RSLT" 1 "SEARCH" 0 "NO_ACT" ;
VAL_ 820 WSH_OUT_FLT 1 "SNA" ;
VAL_ 820 IGN_OFF_TIME_LNG 4095 "SNA" ;
VAL_ 820 SHIP_STAT 3 "NOT_PROG" 2 "SHIP_MD" 1 "ABBRV_MD" 0 "CUST_MD" ;
VAL_ 820 PTC_REL1_STAT 3 "SNA" 2 "FLT" 1 "ON" 0 "OFF" ;
VAL_ 820 PTC_REL2_STAT 3 "SNA" 2 "FLT" 1 "ON" 0 "OFF" ;
VAL_ 820 PTC_REL3_STAT 3 "SNA" 2 "FLT" 1 "ON" 0 "OFF" ;
VAL_ 820 PANEL_INTS 255 "SNA" ;
VAL_ 825 PTS_CHIME_TYPE 15 "SNA" 14 "TYP_14" 13 "TYP_13" 12 "TYP_12" 11 "TYP_11" 10 "TYP_10" 9 "TYP_9" 8 "TYP_8" 7 "TYP_7" 6 "TYP_6" 5 "TYP_5" 4 "TYP_4" 3 "TYP_3" 2 "TYP_2" 1 "TYP_1" 0 "NONE" ;
VAL_ 825 PTS_FT_VOL 3 "SNA" 2 "HIGH" 1 "MED" 0 "LOW" ;
VAL_ 825 PTS_RR_VOL 3 "SNA" 2 "HIGH" 1 "MED" 0 "LOW" ;
VAL_ 826 PTS_CFG_STAT 3 "SNA" 2 "SND_DISP" 1 "SND" 0 "OFF" ;
VAL_ 826 PTS_AlrFL 15 "SNA" 8 "ARC8" 7 "ARC7" 6 "ARC6" 5 "ARC5" 4 "ARC4" 3 "ARC3" 2 "ARC2" 1 "ARC1" 0 "PTS_ALR_NOD" ;
VAL_ 826 PTS_SoundFL 3 "None" 2 "CONT_BP_RQ" 1 "FAST_BP_RQ" 0 "SLOW_BP_RQ" ;
VAL_ 826 PTS_GraphicFL 3 "None" 2 "CONT_FLS_RQ" 1 "FAST_FLS_RQ" 0 "SLOW_FLS_RQ" ;
VAL_ 826 PTS_AlrFR 15 "SNA" 8 "ARC8" 7 "ARC7" 6 "ARC6" 5 "ARC5" 4 "ARC4" 3 "ARC3" 2 "ARC2" 1 "ARC1" 0 "PTS_ALR_NOD" ;
VAL_ 826 PTS_SoundFR 3 "None" 2 "CONT_BP_RQ" 1 "FAST_BP_RQ" 0 "SLOW_BP_RQ" ;
VAL_ 826 PTS_GraphicFR 3 "None" 2 "CONT_FLS_RQ" 1 "FAST_FLS_RQ" 0 "SLOW_FLS_RQ" ;
VAL_ 826 PTS_AlrRL 15 "SNA" 8 "ARC8" 7 "ARC7" 6 "ARC6" 5 "ARC5" 4 "ARC4" 3 "ARC3" 2 "ARC2" 1 "ARC1" 0 "PTS_ALR_NOD" ;
VAL_ 826 PTS_SoundRL 3 "None" 2 "CONT_BP_RQ" 1 "FAST_BP_RQ" 0 "SLOW_BP_RQ" ;
VAL_ 826 PTS_GraphicRL 3 "None" 2 "CONT_FLS_RQ" 1 "FAST_FLS_RQ" 0 "SLOW_FLS_RQ" ;
VAL_ 826 PTS_AlrRR 15 "SNA" 8 "ARC8" 7 "ARC7" 6 "ARC6" 5 "ARC5" 4 "ARC4" 3 "ARC3" 2 "ARC2" 1 "ARC1" 0 "PTS_ALR_NOD" ;
VAL_ 826 PTS_SoundRR 3 "None" 2 "CONT_BP_RQ" 1 "FAST_BP_RQ" 0 "SLOW_BP_RQ" ;
VAL_ 826 PTS_GraphicRR 3 "None" 2 "CONT_FLS_RQ" 1 "FAST_FLS_RQ" 0 "SLOW_FLS_RQ" ;
VAL_ 826 PTS_AlrFC 15 "SNA" 8 "ARC8" 7 "ARC7" 6 "ARC6" 5 "ARC5" 4 "ARC4" 3 "ARC3" 2 "ARC2" 1 "ARC1" 0 "PTS_ALR_NOD" ;
VAL_ 826 PTS_SoundFC 3 "None" 2 "CONT_BP_RQ" 1 "FAST_BP_RQ" 0 "SLOW_BP_RQ" ;
VAL_ 826 PTS_GraphicFC 3 "None" 2 "CONT_FLS_RQ" 1 "FAST_FLS_RQ" 0 "SLOW_FLS_RQ" ;
VAL_ 826 PTS_AlrRC 15 "SNA" 8 "ARC8" 7 "ARC7" 6 "ARC6" 5 "ARC5" 4 "ARC4" 3 "ARC3" 2 "ARC2" 1 "ARC1" 0 "PTS_ALR_NOD" ;
VAL_ 826 PTS_SoundRC 3 "None" 2 "CONT_BP_RQ" 1 "FAST_BP_RQ" 0 "SLOW_BP_RQ" ;
VAL_ 826 PTS_GraphicRC 3 "None" 2 "CONT_FLS_RQ" 1 "FAST_FLS_RQ" 0 "SLOW_FLS_RQ" ;
VAL_ 826 PTS_STAT 3 "SNA" 2 "BLINK" 1 "CONT" 0 "OFF" ;
VAL_ 828 PSG_RBT_Fault 1 "SNA" ;
VAL_ 828 PSG_RBT_ACT 3 "SNA" 2 "ACT_ESC" 1 "ACT_DASM" 0 "DEFAULT" ;
VAL_ 831 FL_Lvl 255 "SNA" 254 "NOT_INIT" ;
VAL_ 831 FR_Lvl 255 "SNA" 254 "NOT_INIT" ;
VAL_ 831 RL_Lvl 255 "SNA" 254 "NOT_INIT" ;
VAL_ 831 RR_Lvl 255 "SNA" 254 "NOT_INIT" ;
VAL_ 832 VehAccelPeak_X 255 "SNA" ;
VAL_ 832 VehAccelPeak_Y 255 "SNA" ;
VAL_ 832 VehSpdDisp 65535 "SNA" ;
VAL_ 836 SPCR_CHIME_TYPE 15 "SNA" 14 "TYP_14" 13 "TYP_13" 12 "TYP_12" 11 "TYP_11" 10 "TYP_10" 9 "TYP_9" 8 "TYP_8" 7 "TYP_7" 6 "TYP_6" 5 "TYP_5" 4 "TYP_4" 3 "TYP_3" 2 "TYP_2" 1 "TYP_1" 0 "NONE" ;
VAL_ 838 AS_CHIME_TYPE 15 "SNA" 14 "TYP_14" 13 "TYP_13" 12 "TYP_12" 11 "TYP_11" 10 "TYP_10" 9 "TYP_9" 8 "TYP_8" 7 "TYP_7" 6 "TYP_6" 5 "TYP_5" 4 "TYP_4" 3 "TYP_3" 2 "TYP_2" 1 "TYP_1" 0 "NONE" ;
VAL_ 840 FailSafeError 65535 "SNA" ;
VAL_ 844 ASCM_Stat 15 "SNA" 11 "SRVS" 10 "RL_INT" 9 "LOWER" 8 "RAISE" 7 "EEHNA" 6 "ORL2" 5 "OR1" 4 "NVL" 3 "AERO" 2 "PARK" 1 "DUMP" 0 "NO_MESS" ;
VAL_ 844 ASCM_StatDisp 15 "SNA" 14 "ASCM_LNP_MINLoad" 13 "ASCM_LNP_PAYLOAD" 12 "ASCM_LNP_SPEED" 11 "LNA_OL" 10 "RL_INT" 9 "LML" 8 "LMR" 7 "EEHNA" 6 "ORL2" 5 "OR1" 4 "NVL" 3 "AERO" 2 "PARK" 1 "DUMP" 0 "NO_MESS" ;
VAL_ 844 ASCM_HMI_Stat 15 "SNA" 14 "ASCM_AeroDslb" 13 "ASCM_WarnONly" 12 "ALM_Enbl" 11 "TM_Enbl" 10 "ASCM_Highlr" 9 "ASCM_LowClr" 8 "ASCM_TJM_Disp" 7 "ASCM_VLSt" 6 "ASCM_SysFail" 5 "ASCM_Srv" 4 "ASCM_Dr" 3 "ASCM_Cooldn" 2 "ASCM_LvlnPrmt" 1 "ASCM_RedSpd" 0 "NONE" ;
VAL_ 844 Tgt_Level 7 "SNA" 5 "ORL2" 4 "OR1" 3 "STD" 2 "AERO" 1 "Park" 0 "TR_Dump" ;
VAL_ 844 Loading_Lv 7 "SNA" 6 "MIP" 5 "OVERLOAD_2" 4 "OVERLOAD_1" 3 "FULL" 2 "MEDIUM" 1 "LIGHT" 0 "LND" ;
VAL_ 844 ASCM_RemStat 3 "SNA" 2 "DISABLE" 1 "ACTIVE" 0 "NONE" ;
VAL_ 844 ASCM_OR2_Rq 3 "SNA" 2 "BLINK" 1 "CONT" 0 "OFF" ;
VAL_ 844 ASCM_OR1_Rq 3 "SNA" 2 "BLINK" 1 "CONT" 0 "OFF" ;
VAL_ 844 ASCM_Norm_Rq 3 "SNA" 2 "BLINK" 1 "CONT" 0 "OFF" ;
VAL_ 844 ASCM_Exit_Rq 3 "SNA" 2 "BLINK" 1 "CONT" 0 "OFF" ;
VAL_ 844 LvlAdjStat 3 "RL_INT" 2 "LOWER" 1 "RAISE" 0 "STATIC" ;
VAL_ 847 RF_FobNum 15 "SNA" 8 "FOB_8" 7 "FOB_7" 6 "FOB_6" 5 "FOB_5" 4 "FOB_4" 3 "FOB_3" 2 "FOB_2" 1 "FOB_1" 0 "FOB_DEFAULT" ;
VAL_ 848 DateTmSec 255 "SNA" ;
VAL_ 848 DateTmMinute 255 "SNA" ;
VAL_ 848 DateTmHour 255 "SNA" ;
VAL_ 848 DateTmYear 65535 "SNA" ;
VAL_ 848 DateTmMonth 255 "SNA" ;
VAL_ 848 DateTmDay 255 "SNA" ;
VAL_ 848 DateTmFormat 7 "SNA" 6 "FORMAT_3" 5 "FORMAT_2" 4 "FORMAT_1" 3 "FORMAT_0" 2 "FORMAT_24H" 1 "FORMAT_12H" 0 "NDEF0" ;
VAL_ 853 TERRAIN_RQ 3 "SNA" 2 "LEFT_RQ" 1 "RIGHT_RQ" 0 "NO_RQ" ;
VAL_ 853 TCASE_RQ 3 "SNA" 2 "NDEF2" 1 "PSD" 0 "NPSD" ;
VAL_ 853 TCASE_NEUT_RQ 3 "SNA" 2 "NDEF2" 1 "PSD" 0 "NPSD" ;
VAL_ 853 Tcase2WD_Rq 3 "SNA" 2 "NDEF2" 1 "PSD" 0 "NPSD" ;
VAL_ 853 TcaseAWD_Rq 3 "SNA" 2 "NDEF2" 1 "PSD" 0 "NPSD" ;
VAL_ 853 Tcase4Lock_Rq 3 "SNA" 2 "NDEF2" 1 "PSD" 0 "NPSD" ;
VAL_ 853 Tcase4Low_Rq 3 "SNA" 2 "NDEF2" 1 "PSD" 0 "NPSD" ;
VAL_ 853 TcaseSwTyp 3 "SNA" 1 "PB" 0 "ROT" ;
VAL_ 853 SuspSwPsd 3 "SNA" 1 "PSD" 0 "NOT_PSD" ;
VAL_ 853 PARK_ASST_RQ 3 "SNA" 1 "PSD" 0 "NOT_PSD" ;
VAL_ 853 UGDO_CHNL 7 "SNA" 3 "UGDO3" 2 "UGDO2" 1 "UGDO1" 0 "UGDO_NONE" ;
VAL_ 853 UGDO_STAT 15 "SNA" 7 "UGDO_DEF" 6 "UGDO_CLRD" 5 "UGDO_CLRNG" 4 "UGDO_DNT" 3 "UGDO_TRND" 2 "UGDO_TRNG" 1 "UGDO_TXMT" 0 "UGDO_NOPRS" ;
VAL_ 853 Converter_2_Mode 3 "NA" 2 "TEST" 1 "END_OF_LINE" 0 "NORMAL" ;
VAL_ 853 Converter_2_State 3 "TEMP_PREWARN" 2 "ERROR" 1 "STAND_BY" 0 "ACTIVE" ;
VAL_ 853 FT_PARK_ASST_RQ 3 "SNA" 1 "PSD" 0 "NOT_PSD" ;
VAL_ 853 SpSt_Pad1 7 "SNA" 4 "IND" 3 "S_PLUS" 2 "S_GND" 1 "PSD" 0 "UN_PSD" ;
VAL_ 853 SpSt_Pad2 7 "SNA" 4 "IND" 3 "S_PLUS" 2 "S_GND" 1 "PSD" 0 "UN_PSD" ;
VAL_ 853 IBS_IBATT_QUIESCENT 255 "SNA" 254 "MEAS_GT_1A" 253 "MEAS_NOT_DONE" ;
VAL_ 856 CMP_DIR 15 "SNA" 8 "NONE" 7 "CMP_N_W" 6 "CMP_W" 5 "CMP_S_W" 4 "CMP_S" 3 "CMP_S_E" 2 "CMP_E" 1 "CMP_N_E" 0 "CMP_N" ;
VAL_ 856 VAR_VAL 15 "SNA_Default" ;
VAL_ 856 CMP_DIR_RAW 511 "SNA_Default" ;
VAL_ 860 DIST_TO_TURN 65535 "SNA" ;
VAL_ 860 UNITS 7 "SNA" 5 "YARD" 4 "METER" 3 "KM" 2 "FEET" 1 "MILE" 0 "NO_UNITS" ;
VAL_ 860 NAV_ARROW 0 "NAV_NOT_ACT" ;
VAL_ 860 HU_CMP 15 "SNA" 8 "NONE" 7 "CMP_N_W" 6 "CMP_W" 5 "CMP_S_W" 4 "CMP_S" 3 "CMP_S_E" 2 "CMP_E" 1 "CMP_N_E" 0 "CMP_N" ;
VAL_ 860 HU_CMP_RAW 255 "SNA" ;
VAL_ 863 PSI_Gr1_RPM 31 "SNA" ;
VAL_ 863 PSI_Gr2_RPM 31 "SNA" ;
VAL_ 863 PSI_Gr3_RPM 31 "SNA" ;
VAL_ 863 PSI_Gr4_RPM 31 "SNA" ;
VAL_ 863 PSI_Gr5_RPM 31 "SNA" ;
VAL_ 863 ECM_MSG_RQ 31 "SNA" 30 "SCREEN_30" 29 "SCREEN_29" 28 "SCREEN_28" 27 "SCREEN_27" 26 "SCREEN_26" 25 "SCREEN_25" 24 "SCREEN_24" 23 "SCREEN_23" 22 "SCREEN_22" 21 "SCREEN_21" 20 "SCREEN_20" 19 "SCREEN_19" 18 "SCREEN_18" 17 "SCREEN_17" 16 "SCREEN_16" 15 "SCREEN_15" 14 "SCREEN_14" 13 "SCREEN_13" 12 "SCREEN_12" 11 "SCREEN_11" 10 "SCREEN_10" 9 "SCREEN_9" 8 "SCREEN_8" 7 "SCREEN_7" 6 "SCREEN_6" 5 "SCREEN_5" 4 "SCREEN_4" 3 "SCREEN_3" 2 "SCREEN_2" 1 "SCREEN_1" 0 "NONE" ;
VAL_ 863 RevOilLifeRst 65535 "SNA" ;
VAL_ 874 ADC_Stat 3 "SNA" 2 "MODE_3" 1 "MODE_2" 0 "MODE_1" ;
VAL_ 874 ADS_MODE_CFG_Stat 3 "SNA" 2 "MODE_3" 1 "MODE_2" 0 "MODE_1" ;
VAL_ 882 LANG_C 31 "LANG_NO_CHG" 17 "POLISH" 16 "TURKISH" 15 "HINDI" 14 "MANDARIN_T" 13 "BRAZILIAN" 12 "ARABIC" 11 "KOREAN" 10 "RUSSIAN" 9 "MANDARIN_S" 8 "UK_ENGLISH" 7 "DUTCH" 6 "PORTUGESE" 5 "JAPANESE" 4 "SPANISH" 3 "ITALIAN" 2 "FRENCH" 1 "US_ENGLISH" 0 "GERMAN" ;
VAL_ 882 VehPerfAccelPeak_X 1023 "SNA" ;
VAL_ 882 PowerUnit 2 "HP_US" 1 "HP_UK" 0 "KW" ;
VAL_ 882 PressureUnit 2 "PSI" 1 "BAR" 0 "KPA" ;
VAL_ 882 CapacityUnit 2 "G_US" 1 "G_UK" 0 "L" ;
VAL_ 882 VehPerfAccelPeak_Y 1023 "SNA" ;
VAL_ 882 ConsumptionUnit 7 "SNA" 3 "MPG_US" 2 "MPG_UK" 1 "LP100KM" 0 "KMPL" ;
VAL_ 897 VC_VehCfg7_Stat 3 "SNA" 2 "REQUEST_DATA" 1 "PROGAMMED" 0 "NA" ;
VAL_ 897 VC_TransType 63 "SNA" 14 "ZF_9Spd" 13 "ZF_8Spd" 12 "HPT_6F24" 11 "DDCT_C635" 10 "AISIN_HD" 9 "c68RFE" 8 "c66RFE" 7 "c65RFE" 6 "c62TE" 5 "W5A580" 4 "Aisin_LD" 3 "c40TES" 2 "MTA" 1 "MANUAL" 0 "NP" ;
VAL_ 897 VC_AS_ERS 3 "SNA" 2 "AS" 1 "ERS" 0 "NONE" ;
VAL_ 897 VC_ACC_Type 3 "GO" 2 "STOP" 1 "ACC" 0 "NONE" ;
VAL_ 898 VC_BU_VehCfg7_Stat 3 "SNA" 2 "NA1" 1 "PROGAMMED" 0 "NA" ;
VAL_ 898 VC_BU_TransType 63 "SNA" 14 "ZF_9Spd" 13 "ZF_8Spd" 12 "HPT_6F24" 11 "DDCT_C635" 10 "AISIN_HD" 9 "c68RFE" 8 "c66RFE" 7 "c65RFE" 6 "c62TE" 5 "W5A580" 4 "Aisin_LD" 3 "c40TES" 2 "MTA" 1 "MANUAL" 0 "NP" ;
VAL_ 898 VC_BU_AS_ERS 3 "SNA" 2 "AS" 1 "ERS" 0 "NONE" ;
VAL_ 898 VC_BU_ACC_Type 3 "GO" 2 "STOP" 1 "ACC" 0 "NONE" ;
